VERSION ""

NS_ :

BS_:

BU_:BMS FCS VCU
BO_ 2550595737 BatP9_BMS_ChargingInfo: 8 BMS
 SG_ P9_ChrgrCplrStat : 7|1@0+ (1,0) [0|1] "" VCU
 SG_ P9_HVBattChrgSysStatus : 6|4@0+ (1,0) [0|15] "" VCU
 SG_ P9_DCChrgCrntCmd : 2|9@0+ (1,0) [0|500] "A" VCU
 SG_ P9_CC2Vlt : 9|8@0+ (0.1,0) [0|25] "V" VCU
 SG_ P9_DCRcptPosTemp : 17|9@0+ (0.5,-40) [-40|150] "C" VCU
 SG_ P9_DCRcptNegTemp : 24|9@0+ (0.5,-40) [-40|150] "C" VCU
 SG_ P9_Tm2FullChrg : 47|14@0+ (1,0) [0|65535] "min" VCU

BO_ 2550661273 BatP9_BMS_ThermalManagement: 8 BMS
 SG_ P9_Inlet1ClntTemp : 7|11@0+ (0.1,-40) [-40|150] "C" VCU
 SG_ P9_Inlet2ClntTemp : 12|11@0+ (0.1,-40) [-40|150] "C" VCU
 SG_ P9_Outlet1ClntTemp : 17|11@0+ (0.1,-40) [-40|150] "C" VCU
 SG_ P9_Outlet2ClntTemp : 38|11@0+ (0.1,-40) [-40|150] "C" VCU
 SG_ P9_TrgtClntTemp : 43|11@0+ (0.1,-40) [-40|150] "C" VCU
 SG_ P9_TrgtClntFlowRate : 48|9@0+ (0.2,0) [0|100] "C" VCU

BO_ 2550726809 BatP9_BMS_CellVoltMaxMin: 8 BMS
 SG_ P9_MaxCellVlt : 7|13@0+ (0.001,0) [0|5] "V" VCU
 SG_ P9_MaxCellVltNum : 10|9@0+ (1,0) [0|500] "" VCU
 SG_ P9_MinCellVlt : 17|13@0+ (0.001,0) [0|5] "V" VCU
 SG_ P9_MinCellVltNum : 36|9@0+ (1,0) [0|500] "" VCU
 SG_ P9_AvgCellVlt : 43|13@0+ (0.001,0) [0|5] "V" VCU

BO_ 2550792345 BatP9_BMS_CellTempMaxMin: 8 BMS
 SG_ P9_MaxCellTemp : 7|11@0+ (0.1,-40) [-40|150] "C" VCU
 SG_ P9_MaxCellTempNum : 12|9@0+ (1,0) [0|500] "" VCU
 SG_ P9_MinCellTemp : 19|11@0+ (0.1,-40) [-40|150] "C" VCU
 SG_ P9_MinCellTempNum : 24|9@0+ (1,0) [0|500] "" VCU
 SG_ P9_AvgCellTemp : 47|11@0+ (0.1,-40) [-40|150] "C" VCU

BO_ 2550857881 BatP9_BMS_PackFaultInfo1: 8 BMS
 SG_ P9_PackTotFltNum : 7|8@0+ (1,0) [0|200] "" VCU
 SG_ P9_CellOverVoltage : 15|2@0+ (1,0) [0|3] "" VCU
 SG_ P9_CellUnderVoltage : 13|2@0+ (1,0) [0|3] "" VCU
 SG_ P9_CellVoltageDiffHi : 11|1@0+ (1,0) [0|1] "" VCU
 SG_ P9_PackOverVoltage : 10|2@0+ (1,0) [0|3] "" VCU
 SG_ P9_PackUnderVoltage : 8|2@0+ (1,0) [0|3] "" VCU
 SG_ P9_CellOverTemp : 22|2@0+ (1,0) [0|3] "" VCU
 SG_ P9_CellTempLow : 20|1@0+ (1,0) [0|1] "" VCU
 SG_ P9_CellTempDiffHi : 19|1@0+ (1,0) [0|1] "" VCU
 SG_ P9_PackDschrgCrntHi : 18|2@0+ (1,0) [0|3] "" VCU
 SG_ P9_PackChrgCrntHi : 16|2@0+ (1,0) [0|3] "" VCU
 SG_ P9_PackCrnSnsr1OffsetHi : 30|1@0+ (1,0) [0|1] "" VCU
 SG_ P9_HVIsolFlt : 29|2@0+ (1,0) [0|3] "" VCU
 SG_ P9_HVILFlt : 27|1@0+ (1,0) [0|1] "" VCU
 SG_ P9_ThrmlRunaway : 26|1@0+ (1,0) [0|1] "" VCU
 SG_ P9_CellVoltInvalid : 25|1@0+ (1,0) [0|1] "" VCU
 SG_ P9_CellTempInvalid : 24|1@0+ (1,0) [0|1] "" VCU
 SG_ P9_DaisyChainComFlt : 39|1@0+ (1,0) [0|1] "" VCU
 SG_ P9_PackVoltRatFlt : 38|1@0+ (1,0) [0|1] "" VCU
 SG_ P9_CrntSnsr1Invalid : 37|1@0+ (1,0) [0|1] "" VCU
 SG_ P9_CrntSnsr1OOR : 36|1@0+ (1,0) [0|1] "" VCU
 SG_ P9_CrntSnsr2Invalid : 35|1@0+ (1,0) [0|1] "" VCU
 SG_ P9_CrntSnsr2OOR : 34|1@0+ (1,0) [0|1] "" VCU
 SG_ P9_PackCrnSnsr2OffsetHi : 33|1@0+ (1,0) [0|1] "" VCU
 SG_ P9_OutofEnergy : 32|1@0+ (1,0) [0|1] "" VCU
 SG_ P9_IsolDetCircErr : 47|1@0+ (1,0) [0|1] "" VCU
 SG_ P9_HVILCircShortToGND : 46|1@0+ (1,0) [0|1] "" VCU
 SG_ P9_HVILCircShortToPwr : 45|1@0+ (1,0) [0|1] "" VCU

BO_ 2550923417 BatP9_BMS_PackFaultInfo2: 8 BMS
 SG_ P9_MainPosCntctrStkClsd : 7|1@0+ (1,0) [0|1] "" VCU
 SG_ P9_MainPosCntctrStkOpn : 6|1@0+ (1,0) [0|1] "" VCU
 SG_ P9_MainNegCntctr1StkClsd : 5|1@0+ (1,0) [0|1] "" VCU
 SG_ P9_MainNegCntctr1StkOpn : 4|1@0+ (1,0) [0|1] "" VCU
 SG_ P9_MainNegCntctr2StkClsd : 3|1@0+ (1,0) [0|1] "" VCU
 SG_ P9_MainNegCntctr2StkOpn : 2|1@0+ (1,0) [0|1] "" VCU
 SG_ P9_PrechargTmOut : 1|1@0+ (1,0) [0|1] "" VCU
 SG_ P9_PrechrgCrntHi : 0|1@0+ (1,0) [0|1] "" VCU
 SG_ P9_ChrgCplrPosTempHi : 15|1@0+ (1,0) [0|1] "" VCU
 SG_ P9_ChrgCplrNegTempHi : 14|1@0+ (1,0) [0|1] "" VCU
 SG_ P9_BMSPwrSuplVlt1Hi : 13|1@0+ (1,0) [0|1] "" VCU
 SG_ P9_BMSPwrSuplVlt1Lo : 12|1@0+ (1,0) [0|1] "" VCU
 SG_ P9_BMSPwrSuplVlt2Hi : 11|1@0+ (1,0) [0|1] "" VCU
 SG_ P9_BMSPwrSuplVlt2Lo : 10|1@0+ (1,0) [0|1] "" VCU
 SG_ P9_CntctrCirPwrSuplVltLo : 9|1@0+ (1,0) [0|1] "" VCU
 SG_ P9_CntctrCirPwrSuplVltHi : 8|1@0+ (1,0) [0|1] "" VCU
 SG_ P9_CAN1BusOff : 23|1@0+ (1,0) [0|1] "" VCU
 SG_ P9_CAN1BusTmOut : 22|1@0+ (1,0) [0|1] "" VCU
 SG_ P9_CAN2BusOff : 21|1@0+ (1,0) [0|1] "" VCU
 SG_ P9_CAN2BusTmOut : 20|1@0+ (1,0) [0|1] "" VCU
 SG_ P9_CellBalCircTempHi : 19|1@0+ (1,0) [0|1] "" VCU
 SG_ P9_ClntInTempHi : 18|1@0+ (1,0) [0|1] "" VCU
 SG_ P9_ClntOutTempHi : 17|1@0+ (1,0) [0|1] "" VCU
 SG_ P9_CellExtrmUdrVolt : 16|1@0+ (1,0) [0|1] "" VCU
 SG_ P9_CellExtrmOvrVolt : 31|1@0+ (1,0) [0|1] "" VCU
 SG_ P9_Branch1DischrgCrntHi  : 30|1@0+ (1,0) [0|1] "" VCU
 SG_ P9_Branch2DischrgCrntHi  : 29|1@0+ (1,0) [0|1] "" VCU
 SG_ P9_Branch1ChrgCrntHi  : 28|1@0+ (1,0) [0|1] "" VCU
 SG_ P9_Branch2ChrgCrntHi  : 27|1@0+ (1,0) [0|1] "" VCU
 SG_ P9_InitFailed : 26|1@0+ (1,0) [0|1] "" VCU
 SG_ P9_PackErrCode : 25|10@0+ (1,0) [0|1023] "" VCU

BO_ 2550988953 BatP9_BMS_PackConfigInfo: 8 BMS
 SG_ P9_PackTotCellNum : 7|9@0+ (1,0) [0|500] "" VCU
 SG_ P9_PackTotCellTempSnsrNum : 14|9@0+ (1,0) [0|500] "" VCU

BO_ 2552299673 BatP9_BMS_BMSVersion: 8 BMS
 SG_ P9_BMSASWMajVerNum : 7|8@0+ (1,0) [0|9] "" VCU
 SG_ P9_BMSASWMinVerNum : 15|8@0+ (1,0) [0|99] "" VCU
 SG_ P9_BMSASWPatchVerNum : 23|8@0+ (1,0) [0|255] "" VCU
 SG_ P9_BMSBSWMajVerNum : 31|8@0+ (1,0) [0|9] "" VCU
 SG_ P9_BMSBSWMinVerNum : 39|8@0+ (1,0) [0|99] "" VCU
 SG_ P9_BMSBSWPatchVerNum : 47|8@0+ (1,0) [0|255] "" VCU

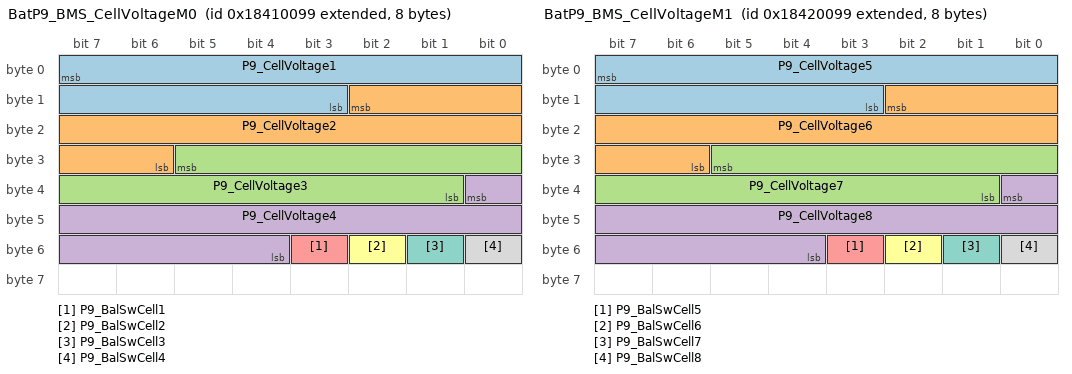
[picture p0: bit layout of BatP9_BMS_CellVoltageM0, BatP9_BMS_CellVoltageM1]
BO_ 2554396825 BatP9_BMS_CellVoltageM0: 8 BMS
 SG_ P9_CellVoltage1 : 7|13@0+ (0.001,0) [0|5] "V" VCU
 SG_ P9_CellVoltage2 : 10|13@0+ (0.001,0) [0|5] "V" VCU
 SG_ P9_CellVoltage3 : 29|13@0+ (0.001,0) [0|5] "V" VCU
 SG_ P9_CellVoltage4 : 32|13@0+ (0.001,0) [0|5] "V" VCU
 SG_ P9_BalSwCell1 : 51|1@0+ (1,0) [0|1] "" VCU
 SG_ P9_BalSwCell2 : 50|1@0+ (1,0) [0|1] "" VCU
 SG_ P9_BalSwCell3 : 49|1@0+ (1,0) [0|1] "" VCU
 SG_ P9_BalSwCell4 : 48|1@0+ (1,0) [0|1] "" VCU

BO_ 2554462361 BatP9_BMS_CellVoltageM1: 8 BMS
 SG_ P9_CellVoltage5 : 7|13@0+ (0.001,0) [0|5] "V" VCU
 SG_ P9_CellVoltage6 : 10|13@0+ (0.001,0) [0|5] "V" VCU
 SG_ P9_CellVoltage7 : 29|13@0+ (0.001,0) [0|5] "V" VCU
 SG_ P9_CellVoltage8 : 32|13@0+ (0.001,0) [0|5] "V" VCU
 SG_ P9_BalSwCell5 : 51|1@0+ (1,0) [0|1] "" VCU
 SG_ P9_BalSwCell6 : 50|1@0+ (1,0) [0|1] "" VCU
 SG_ P9_BalSwCell7 : 49|1@0+ (1,0) [0|1] "" VCU
 SG_ P9_BalSwCell8 : 48|1@0+ (1,0) [0|1] "" VCU

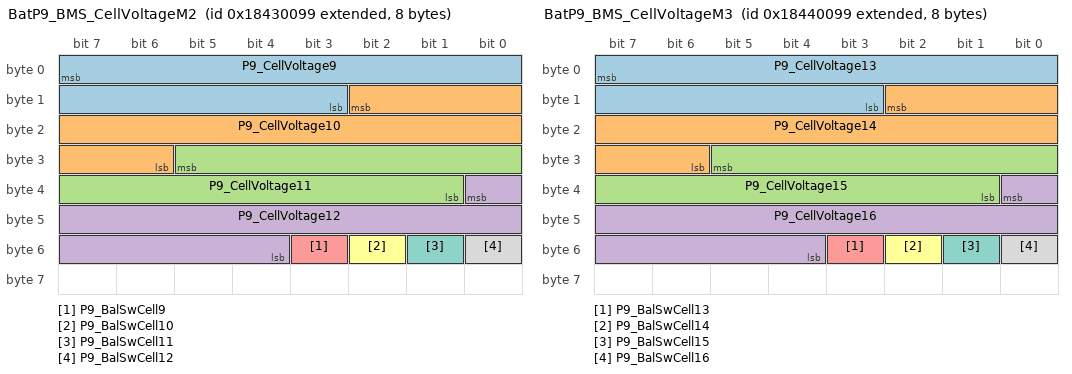
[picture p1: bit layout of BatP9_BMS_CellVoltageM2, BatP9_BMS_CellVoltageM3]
BO_ 2554527897 BatP9_BMS_CellVoltageM2: 8 BMS
 SG_ P9_CellVoltage9 : 7|13@0+ (0.001,0) [0|5] "V" VCU
 SG_ P9_CellVoltage10 : 10|13@0+ (0.001,0) [0|5] "V" VCU
 SG_ P9_CellVoltage11 : 29|13@0+ (0.001,0) [0|5] "V" VCU
 SG_ P9_CellVoltage12 : 32|13@0+ (0.001,0) [0|5] "V" VCU
 SG_ P9_BalSwCell9 : 51|1@0+ (1,0) [0|1] "" VCU
 SG_ P9_BalSwCell10 : 50|1@0+ (1,0) [0|1] "" VCU
 SG_ P9_BalSwCell11 : 49|1@0+ (1,0) [0|1] "" VCU
 SG_ P9_BalSwCell12 : 48|1@0+ (1,0) [0|1] "" VCU

BO_ 2554593433 BatP9_BMS_CellVoltageM3: 8 BMS
 SG_ P9_CellVoltage13 : 7|13@0+ (0.001,0) [0|5] "V" VCU
 SG_ P9_CellVoltage14 : 10|13@0+ (0.001,0) [0|5] "V" VCU
 SG_ P9_CellVoltage15 : 29|13@0+ (0.001,0) [0|5] "V" VCU
 SG_ P9_CellVoltage16 : 32|13@0+ (0.001,0) [0|5] "V" VCU
 SG_ P9_BalSwCell13 : 51|1@0+ (1,0) [0|1] "" VCU
 SG_ P9_BalSwCell14 : 50|1@0+ (1,0) [0|1] "" VCU
 SG_ P9_BalSwCell15 : 49|1@0+ (1,0) [0|1] "" VCU
 SG_ P9_BalSwCell16 : 48|1@0+ (1,0) [0|1] "" VCU

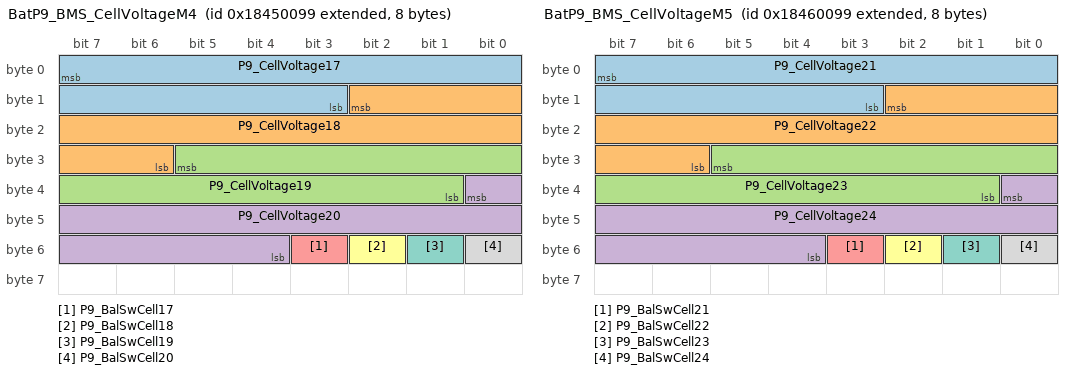
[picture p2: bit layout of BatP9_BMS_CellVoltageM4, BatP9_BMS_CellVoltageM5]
BO_ 2554658969 BatP9_BMS_CellVoltageM4: 8 BMS
 SG_ P9_CellVoltage17 : 7|13@0+ (0.001,0) [0|5] "V" VCU
 SG_ P9_CellVoltage18 : 10|13@0+ (0.001,0) [0|5] "V" VCU
 SG_ P9_CellVoltage19 : 29|13@0+ (0.001,0) [0|5] "V" VCU
 SG_ P9_CellVoltage20 : 32|13@0+ (0.001,0) [0|5] "V" VCU
 SG_ P9_BalSwCell17 : 51|1@0+ (1,0) [0|1] "" VCU
 SG_ P9_BalSwCell18 : 50|1@0+ (1,0) [0|1] "" VCU
 SG_ P9_BalSwCell19 : 49|1@0+ (1,0) [0|1] "" VCU
 SG_ P9_BalSwCell20 : 48|1@0+ (1,0) [0|1] "" VCU

BO_ 2554724505 BatP9_BMS_CellVoltageM5: 8 BMS
 SG_ P9_CellVoltage21 : 7|13@0+ (0.001,0) [0|5] "V" VCU
 SG_ P9_CellVoltage22 : 10|13@0+ (0.001,0) [0|5] "V" VCU
 SG_ P9_CellVoltage23 : 29|13@0+ (0.001,0) [0|5] "V" VCU
 SG_ P9_CellVoltage24 : 32|13@0+ (0.001,0) [0|5] "V" VCU
 SG_ P9_BalSwCell21 : 51|1@0+ (1,0) [0|1] "" VCU
 SG_ P9_BalSwCell22 : 50|1@0+ (1,0) [0|1] "" VCU
 SG_ P9_BalSwCell23 : 49|1@0+ (1,0) [0|1] "" VCU
 SG_ P9_BalSwCell24 : 48|1@0+ (1,0) [0|1] "" VCU

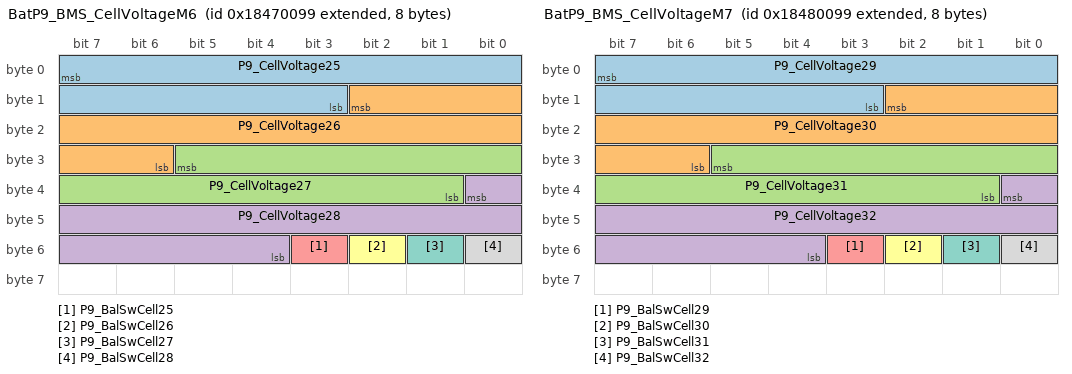
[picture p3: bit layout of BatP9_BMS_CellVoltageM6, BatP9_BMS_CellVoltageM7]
BO_ 2554790041 BatP9_BMS_CellVoltageM6: 8 BMS
 SG_ P9_CellVoltage25 : 7|13@0+ (0.001,0) [0|5] "V" VCU
 SG_ P9_CellVoltage26 : 10|13@0+ (0.001,0) [0|5] "V" VCU
 SG_ P9_CellVoltage27 : 29|13@0+ (0.001,0) [0|5] "V" VCU
 SG_ P9_CellVoltage28 : 32|13@0+ (0.001,0) [0|5] "V" VCU
 SG_ P9_BalSwCell25 : 51|1@0+ (1,0) [0|1] "" VCU
 SG_ P9_BalSwCell26 : 50|1@0+ (1,0) [0|1] "" VCU
 SG_ P9_BalSwCell27 : 49|1@0+ (1,0) [0|1] "" VCU
 SG_ P9_BalSwCell28 : 48|1@0+ (1,0) [0|1] "" VCU

BO_ 2554855577 BatP9_BMS_CellVoltageM7: 8 BMS
 SG_ P9_CellVoltage29 : 7|13@0+ (0.001,0) [0|5] "V" VCU
 SG_ P9_CellVoltage30 : 10|13@0+ (0.001,0) [0|5] "V" VCU
 SG_ P9_CellVoltage31 : 29|13@0+ (0.001,0) [0|5] "V" VCU
 SG_ P9_CellVoltage32 : 32|13@0+ (0.001,0) [0|5] "V" VCU
 SG_ P9_BalSwCell29 : 51|1@0+ (1,0) [0|1] "" VCU
 SG_ P9_BalSwCell30 : 50|1@0+ (1,0) [0|1] "" VCU
 SG_ P9_BalSwCell31 : 49|1@0+ (1,0) [0|1] "" VCU
 SG_ P9_BalSwCell32 : 48|1@0+ (1,0) [0|1] "" VCU

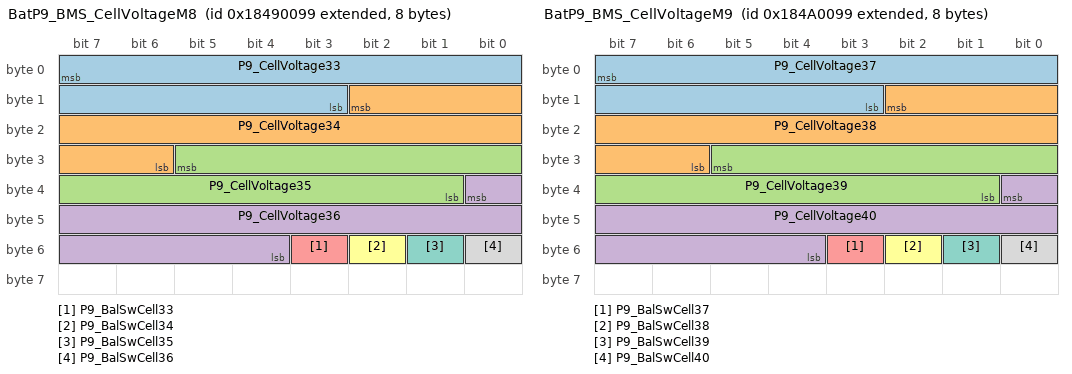
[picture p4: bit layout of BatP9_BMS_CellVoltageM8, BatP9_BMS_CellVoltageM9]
BO_ 2554921113 BatP9_BMS_CellVoltageM8: 8 BMS
 SG_ P9_CellVoltage33 : 7|13@0+ (0.001,0) [0|5] "V" VCU
 SG_ P9_CellVoltage34 : 10|13@0+ (0.001,0) [0|5] "V" VCU
 SG_ P9_CellVoltage35 : 29|13@0+ (0.001,0) [0|5] "V" VCU
 SG_ P9_CellVoltage36 : 32|13@0+ (0.001,0) [0|5] "V" VCU
 SG_ P9_BalSwCell33 : 51|1@0+ (1,0) [0|1] "" VCU
 SG_ P9_BalSwCell34 : 50|1@0+ (1,0) [0|1] "" VCU
 SG_ P9_BalSwCell35 : 49|1@0+ (1,0) [0|1] "" VCU
 SG_ P9_BalSwCell36 : 48|1@0+ (1,0) [0|1] "" VCU

BO_ 2554986649 BatP9_BMS_CellVoltageM9: 8 BMS
 SG_ P9_CellVoltage37 : 7|13@0+ (0.001,0) [0|5] "V" VCU
 SG_ P9_CellVoltage38 : 10|13@0+ (0.001,0) [0|5] "V" VCU
 SG_ P9_CellVoltage39 : 29|13@0+ (0.001,0) [0|5] "V" VCU
 SG_ P9_CellVoltage40 : 32|13@0+ (0.001,0) [0|5] "V" VCU
 SG_ P9_BalSwCell37 : 51|1@0+ (1,0) [0|1] "" VCU
 SG_ P9_BalSwCell38 : 50|1@0+ (1,0) [0|1] "" VCU
 SG_ P9_BalSwCell39 : 49|1@0+ (1,0) [0|1] "" VCU
 SG_ P9_BalSwCell40 : 48|1@0+ (1,0) [0|1] "" VCU

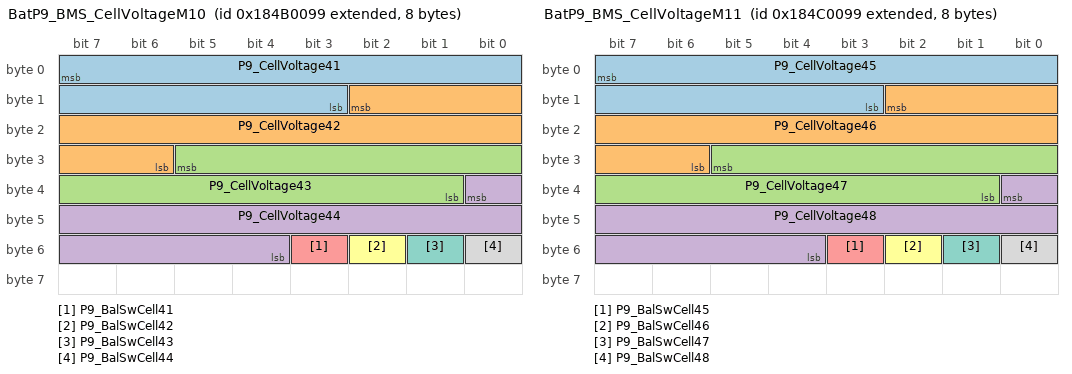
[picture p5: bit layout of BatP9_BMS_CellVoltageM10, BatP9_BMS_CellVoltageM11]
BO_ 2555052185 BatP9_BMS_CellVoltageM10: 8 BMS
 SG_ P9_CellVoltage41 : 7|13@0+ (0.001,0) [0|5] "V" VCU
 SG_ P9_CellVoltage42 : 10|13@0+ (0.001,0) [0|5] "V" VCU
 SG_ P9_CellVoltage43 : 29|13@0+ (0.001,0) [0|5] "V" VCU
 SG_ P9_CellVoltage44 : 32|13@0+ (0.001,0) [0|5] "V" VCU
 SG_ P9_BalSwCell41 : 51|1@0+ (1,0) [0|1] "" VCU
 SG_ P9_BalSwCell42 : 50|1@0+ (1,0) [0|1] "" VCU
 SG_ P9_BalSwCell43 : 49|1@0+ (1,0) [0|1] "" VCU
 SG_ P9_BalSwCell44 : 48|1@0+ (1,0) [0|1] "" VCU

BO_ 2555117721 BatP9_BMS_CellVoltageM11: 8 BMS
 SG_ P9_CellVoltage45 : 7|13@0+ (0.001,0) [0|5] "V" VCU
 SG_ P9_CellVoltage46 : 10|13@0+ (0.001,0) [0|5] "V" VCU
 SG_ P9_CellVoltage47 : 29|13@0+ (0.001,0) [0|5] "V" VCU
 SG_ P9_CellVoltage48 : 32|13@0+ (0.001,0) [0|5] "V" VCU
 SG_ P9_BalSwCell45 : 51|1@0+ (1,0) [0|1] "" VCU
 SG_ P9_BalSwCell46 : 50|1@0+ (1,0) [0|1] "" VCU
 SG_ P9_BalSwCell47 : 49|1@0+ (1,0) [0|1] "" VCU
 SG_ P9_BalSwCell48 : 48|1@0+ (1,0) [0|1] "" VCU

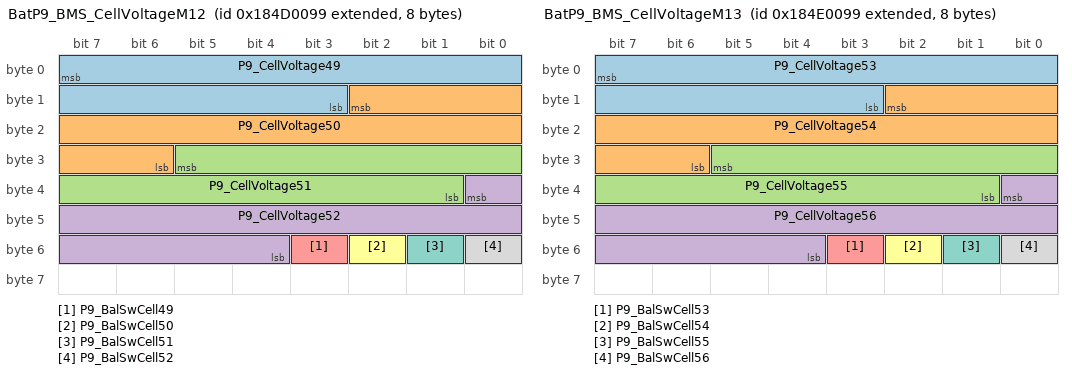
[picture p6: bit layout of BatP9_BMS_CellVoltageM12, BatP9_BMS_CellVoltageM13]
BO_ 2555183257 BatP9_BMS_CellVoltageM12: 8 BMS
 SG_ P9_CellVoltage49 : 7|13@0+ (0.001,0) [0|5] "V" VCU
 SG_ P9_CellVoltage50 : 10|13@0+ (0.001,0) [0|5] "V" VCU
 SG_ P9_CellVoltage51 : 29|13@0+ (0.001,0) [0|5] "V" VCU
 SG_ P9_CellVoltage52 : 32|13@0+ (0.001,0) [0|5] "V" VCU
 SG_ P9_BalSwCell49 : 51|1@0+ (1,0) [0|1] "" VCU
 SG_ P9_BalSwCell50 : 50|1@0+ (1,0) [0|1] "" VCU
 SG_ P9_BalSwCell51 : 49|1@0+ (1,0) [0|1] "" VCU
 SG_ P9_BalSwCell52 : 48|1@0+ (1,0) [0|1] "" VCU

BO_ 2555248793 BatP9_BMS_CellVoltageM13: 8 BMS
 SG_ P9_CellVoltage53 : 7|13@0+ (0.001,0) [0|5] "V" VCU
 SG_ P9_CellVoltage54 : 10|13@0+ (0.001,0) [0|5] "V" VCU
 SG_ P9_CellVoltage55 : 29|13@0+ (0.001,0) [0|5] "V" VCU
 SG_ P9_CellVoltage56 : 32|13@0+ (0.001,0) [0|5] "V" VCU
 SG_ P9_BalSwCell53 : 51|1@0+ (1,0) [0|1] "" VCU
 SG_ P9_BalSwCell54 : 50|1@0+ (1,0) [0|1] "" VCU
 SG_ P9_BalSwCell55 : 49|1@0+ (1,0) [0|1] "" VCU
 SG_ P9_BalSwCell56 : 48|1@0+ (1,0) [0|1] "" VCU

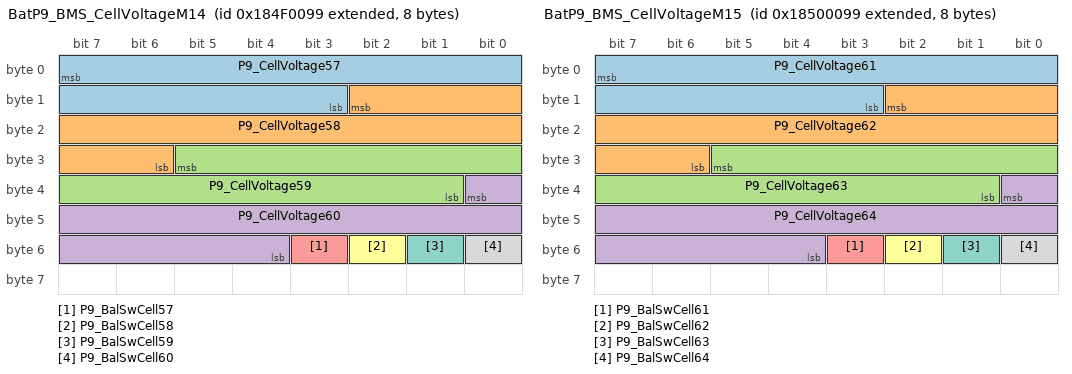
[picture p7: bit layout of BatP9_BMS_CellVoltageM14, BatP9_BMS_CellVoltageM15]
BO_ 2555314329 BatP9_BMS_CellVoltageM14: 8 BMS
 SG_ P9_CellVoltage57 : 7|13@0+ (0.001,0) [0|5] "V" VCU
 SG_ P9_CellVoltage58 : 10|13@0+ (0.001,0) [0|5] "V" VCU
 SG_ P9_CellVoltage59 : 29|13@0+ (0.001,0) [0|5] "V" VCU
 SG_ P9_CellVoltage60 : 32|13@0+ (0.001,0) [0|5] "V" VCU
 SG_ P9_BalSwCell57 : 51|1@0+ (1,0) [0|1] "" VCU
 SG_ P9_BalSwCell58 : 50|1@0+ (1,0) [0|1] "" VCU
 SG_ P9_BalSwCell59 : 49|1@0+ (1,0) [0|1] "" VCU
 SG_ P9_BalSwCell60 : 48|1@0+ (1,0) [0|1] "" VCU

BO_ 2555379865 BatP9_BMS_CellVoltageM15: 8 BMS
 SG_ P9_CellVoltage61 : 7|13@0+ (0.001,0) [0|5] "V" VCU
 SG_ P9_CellVoltage62 : 10|13@0+ (0.001,0) [0|5] "V" VCU
 SG_ P9_CellVoltage63 : 29|13@0+ (0.001,0) [0|5] "V" VCU
 SG_ P9_CellVoltage64 : 32|13@0+ (0.001,0) [0|5] "V" VCU
 SG_ P9_BalSwCell61 : 51|1@0+ (1,0) [0|1] "" VCU
 SG_ P9_BalSwCell62 : 50|1@0+ (1,0) [0|1] "" VCU
 SG_ P9_BalSwCell63 : 49|1@0+ (1,0) [0|1] "" VCU
 SG_ P9_BalSwCell64 : 48|1@0+ (1,0) [0|1] "" VCU

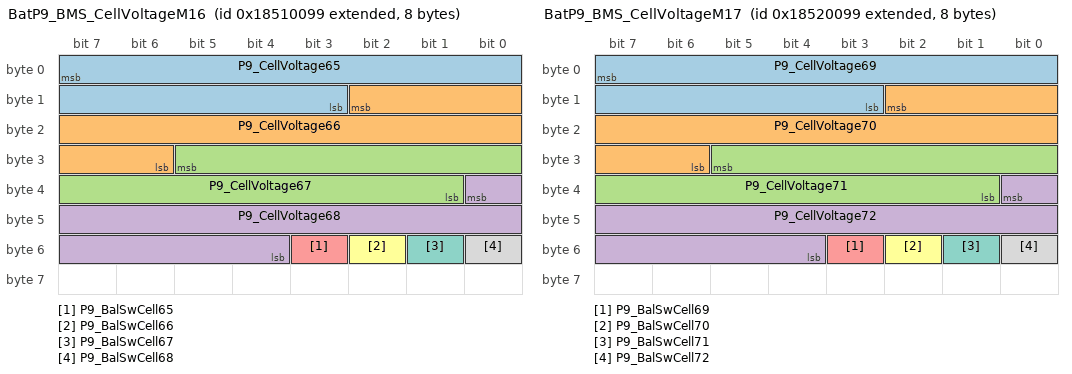
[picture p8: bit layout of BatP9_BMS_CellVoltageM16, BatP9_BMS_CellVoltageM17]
BO_ 2555445401 BatP9_BMS_CellVoltageM16: 8 BMS
 SG_ P9_CellVoltage65 : 7|13@0+ (0.001,0) [0|5] "V" VCU
 SG_ P9_CellVoltage66 : 10|13@0+ (0.001,0) [0|5] "V" VCU
 SG_ P9_CellVoltage67 : 29|13@0+ (0.001,0) [0|5] "V" VCU
 SG_ P9_CellVoltage68 : 32|13@0+ (0.001,0) [0|5] "V" VCU
 SG_ P9_BalSwCell65 : 51|1@0+ (1,0) [0|1] "" VCU
 SG_ P9_BalSwCell66 : 50|1@0+ (1,0) [0|1] "" VCU
 SG_ P9_BalSwCell67 : 49|1@0+ (1,0) [0|1] "" VCU
 SG_ P9_BalSwCell68 : 48|1@0+ (1,0) [0|1] "" VCU

BO_ 2555510937 BatP9_BMS_CellVoltageM17: 8 BMS
 SG_ P9_CellVoltage69 : 7|13@0+ (0.001,0) [0|5] "V" VCU
 SG_ P9_CellVoltage70 : 10|13@0+ (0.001,0) [0|5] "V" VCU
 SG_ P9_CellVoltage71 : 29|13@0+ (0.001,0) [0|5] "V" VCU
 SG_ P9_CellVoltage72 : 32|13@0+ (0.001,0) [0|5] "V" VCU
 SG_ P9_BalSwCell69 : 51|1@0+ (1,0) [0|1] "" VCU
 SG_ P9_BalSwCell70 : 50|1@0+ (1,0) [0|1] "" VCU
 SG_ P9_BalSwCell71 : 49|1@0+ (1,0) [0|1] "" VCU
 SG_ P9_BalSwCell72 : 48|1@0+ (1,0) [0|1] "" VCU

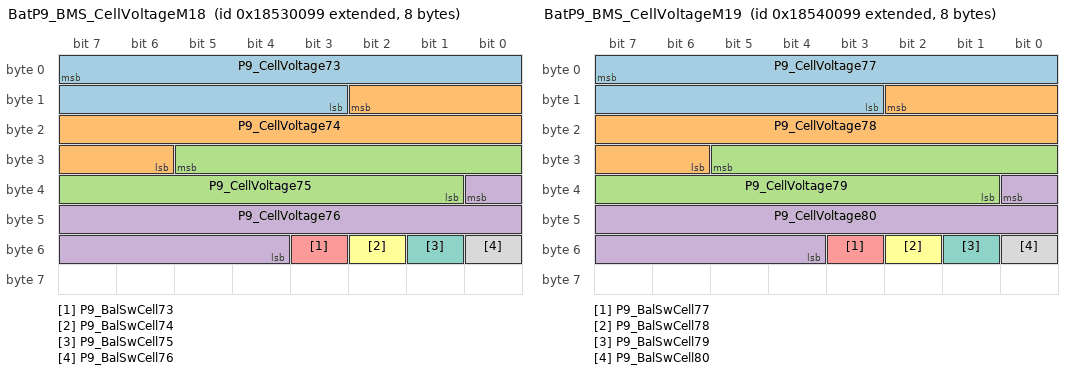
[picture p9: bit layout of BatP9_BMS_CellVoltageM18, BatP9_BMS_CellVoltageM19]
BO_ 2555576473 BatP9_BMS_CellVoltageM18: 8 BMS
 SG_ P9_CellVoltage73 : 7|13@0+ (0.001,0) [0|5] "V" VCU
 SG_ P9_CellVoltage74 : 10|13@0+ (0.001,0) [0|5] "V" VCU
 SG_ P9_CellVoltage75 : 29|13@0+ (0.001,0) [0|5] "V" VCU
 SG_ P9_CellVoltage76 : 32|13@0+ (0.001,0) [0|5] "V" VCU
 SG_ P9_BalSwCell73 : 51|1@0+ (1,0) [0|1] "" VCU
 SG_ P9_BalSwCell74 : 50|1@0+ (1,0) [0|1] "" VCU
 SG_ P9_BalSwCell75 : 49|1@0+ (1,0) [0|1] "" VCU
 SG_ P9_BalSwCell76 : 48|1@0+ (1,0) [0|1] "" VCU

BO_ 2555642009 BatP9_BMS_CellVoltageM19: 8 BMS
 SG_ P9_CellVoltage77 : 7|13@0+ (0.001,0) [0|5] "V" VCU
 SG_ P9_CellVoltage78 : 10|13@0+ (0.001,0) [0|5] "V" VCU
 SG_ P9_CellVoltage79 : 29|13@0+ (0.001,0) [0|5] "V" VCU
 SG_ P9_CellVoltage80 : 32|13@0+ (0.001,0) [0|5] "V" VCU
 SG_ P9_BalSwCell77 : 51|1@0+ (1,0) [0|1] "" VCU
 SG_ P9_BalSwCell78 : 50|1@0+ (1,0) [0|1] "" VCU
 SG_ P9_BalSwCell79 : 49|1@0+ (1,0) [0|1] "" VCU
 SG_ P9_BalSwCell80 : 48|1@0+ (1,0) [0|1] "" VCU

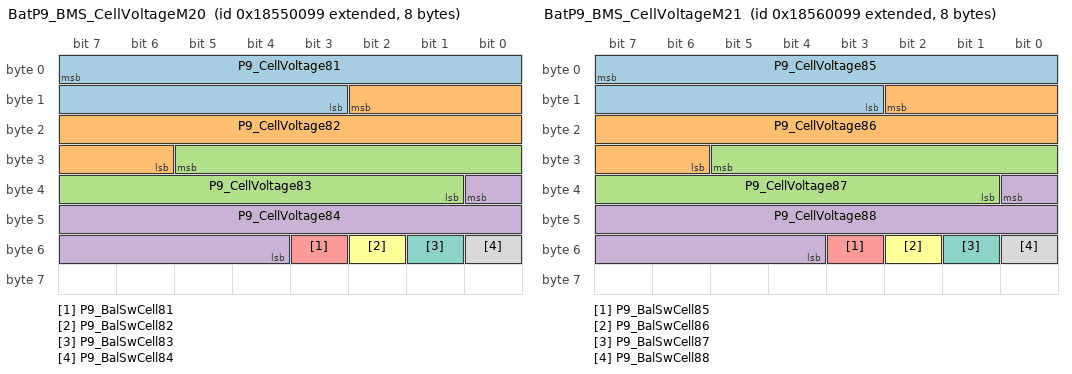
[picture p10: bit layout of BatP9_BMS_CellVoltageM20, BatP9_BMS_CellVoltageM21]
BO_ 2555707545 BatP9_BMS_CellVoltageM20: 8 BMS
 SG_ P9_CellVoltage81 : 7|13@0+ (0.001,0) [0|5] "V" VCU
 SG_ P9_CellVoltage82 : 10|13@0+ (0.001,0) [0|5] "V" VCU
 SG_ P9_CellVoltage83 : 29|13@0+ (0.001,0) [0|5] "V" VCU
 SG_ P9_CellVoltage84 : 32|13@0+ (0.001,0) [0|5] "V" VCU
 SG_ P9_BalSwCell81 : 51|1@0+ (1,0) [0|1] "" VCU
 SG_ P9_BalSwCell82 : 50|1@0+ (1,0) [0|1] "" VCU
 SG_ P9_BalSwCell83 : 49|1@0+ (1,0) [0|1] "" VCU
 SG_ P9_BalSwCell84 : 48|1@0+ (1,0) [0|1] "" VCU

BO_ 2555773081 BatP9_BMS_CellVoltageM21: 8 BMS
 SG_ P9_CellVoltage85 : 7|13@0+ (0.001,0) [0|5] "V" VCU
 SG_ P9_CellVoltage86 : 10|13@0+ (0.001,0) [0|5] "V" VCU
 SG_ P9_CellVoltage87 : 29|13@0+ (0.001,0) [0|5] "V" VCU
 SG_ P9_CellVoltage88 : 32|13@0+ (0.001,0) [0|5] "V" VCU
 SG_ P9_BalSwCell85 : 51|1@0+ (1,0) [0|1] "" VCU
 SG_ P9_BalSwCell86 : 50|1@0+ (1,0) [0|1] "" VCU
 SG_ P9_BalSwCell87 : 49|1@0+ (1,0) [0|1] "" VCU
 SG_ P9_BalSwCell88 : 48|1@0+ (1,0) [0|1] "" VCU

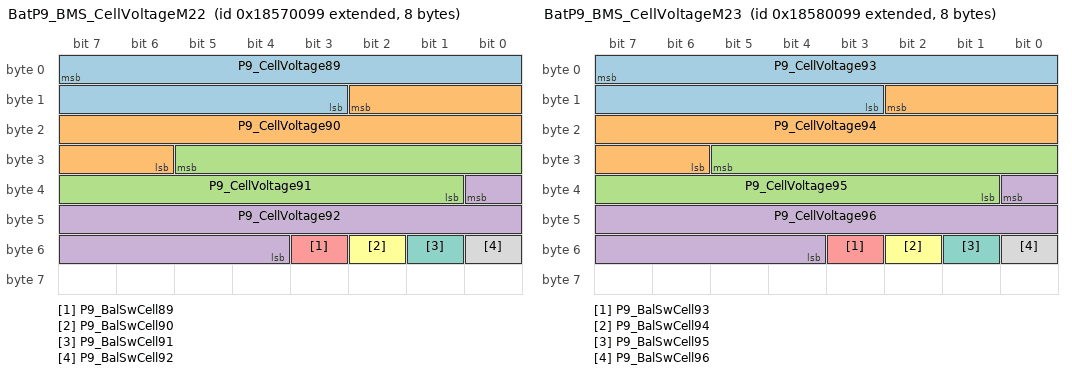
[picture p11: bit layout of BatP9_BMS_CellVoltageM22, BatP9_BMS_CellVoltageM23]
BO_ 2555838617 BatP9_BMS_CellVoltageM22: 8 BMS
 SG_ P9_CellVoltage89 : 7|13@0+ (0.001,0) [0|5] "V" VCU
 SG_ P9_CellVoltage90 : 10|13@0+ (0.001,0) [0|5] "V" VCU
 SG_ P9_CellVoltage91 : 29|13@0+ (0.001,0) [0|5] "V" VCU
 SG_ P9_CellVoltage92 : 32|13@0+ (0.001,0) [0|5] "V" VCU
 SG_ P9_BalSwCell89 : 51|1@0+ (1,0) [0|1] "" VCU
 SG_ P9_BalSwCell90 : 50|1@0+ (1,0) [0|1] "" VCU
 SG_ P9_BalSwCell91 : 49|1@0+ (1,0) [0|1] "" VCU
 SG_ P9_BalSwCell92 : 48|1@0+ (1,0) [0|1] "" VCU

BO_ 2555904153 BatP9_BMS_CellVoltageM23: 8 BMS
 SG_ P9_CellVoltage93 : 7|13@0+ (0.001,0) [0|5] "V" VCU
 SG_ P9_CellVoltage94 : 10|13@0+ (0.001,0) [0|5] "V" VCU
 SG_ P9_CellVoltage95 : 29|13@0+ (0.001,0) [0|5] "V" VCU
 SG_ P9_CellVoltage96 : 32|13@0+ (0.001,0) [0|5] "V" VCU
 SG_ P9_BalSwCell93 : 51|1@0+ (1,0) [0|1] "" VCU
 SG_ P9_BalSwCell94 : 50|1@0+ (1,0) [0|1] "" VCU
 SG_ P9_BalSwCell95 : 49|1@0+ (1,0) [0|1] "" VCU
 SG_ P9_BalSwCell96 : 48|1@0+ (1,0) [0|1] "" VCU

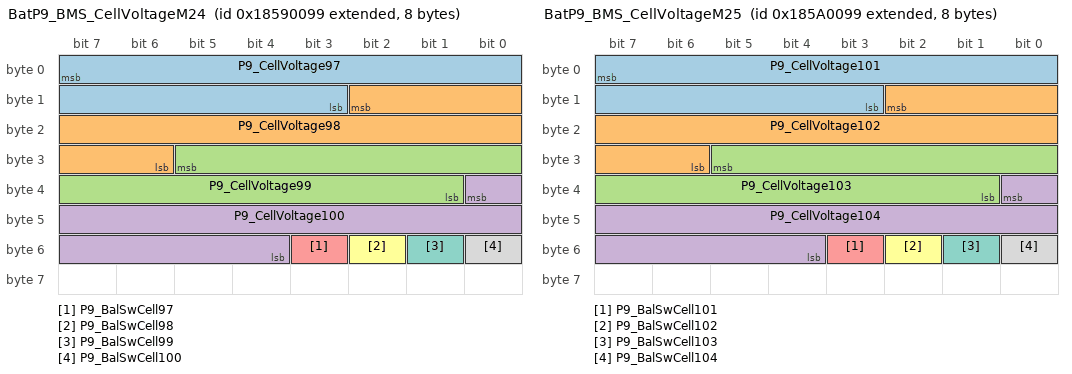
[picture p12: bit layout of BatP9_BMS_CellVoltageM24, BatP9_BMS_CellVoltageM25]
BO_ 2555969689 BatP9_BMS_CellVoltageM24: 8 BMS
 SG_ P9_CellVoltage97 : 7|13@0+ (0.001,0) [0|5] "V" VCU
 SG_ P9_CellVoltage98 : 10|13@0+ (0.001,0) [0|5] "V" VCU
 SG_ P9_CellVoltage99 : 29|13@0+ (0.001,0) [0|5] "V" VCU
 SG_ P9_CellVoltage100 : 32|13@0+ (0.001,0) [0|5] "V" VCU
 SG_ P9_BalSwCell97 : 51|1@0+ (1,0) [0|1] "" VCU
 SG_ P9_BalSwCell98 : 50|1@0+ (1,0) [0|1] "" VCU
 SG_ P9_BalSwCell99 : 49|1@0+ (1,0) [0|1] "" VCU
 SG_ P9_BalSwCell100 : 48|1@0+ (1,0) [0|1] "" VCU

BO_ 2556035225 BatP9_BMS_CellVoltageM25: 8 BMS
 SG_ P9_CellVoltage101 : 7|13@0+ (0.001,0) [0|5] "V" VCU
 SG_ P9_CellVoltage102 : 10|13@0+ (0.001,0) [0|5] "V" VCU
 SG_ P9_CellVoltage103 : 29|13@0+ (0.001,0) [0|5] "V" VCU
 SG_ P9_CellVoltage104 : 32|13@0+ (0.001,0) [0|5] "V" VCU
 SG_ P9_BalSwCell101 : 51|1@0+ (1,0) [0|1] "" VCU
 SG_ P9_BalSwCell102 : 50|1@0+ (1,0) [0|1] "" VCU
 SG_ P9_BalSwCell103 : 49|1@0+ (1,0) [0|1] "" VCU
 SG_ P9_BalSwCell104 : 48|1@0+ (1,0) [0|1] "" VCU

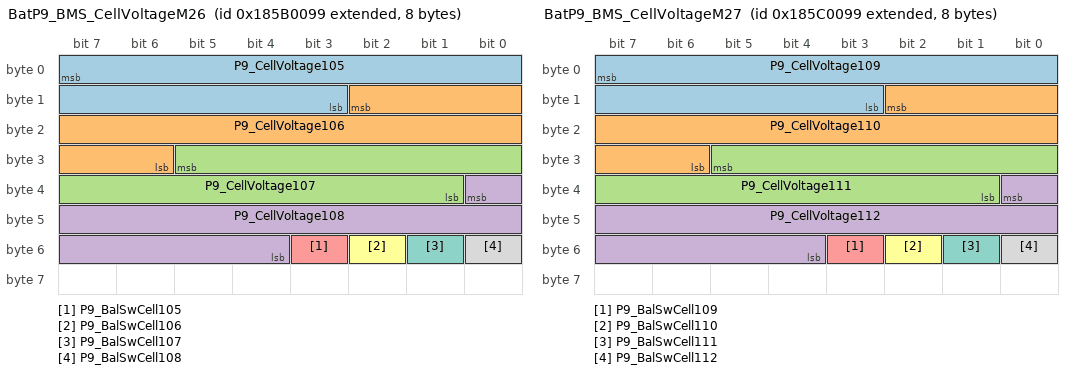
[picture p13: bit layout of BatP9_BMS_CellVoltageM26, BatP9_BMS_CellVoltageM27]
BO_ 2556100761 BatP9_BMS_CellVoltageM26: 8 BMS
 SG_ P9_CellVoltage105 : 7|13@0+ (0.001,0) [0|5] "V" VCU
 SG_ P9_CellVoltage106 : 10|13@0+ (0.001,0) [0|5] "V" VCU
 SG_ P9_CellVoltage107 : 29|13@0+ (0.001,0) [0|5] "V" VCU
 SG_ P9_CellVoltage108 : 32|13@0+ (0.001,0) [0|5] "V" VCU
 SG_ P9_BalSwCell105 : 51|1@0+ (1,0) [0|1] "" VCU
 SG_ P9_BalSwCell106 : 50|1@0+ (1,0) [0|1] "" VCU
 SG_ P9_BalSwCell107 : 49|1@0+ (1,0) [0|1] "" VCU
 SG_ P9_BalSwCell108 : 48|1@0+ (1,0) [0|1] "" VCU

BO_ 2556166297 BatP9_BMS_CellVoltageM27: 8 BMS
 SG_ P9_CellVoltage109 : 7|13@0+ (0.001,0) [0|5] "V" VCU
 SG_ P9_CellVoltage110 : 10|13@0+ (0.001,0) [0|5] "V" VCU
 SG_ P9_CellVoltage111 : 29|13@0+ (0.001,0) [0|5] "V" VCU
 SG_ P9_CellVoltage112 : 32|13@0+ (0.001,0) [0|5] "V" VCU
 SG_ P9_BalSwCell109 : 51|1@0+ (1,0) [0|1] "" VCU
 SG_ P9_BalSwCell110 : 50|1@0+ (1,0) [0|1] "" VCU
 SG_ P9_BalSwCell111 : 49|1@0+ (1,0) [0|1] "" VCU
 SG_ P9_BalSwCell112 : 48|1@0+ (1,0) [0|1] "" VCU

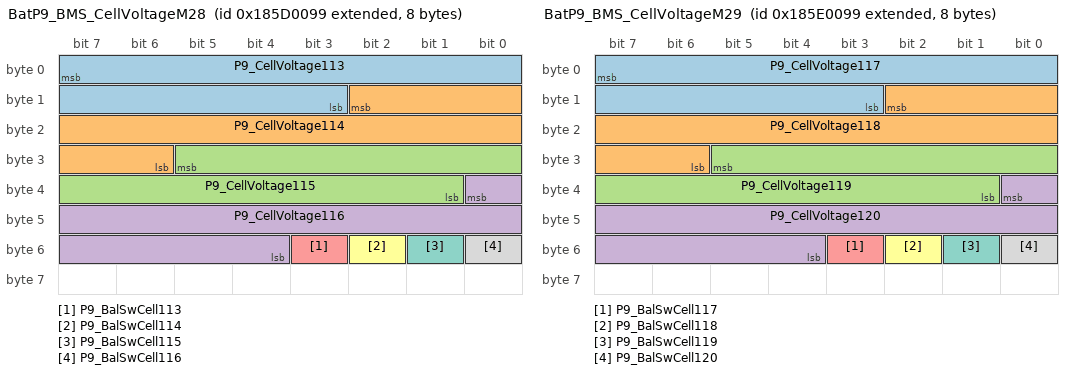
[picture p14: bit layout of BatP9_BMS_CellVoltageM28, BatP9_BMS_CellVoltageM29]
BO_ 2556231833 BatP9_BMS_CellVoltageM28: 8 BMS
 SG_ P9_CellVoltage113 : 7|13@0+ (0.001,0) [0|5] "V" VCU
 SG_ P9_CellVoltage114 : 10|13@0+ (0.001,0) [0|5] "V" VCU
 SG_ P9_CellVoltage115 : 29|13@0+ (0.001,0) [0|5] "V" VCU
 SG_ P9_CellVoltage116 : 32|13@0+ (0.001,0) [0|5] "V" VCU
 SG_ P9_BalSwCell113 : 51|1@0+ (1,0) [0|1] "" VCU
 SG_ P9_BalSwCell114 : 50|1@0+ (1,0) [0|1] "" VCU
 SG_ P9_BalSwCell115 : 49|1@0+ (1,0) [0|1] "" VCU
 SG_ P9_BalSwCell116 : 48|1@0+ (1,0) [0|1] "" VCU

BO_ 2556297369 BatP9_BMS_CellVoltageM29: 8 BMS
 SG_ P9_CellVoltage117 : 7|13@0+ (0.001,0) [0|5] "V" VCU
 SG_ P9_CellVoltage118 : 10|13@0+ (0.001,0) [0|5] "V" VCU
 SG_ P9_CellVoltage119 : 29|13@0+ (0.001,0) [0|5] "V" VCU
 SG_ P9_CellVoltage120 : 32|13@0+ (0.001,0) [0|5] "V" VCU
 SG_ P9_BalSwCell117 : 51|1@0+ (1,0) [0|1] "" VCU
 SG_ P9_BalSwCell118 : 50|1@0+ (1,0) [0|1] "" VCU
 SG_ P9_BalSwCell119 : 49|1@0+ (1,0) [0|1] "" VCU
 SG_ P9_BalSwCell120 : 48|1@0+ (1,0) [0|1] "" VCU

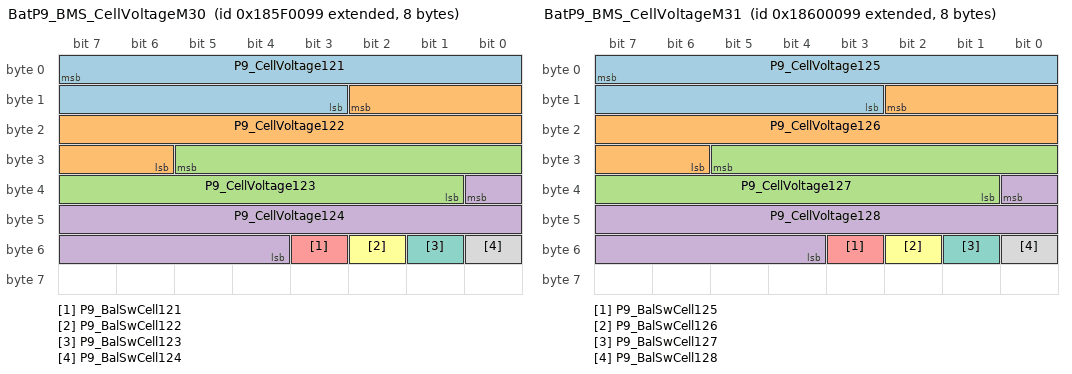
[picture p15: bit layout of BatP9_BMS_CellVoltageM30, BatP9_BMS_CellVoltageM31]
BO_ 2556362905 BatP9_BMS_CellVoltageM30: 8 BMS
 SG_ P9_CellVoltage121 : 7|13@0+ (0.001,0) [0|5] "V" VCU
 SG_ P9_CellVoltage122 : 10|13@0+ (0.001,0) [0|5] "V" VCU
 SG_ P9_CellVoltage123 : 29|13@0+ (0.001,0) [0|5] "V" VCU
 SG_ P9_CellVoltage124 : 32|13@0+ (0.001,0) [0|5] "V" VCU
 SG_ P9_BalSwCell121 : 51|1@0+ (1,0) [0|1] "" VCU
 SG_ P9_BalSwCell122 : 50|1@0+ (1,0) [0|1] "" VCU
 SG_ P9_BalSwCell123 : 49|1@0+ (1,0) [0|1] "" VCU
 SG_ P9_BalSwCell124 : 48|1@0+ (1,0) [0|1] "" VCU

BO_ 2556428441 BatP9_BMS_CellVoltageM31: 8 BMS
 SG_ P9_CellVoltage125 : 7|13@0+ (0.001,0) [0|5] "V" VCU
 SG_ P9_CellVoltage126 : 10|13@0+ (0.001,0) [0|5] "V" VCU
 SG_ P9_CellVoltage127 : 29|13@0+ (0.001,0) [0|5] "V" VCU
 SG_ P9_CellVoltage128 : 32|13@0+ (0.001,0) [0|5] "V" VCU
 SG_ P9_BalSwCell125 : 51|1@0+ (1,0) [0|1] "" VCU
 SG_ P9_BalSwCell126 : 50|1@0+ (1,0) [0|1] "" VCU
 SG_ P9_BalSwCell127 : 49|1@0+ (1,0) [0|1] "" VCU
 SG_ P9_BalSwCell128 : 48|1@0+ (1,0) [0|1] "" VCU

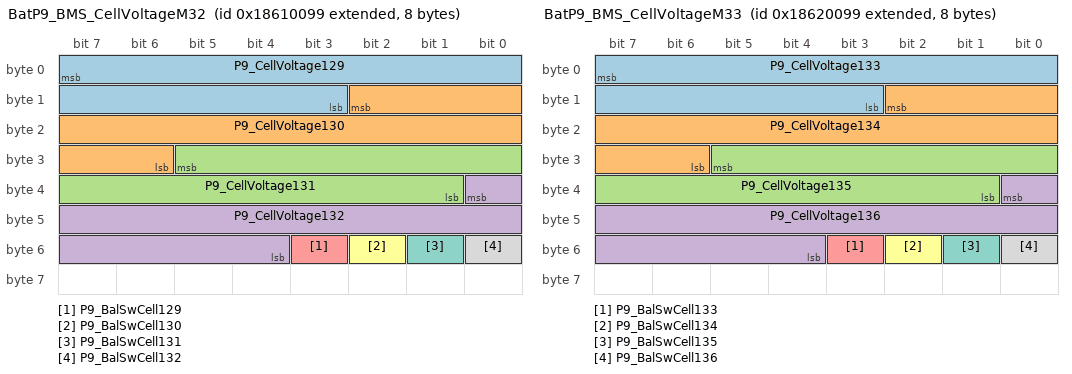
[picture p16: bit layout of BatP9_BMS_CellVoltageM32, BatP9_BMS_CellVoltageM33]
BO_ 2556493977 BatP9_BMS_CellVoltageM32: 8 BMS
 SG_ P9_CellVoltage129 : 7|13@0+ (0.001,0) [0|5] "V" VCU
 SG_ P9_CellVoltage130 : 10|13@0+ (0.001,0) [0|5] "V" VCU
 SG_ P9_CellVoltage131 : 29|13@0+ (0.001,0) [0|5] "V" VCU
 SG_ P9_CellVoltage132 : 32|13@0+ (0.001,0) [0|5] "V" VCU
 SG_ P9_BalSwCell129 : 51|1@0+ (1,0) [0|1] "" VCU
 SG_ P9_BalSwCell130 : 50|1@0+ (1,0) [0|1] "" VCU
 SG_ P9_BalSwCell131 : 49|1@0+ (1,0) [0|1] "" VCU
 SG_ P9_BalSwCell132 : 48|1@0+ (1,0) [0|1] "" VCU

BO_ 2556559513 BatP9_BMS_CellVoltageM33: 8 BMS
 SG_ P9_CellVoltage133 : 7|13@0+ (0.001,0) [0|5] "V" VCU
 SG_ P9_CellVoltage134 : 10|13@0+ (0.001,0) [0|5] "V" VCU
 SG_ P9_CellVoltage135 : 29|13@0+ (0.001,0) [0|5] "V" VCU
 SG_ P9_CellVoltage136 : 32|13@0+ (0.001,0) [0|5] "V" VCU
 SG_ P9_BalSwCell133 : 51|1@0+ (1,0) [0|1] "" VCU
 SG_ P9_BalSwCell134 : 50|1@0+ (1,0) [0|1] "" VCU
 SG_ P9_BalSwCell135 : 49|1@0+ (1,0) [0|1] "" VCU
 SG_ P9_BalSwCell136 : 48|1@0+ (1,0) [0|1] "" VCU

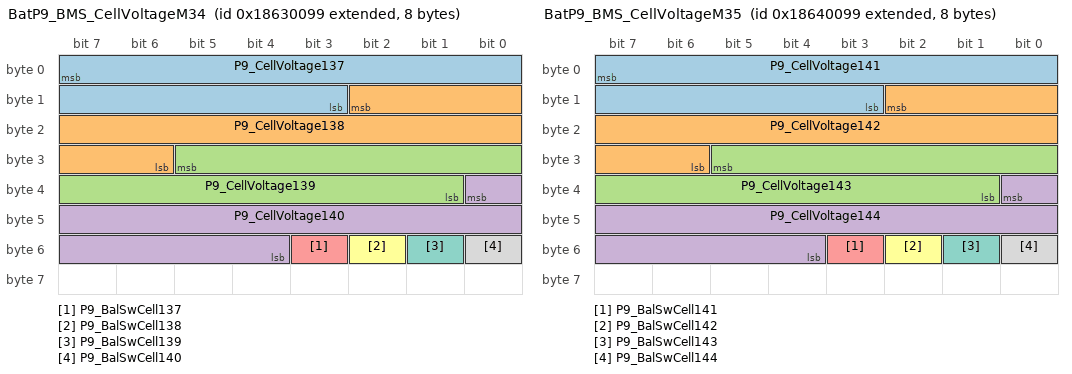
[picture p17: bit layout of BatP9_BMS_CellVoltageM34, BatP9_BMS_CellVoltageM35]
BO_ 2556625049 BatP9_BMS_CellVoltageM34: 8 BMS
 SG_ P9_CellVoltage137 : 7|13@0+ (0.001,0) [0|5] "V" VCU
 SG_ P9_CellVoltage138 : 10|13@0+ (0.001,0) [0|5] "V" VCU
 SG_ P9_CellVoltage139 : 29|13@0+ (0.001,0) [0|5] "V" VCU
 SG_ P9_CellVoltage140 : 32|13@0+ (0.001,0) [0|5] "V" VCU
 SG_ P9_BalSwCell137 : 51|1@0+ (1,0) [0|1] "" VCU
 SG_ P9_BalSwCell138 : 50|1@0+ (1,0) [0|1] "" VCU
 SG_ P9_BalSwCell139 : 49|1@0+ (1,0) [0|1] "" VCU
 SG_ P9_BalSwCell140 : 48|1@0+ (1,0) [0|1] "" VCU

BO_ 2556690585 BatP9_BMS_CellVoltageM35: 8 BMS
 SG_ P9_CellVoltage141 : 7|13@0+ (0.001,0) [0|5] "V" VCU
 SG_ P9_CellVoltage142 : 10|13@0+ (0.001,0) [0|5] "V" VCU
 SG_ P9_CellVoltage143 : 29|13@0+ (0.001,0) [0|5] "V" VCU
 SG_ P9_CellVoltage144 : 32|13@0+ (0.001,0) [0|5] "V" VCU
 SG_ P9_BalSwCell141 : 51|1@0+ (1,0) [0|1] "" VCU
 SG_ P9_BalSwCell142 : 50|1@0+ (1,0) [0|1] "" VCU
 SG_ P9_BalSwCell143 : 49|1@0+ (1,0) [0|1] "" VCU
 SG_ P9_BalSwCell144 : 48|1@0+ (1,0) [0|1] "" VCU

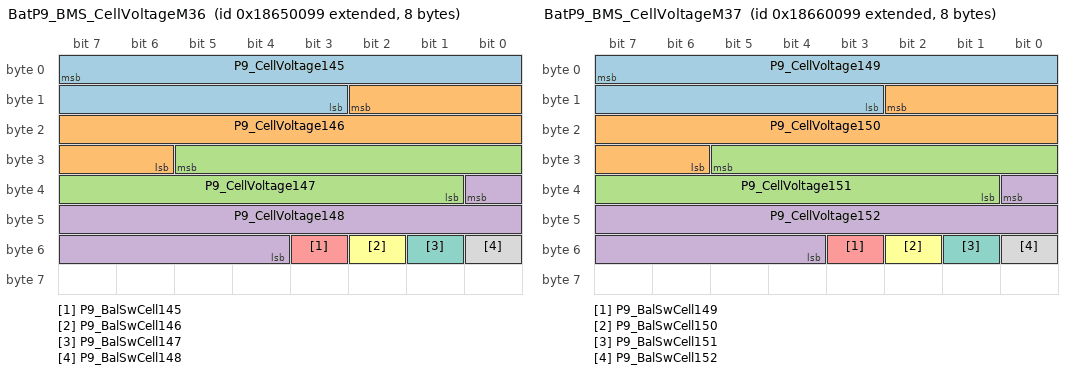
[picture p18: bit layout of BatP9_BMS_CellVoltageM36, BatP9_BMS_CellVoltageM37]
BO_ 2556756121 BatP9_BMS_CellVoltageM36: 8 BMS
 SG_ P9_CellVoltage145 : 7|13@0+ (0.001,0) [0|5] "V" VCU
 SG_ P9_CellVoltage146 : 10|13@0+ (0.001,0) [0|5] "V" VCU
 SG_ P9_CellVoltage147 : 29|13@0+ (0.001,0) [0|5] "V" VCU
 SG_ P9_CellVoltage148 : 32|13@0+ (0.001,0) [0|5] "V" VCU
 SG_ P9_BalSwCell145 : 51|1@0+ (1,0) [0|1] "" VCU
 SG_ P9_BalSwCell146 : 50|1@0+ (1,0) [0|1] "" VCU
 SG_ P9_BalSwCell147 : 49|1@0+ (1,0) [0|1] "" VCU
 SG_ P9_BalSwCell148 : 48|1@0+ (1,0) [0|1] "" VCU

BO_ 2556821657 BatP9_BMS_CellVoltageM37: 8 BMS
 SG_ P9_CellVoltage149 : 7|13@0+ (0.001,0) [0|5] "V" VCU
 SG_ P9_CellVoltage150 : 10|13@0+ (0.001,0) [0|5] "V" VCU
 SG_ P9_CellVoltage151 : 29|13@0+ (0.001,0) [0|5] "V" VCU
 SG_ P9_CellVoltage152 : 32|13@0+ (0.001,0) [0|5] "V" VCU
 SG_ P9_BalSwCell149 : 51|1@0+ (1,0) [0|1] "" VCU
 SG_ P9_BalSwCell150 : 50|1@0+ (1,0) [0|1] "" VCU
 SG_ P9_BalSwCell151 : 49|1@0+ (1,0) [0|1] "" VCU
 SG_ P9_BalSwCell152 : 48|1@0+ (1,0) [0|1] "" VCU

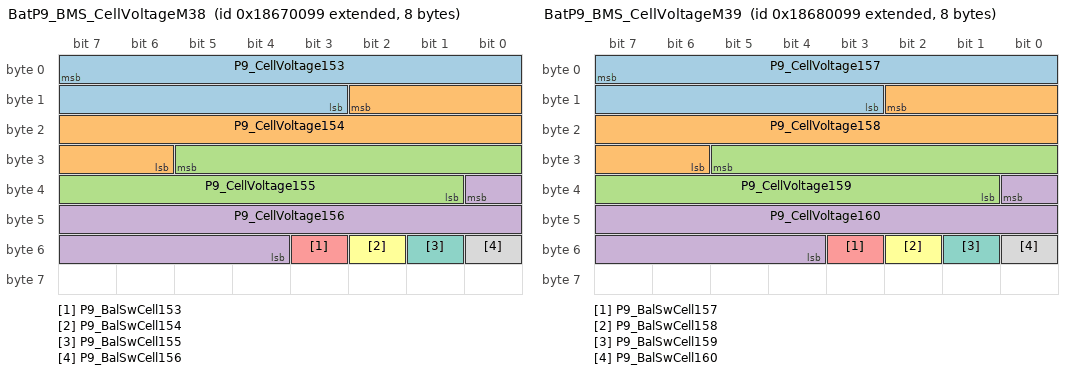
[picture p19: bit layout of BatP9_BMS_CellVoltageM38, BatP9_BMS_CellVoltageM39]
BO_ 2556887193 BatP9_BMS_CellVoltageM38: 8 BMS
 SG_ P9_CellVoltage153 : 7|13@0+ (0.001,0) [0|5] "V" VCU
 SG_ P9_CellVoltage154 : 10|13@0+ (0.001,0) [0|5] "V" VCU
 SG_ P9_CellVoltage155 : 29|13@0+ (0.001,0) [0|5] "V" VCU
 SG_ P9_CellVoltage156 : 32|13@0+ (0.001,0) [0|5] "V" VCU
 SG_ P9_BalSwCell153 : 51|1@0+ (1,0) [0|1] "" VCU
 SG_ P9_BalSwCell154 : 50|1@0+ (1,0) [0|1] "" VCU
 SG_ P9_BalSwCell155 : 49|1@0+ (1,0) [0|1] "" VCU
 SG_ P9_BalSwCell156 : 48|1@0+ (1,0) [0|1] "" VCU

BO_ 2556952729 BatP9_BMS_CellVoltageM39: 8 BMS
 SG_ P9_CellVoltage157 : 7|13@0+ (0.001,0) [0|5] "V" VCU
 SG_ P9_CellVoltage158 : 10|13@0+ (0.001,0) [0|5] "V" VCU
 SG_ P9_CellVoltage159 : 29|13@0+ (0.001,0) [0|5] "V" VCU
 SG_ P9_CellVoltage160 : 32|13@0+ (0.001,0) [0|5] "V" VCU
 SG_ P9_BalSwCell157 : 51|1@0+ (1,0) [0|1] "" VCU
 SG_ P9_BalSwCell158 : 50|1@0+ (1,0) [0|1] "" VCU
 SG_ P9_BalSwCell159 : 49|1@0+ (1,0) [0|1] "" VCU
 SG_ P9_BalSwCell160 : 48|1@0+ (1,0) [0|1] "" VCU

BO_ 2557018265 BatP9_BMS_CellVoltageM40: 8 BMS
 SG_ P9_CellVoltage161 : 7|13@0+ (0.001,0) [0|5] "V" VCU
 SG_ P9_CellVoltage162 : 10|13@0+ (0.001,0) [0|5] "V" VCU
 SG_ P9_CellVoltage163 : 29|13@0+ (0.001,0) [0|5] "V" VCU
 SG_ P9_CellVoltage164 : 32|13@0+ (0.001,0) [0|5] "V" VCU
 SG_ P9_BalSwCell161 : 51|1@0+ (1,0) [0|1] "" VCU
 SG_ P9_BalSwCell162 : 50|1@0+ (1,0) [0|1] "" VCU
 SG_ P9_BalSwCell163 : 49|1@0+ (1,0) [0|1] "" VCU
 SG_ P9_BalSwCell164 : 48|1@0+ (1,0) [0|1] "" VCU

BO_ 2557083801 BatP9_BMS_CellVoltageM41: 8 BMS
 SG_ P9_CellVoltage165 : 7|13@0+ (0.001,0) [0|5] "V" VCU
 SG_ P9_CellVoltage166 : 10|13@0+ (0.001,0) [0|5] "V" VCU
 SG_ P9_CellVoltage167 : 29|13@0+ (0.001,0) [0|5] "V" VCU
 SG_ P9_CellVoltage168 : 32|13@0+ (0.001,0) [0|5] "V" VCU
 SG_ P9_BalSwCell165 : 51|1@0+ (1,0) [0|1] "" VCU
 SG_ P9_BalSwCell166 : 50|1@0+ (1,0) [0|1] "" VCU
 SG_ P9_BalSwCell167 : 49|1@0+ (1,0) [0|1] "" VCU
 SG_ P9_BalSwCell168 : 48|1@0+ (1,0) [0|1] "" VCU

BO_ 2557149337 BatP9_BMS_CellVoltageM42: 8 BMS
 SG_ P9_CellVoltage169 : 7|13@0+ (0.001,0) [0|5] "V" VCU
 SG_ P9_CellVoltage170 : 10|13@0+ (0.001,0) [0|5] "V" VCU
 SG_ P9_CellVoltage171 : 29|13@0+ (0.001,0) [0|5] "V" VCU
 SG_ P9_CellVoltage172 : 32|13@0+ (0.001,0) [0|5] "V" VCU
 SG_ P9_BalSwCell169 : 51|1@0+ (1,0) [0|1] "" VCU
 SG_ P9_BalSwCell170 : 50|1@0+ (1,0) [0|1] "" VCU
 SG_ P9_BalSwCell171 : 49|1@0+ (1,0) [0|1] "" VCU
 SG_ P9_BalSwCell172 : 48|1@0+ (1,0) [0|1] "" VCU

BO_ 2557214873 BatP9_BMS_CellVoltageM43: 8 BMS
 SG_ P9_CellVoltage173 : 7|13@0+ (0.001,0) [0|5] "V" VCU
 SG_ P9_CellVoltage174 : 10|13@0+ (0.001,0) [0|5] "V" VCU
 SG_ P9_CellVoltage175 : 29|13@0+ (0.001,0) [0|5] "V" VCU
 SG_ P9_CellVoltage176 : 32|13@0+ (0.001,0) [0|5] "V" VCU
 SG_ P9_BalSwCell173 : 51|1@0+ (1,0) [0|1] "" VCU
 SG_ P9_BalSwCell174 : 50|1@0+ (1,0) [0|1] "" VCU
 SG_ P9_BalSwCell175 : 49|1@0+ (1,0) [0|1] "" VCU
 SG_ P9_BalSwCell176 : 48|1@0+ (1,0) [0|1] "" VCU

BO_ 2557280409 BatP9_BMS_CellVoltageM44: 8 BMS
 SG_ P9_CellVoltage177 : 7|13@0+ (0.001,0) [0|5] "V" VCU
 SG_ P9_CellVoltage178 : 10|13@0+ (0.001,0) [0|5] "V" VCU
 SG_ P9_CellVoltage179 : 29|13@0+ (0.001,0) [0|5] "V" VCU
 SG_ P9_CellVoltage180 : 32|13@0+ (0.001,0) [0|5] "V" VCU
 SG_ P9_BalSwCell177 : 51|1@0+ (1,0) [0|1] "" VCU
 SG_ P9_BalSwCell178 : 50|1@0+ (1,0) [0|1] "" VCU
 SG_ P9_BalSwCell179 : 49|1@0+ (1,0) [0|1] "" VCU
 SG_ P9_BalSwCell180 : 48|1@0+ (1,0) [0|1] "" VCU

BO_ 2557345945 BatP9_BMS_CellVoltageM45: 8 BMS
 SG_ P9_CellVoltage181 : 7|13@0+ (0.001,0) [0|5] "V" VCU
 SG_ P9_CellVoltage182 : 10|13@0+ (0.001,0) [0|5] "V" VCU
 SG_ P9_CellVoltage183 : 29|13@0+ (0.001,0) [0|5] "V" VCU
 SG_ P9_CellVoltage184 : 32|13@0+ (0.001,0) [0|5] "V" VCU
 SG_ P9_BalSwCell181 : 51|1@0+ (1,0) [0|1] "" VCU
 SG_ P9_BalSwCell182 : 50|1@0+ (1,0) [0|1] "" VCU
 SG_ P9_BalSwCell183 : 49|1@0+ (1,0) [0|1] "" VCU
 SG_ P9_BalSwCell184 : 48|1@0+ (1,0) [0|1] "" VCU

BO_ 2557411481 BatP9_BMS_CellVoltageM46: 8 BMS
 SG_ P9_CellVoltage185 : 7|13@0+ (0.001,0) [0|5] "V" VCU
 SG_ P9_CellVoltage186 : 10|13@0+ (0.001,0) [0|5] "V" VCU
 SG_ P9_CellVoltage187 : 29|13@0+ (0.001,0) [0|5] "V" VCU
 SG_ P9_CellVoltage188 : 32|13@0+ (0.001,0) [0|5] "V" VCU
 SG_ P9_BalSwCell185 : 51|1@0+ (1,0) [0|1] "" VCU
 SG_ P9_BalSwCell186 : 50|1@0+ (1,0) [0|1] "" VCU
 SG_ P9_BalSwCell187 : 49|1@0+ (1,0) [0|1] "" VCU
 SG_ P9_BalSwCell188 : 48|1@0+ (1,0) [0|1] "" VCU

BO_ 2557477017 BatP9_BMS_CellVoltageM47: 8 BMS
 SG_ P9_CellVoltage189 : 7|13@0+ (0.001,0) [0|5] "V" VCU
 SG_ P9_CellVoltage190 : 10|13@0+ (0.001,0) [0|5] "V" VCU
 SG_ P9_CellVoltage191 : 29|13@0+ (0.001,0) [0|5] "V" VCU
 SG_ P9_CellVoltage192 : 32|13@0+ (0.001,0) [0|5] "V" VCU
 SG_ P9_BalSwCell189 : 51|1@0+ (1,0) [0|1] "" VCU
 SG_ P9_BalSwCell190 : 50|1@0+ (1,0) [0|1] "" VCU
 SG_ P9_BalSwCell191 : 49|1@0+ (1,0) [0|1] "" VCU
 SG_ P9_BalSwCell192 : 48|1@0+ (1,0) [0|1] "" VCU

BO_ 2558525593 BatP9_BMS_CellTempM0: 8 BMS
 SG_ P9_CellTemp1 : 7|11@0+ (0.1,-40) [-40|150] "C" VCU
 SG_ P9_CellTemp2 : 12|11@0+ (0.1,-40) [-40|150] "C" VCU
 SG_ P9_CellTemp3 : 17|11@0+ (0.1,-40) [-40|150] "C" VCU
 SG_ P9_CellTemp4 : 38|11@0+ (0.1,-40) [-40|150] "C" VCU
 SG_ P9_CellTemp5 : 43|11@0+ (0.1,-40) [-40|150] "C" VCU

BO_ 2558591129 BatP9_BMS_CellTempM1: 8 BMS
 SG_ P9_CellTemp6 : 7|11@0+ (0.1,-40) [-40|150] "C" VCU
 SG_ P9_CellTemp7 : 12|11@0+ (0.1,-40) [-40|150] "C" VCU
 SG_ P9_CellTemp8 : 17|11@0+ (0.1,-40) [-40|150] "C" VCU
 SG_ P9_CellTemp9 : 38|11@0+ (0.1,-40) [-40|150] "C" VCU
 SG_ P9_CellTemp10 : 43|11@0+ (0.1,-40) [-40|150] "C" VCU

BO_ 2558656665 BatP9_BMS_CellTempM2: 8 BMS
 SG_ P9_CellTemp11 : 7|11@0+ (0.1,-40) [-40|150] "C" VCU
 SG_ P9_CellTemp12 : 12|11@0+ (0.1,-40) [-40|150] "C" VCU
 SG_ P9_CellTemp13 : 17|11@0+ (0.1,-40) [-40|150] "C" VCU
 SG_ P9_CellTemp14 : 38|11@0+ (0.1,-40) [-40|150] "C" VCU
 SG_ P9_CellTemp15 : 43|11@0+ (0.1,-40) [-40|150] "C" VCU

BO_ 2558722201 BatP9_BMS_CellTempM3: 8 BMS
 SG_ P9_CellTemp16 : 7|11@0+ (0.1,-40) [-40|150] "C" VCU
 SG_ P9_CellTemp17 : 12|11@0+ (0.1,-40) [-40|150] "C" VCU
 SG_ P9_CellTemp18 : 17|11@0+ (0.1,-40) [-40|150] "C" VCU
 SG_ P9_CellTemp19 : 38|11@0+ (0.1,-40) [-40|150] "C" VCU
 SG_ P9_CellTemp20 : 43|11@0+ (0.1,-40) [-40|150] "C" VCU

BO_ 2558787737 BatP9_BMS_CellTempM4: 8 BMS
 SG_ P9_CellTemp21 : 7|11@0+ (0.1,-40) [-40|150] "C" VCU
 SG_ P9_CellTemp22 : 12|11@0+ (0.1,-40) [-40|150] "C" VCU
 SG_ P9_CellTemp23 : 17|11@0+ (0.1,-40) [-40|150] "C" VCU
 SG_ P9_CellTemp24 : 38|11@0+ (0.1,-40) [-40|150] "C" VCU
 SG_ P9_CellTemp25 : 43|11@0+ (0.1,-40) [-40|150] "C" VCU

BO_ 2558853273 BatP9_BMS_CellTempM5: 8 BMS
 SG_ P9_CellTemp26 : 7|11@0+ (0.1,-40) [-40|150] "C" VCU
 SG_ P9_CellTemp27 : 12|11@0+ (0.1,-40) [-40|150] "C" VCU
 SG_ P9_CellTemp28 : 17|11@0+ (0.1,-40) [-40|150] "C" VCU
 SG_ P9_CellTemp29 : 38|11@0+ (0.1,-40) [-40|150] "C" VCU
 SG_ P9_CellTemp30 : 43|11@0+ (0.1,-40) [-40|150] "C" VCU

BO_ 2558918809 BatP9_BMS_CellTempM6: 8 BMS
 SG_ P9_CellTemp31 : 7|11@0+ (0.1,-40) [-40|150] "C" VCU
 SG_ P9_CellTemp32 : 12|11@0+ (0.1,-40) [-40|150] "C" VCU
 SG_ P9_CellTemp33 : 17|11@0+ (0.1,-40) [-40|150] "C" VCU
 SG_ P9_CellTemp34 : 38|11@0+ (0.1,-40) [-40|150] "C" VCU
 SG_ P9_CellTemp35 : 43|11@0+ (0.1,-40) [-40|150] "C" VCU

BO_ 2558984345 BatP9_BMS_CellTempM7: 8 BMS
 SG_ P9_CellTemp36 : 7|11@0+ (0.1,-40) [-40|150] "C" VCU
 SG_ P9_CellTemp37 : 12|11@0+ (0.1,-40) [-40|150] "C" VCU
 SG_ P9_CellTemp38 : 17|11@0+ (0.1,-40) [-40|150] "C" VCU
 SG_ P9_CellTemp39 : 38|11@0+ (0.1,-40) [-40|150] "C" VCU
 SG_ P9_CellTemp40 : 43|11@0+ (0.1,-40) [-40|150] "C" VCU

BO_ 2559049881 BatP9_BMS_CellTempM8: 8 BMS
 SG_ P9_CellTemp41 : 7|11@0+ (0.1,-40) [-40|150] "C" VCU
 SG_ P9_CellTemp42 : 12|11@0+ (0.1,-40) [-40|150] "C" VCU
 SG_ P9_CellTemp43 : 17|11@0+ (0.1,-40) [-40|150] "C" VCU
 SG_ P9_CellTemp44 : 38|11@0+ (0.1,-40) [-40|150] "C" VCU
 SG_ P9_CellTemp45 : 43|11@0+ (0.1,-40) [-40|150] "C" VCU

BO_ 2559115417 BatP9_BMS_CellTempM9: 8 BMS
 SG_ P9_CellTemp46 : 7|11@0+ (0.1,-40) [-40|150] "C" VCU
 SG_ P9_CellTemp47 : 12|11@0+ (0.1,-40) [-40|150] "C" VCU
 SG_ P9_CellTemp48 : 17|11@0+ (0.1,-40) [-40|150] "C" VCU
 SG_ P9_CellTemp49 : 38|11@0+ (0.1,-40) [-40|150] "C" VCU
 SG_ P9_CellTemp50 : 43|11@0+ (0.1,-40) [-40|150] "C" VCU

BO_ 2559180953 BatP9_BMS_CellTempM10: 8 BMS
 SG_ P9_CellTemp51 : 7|11@0+ (0.1,-40) [-40|150] "C" VCU
 SG_ P9_CellTemp52 : 12|11@0+ (0.1,-40) [-40|150] "C" VCU
 SG_ P9_CellTemp53 : 17|11@0+ (0.1,-40) [-40|150] "C" VCU
 SG_ P9_CellTemp54 : 38|11@0+ (0.1,-40) [-40|150] "C" VCU
 SG_ P9_CellTemp55 : 43|11@0+ (0.1,-40) [-40|150] "C" VCU

BO_ 2559246489 BatP9_BMS_CellTempM11: 8 BMS
 SG_ P9_CellTemp56 : 7|11@0+ (0.1,-40) [-40|150] "C" VCU
 SG_ P9_CellTemp57 : 12|11@0+ (0.1,-40) [-40|150] "C" VCU
 SG_ P9_CellTemp58 : 17|11@0+ (0.1,-40) [-40|150] "C" VCU
 SG_ P9_CellTemp59 : 38|11@0+ (0.1,-40) [-40|150] "C" VCU
 SG_ P9_CellTemp60 : 43|11@0+ (0.1,-40) [-40|150] "C" VCU

BO_ 2559312025 BatP9_BMS_CellTempM12: 8 BMS
 SG_ P9_CellTemp61 : 7|11@0+ (0.1,-40) [-40|150] "C" VCU
 SG_ P9_CellTemp62 : 12|11@0+ (0.1,-40) [-40|150] "C" VCU
 SG_ P9_CellTemp63 : 17|11@0+ (0.1,-40) [-40|150] "C" VCU
 SG_ P9_CellTemp64 : 38|11@0+ (0.1,-40) [-40|150] "C" VCU
 SG_ P9_CellTemp65 : 43|11@0+ (0.1,-40) [-40|150] "C" VCU

BO_ 2559377561 BatP9_BMS_CellTempM13: 8 BMS
 SG_ P9_CellTemp66 : 7|11@0+ (0.1,-40) [-40|150] "C" VCU
 SG_ P9_CellTemp67 : 12|11@0+ (0.1,-40) [-40|150] "C" VCU
 SG_ P9_CellTemp68 : 17|11@0+ (0.1,-40) [-40|150] "C" VCU
 SG_ P9_CellTemp69 : 38|11@0+ (0.1,-40) [-40|150] "C" VCU
 SG_ P9_CellTemp70 : 43|11@0+ (0.1,-40) [-40|150] "C" VCU

BO_ 2559443097 BatP9_BMS_CellTempM14: 8 BMS
 SG_ P9_CellTemp71 : 7|11@0+ (0.1,-40) [-40|150] "C" VCU
 SG_ P9_CellTemp72 : 12|11@0+ (0.1,-40) [-40|150] "C" VCU
 SG_ P9_CellTemp73 : 17|11@0+ (0.1,-40) [-40|150] "C" VCU
 SG_ P9_CellTemp74 : 38|11@0+ (0.1,-40) [-40|150] "C" VCU
 SG_ P9_CellTemp75 : 43|11@0+ (0.1,-40) [-40|150] "C" VCU

BO_ 2559508633 BatP9_BMS_CellTempM15: 8 BMS
 SG_ P9_CellTemp76 : 7|11@0+ (0.1,-40) [-40|150] "C" VCU
 SG_ P9_CellTemp77 : 12|11@0+ (0.1,-40) [-40|150] "C" VCU
 SG_ P9_CellTemp78 : 17|11@0+ (0.1,-40) [-40|150] "C" VCU
 SG_ P9_CellTemp79 : 38|11@0+ (0.1,-40) [-40|150] "C" VCU
 SG_ P9_CellTemp80 : 43|11@0+ (0.1,-40) [-40|150] "C" VCU

BO_ 2559574169 BatP9_BMS_CellTempM16: 8 BMS
 SG_ P9_CellTemp81 : 7|11@0+ (0.1,-40) [-40|150] "C" VCU
 SG_ P9_CellTemp82 : 12|11@0+ (0.1,-40) [-40|150] "C" VCU
 SG_ P9_CellTemp83 : 17|11@0+ (0.1,-40) [-40|150] "C" VCU
 SG_ P9_CellTemp84 : 38|11@0+ (0.1,-40) [-40|150] "C" VCU
 SG_ P9_CellTemp85 : 43|11@0+ (0.1,-40) [-40|150] "C" VCU

BO_ 2559639705 BatP9_BMS_CellTempM17: 8 BMS
 SG_ P9_CellTemp86 : 7|11@0+ (0.1,-40) [-40|150] "C" VCU
 SG_ P9_CellTemp87 : 12|11@0+ (0.1,-40) [-40|150] "C" VCU
 SG_ P9_CellTemp88 : 17|11@0+ (0.1,-40) [-40|150] "C" VCU
 SG_ P9_CellTemp89 : 38|11@0+ (0.1,-40) [-40|150] "C" VCU
 SG_ P9_CellTemp90 : 43|11@0+ (0.1,-40) [-40|150] "C" VCU

BO_ 2559705241 BatP9_BMS_CellTempM18: 8 BMS
 SG_ P9_CellTemp91 : 7|11@0+ (0.1,-40) [-40|150] "C" VCU
 SG_ P9_CellTemp92 : 12|11@0+ (0.1,-40) [-40|150] "C" VCU
 SG_ P9_CellTemp93 : 17|11@0+ (0.1,-40) [-40|150] "C" VCU
 SG_ P9_CellTemp94 : 38|11@0+ (0.1,-40) [-40|150] "C" VCU
 SG_ P9_CellTemp95 : 43|11@0+ (0.1,-40) [-40|150] "C" VCU

BO_ 2559770777 BatP9_BMS_CellTempM19: 8 BMS
 SG_ P9_CellTemp96 : 7|11@0+ (0.1,-40) [-40|150] "C" VCU
 SG_ P9_CellTemp97 : 12|11@0+ (0.1,-40) [-40|150] "C" VCU
 SG_ P9_CellTemp98 : 17|11@0+ (0.1,-40) [-40|150] "C" VCU
 SG_ P9_CellTemp99 : 38|11@0+ (0.1,-40) [-40|150] "C" VCU
 SG_ P9_CellTemp100 : 43|11@0+ (0.1,-40) [-40|150] "C" VCU

BO_ 2559836313 BatP9_BMS_CellTempM20: 8 BMS
 SG_ P9_CellTemp101 : 7|11@0+ (0.1,-40) [-40|150] "C" VCU
 SG_ P9_CellTemp102 : 12|11@0+ (0.1,-40) [-40|150] "C" VCU
 SG_ P9_CellTemp103 : 17|11@0+ (0.1,-40) [-40|150] "C" VCU
 SG_ P9_CellTemp104 : 38|11@0+ (0.1,-40) [-40|150] "C" VCU
 SG_ P9_CellTemp105 : 43|11@0+ (0.1,-40) [-40|150] "C" VCU

BO_ 2559901849 BatP9_BMS_CellTempM21: 8 BMS
 SG_ P9_CellTemp106 : 7|11@0+ (0.1,-40) [-40|150] "C" VCU
 SG_ P9_CellTemp107 : 12|11@0+ (0.1,-40) [-40|150] "C" VCU
 SG_ P9_CellTemp108 : 17|11@0+ (0.1,-40) [-40|150] "C" VCU
 SG_ P9_CellTemp109 : 38|11@0+ (0.1,-40) [-40|150] "C" VCU
 SG_ P9_CellTemp110 : 43|11@0+ (0.1,-40) [-40|150] "C" VCU

BO_ 2559967385 BatP9_BMS_CellTempM22: 8 BMS
 SG_ P9_CellTemp111 : 7|11@0+ (0.1,-40) [-40|150] "C" VCU
 SG_ P9_CellTemp112 : 12|11@0+ (0.1,-40) [-40|150] "C" VCU
 SG_ P9_CellTemp113 : 17|11@0+ (0.1,-40) [-40|150] "C" VCU
 SG_ P9_CellTemp114 : 38|11@0+ (0.1,-40) [-40|150] "C" VCU
 SG_ P9_CellTemp115 : 43|11@0+ (0.1,-40) [-40|150] "C" VCU

BO_ 2560032921 BatP9_BMS_CellTempM23: 8 BMS
 SG_ P9_CellTemp116 : 7|11@0+ (0.1,-40) [-40|150] "C" VCU
 SG_ P9_CellTemp117 : 12|11@0+ (0.1,-40) [-40|150] "C" VCU
 SG_ P9_CellTemp118 : 17|11@0+ (0.1,-40) [-40|150] "C" VCU
 SG_ P9_CellTemp119 : 38|11@0+ (0.1,-40) [-40|150] "C" VCU
 SG_ P9_CellTemp120 : 43|11@0+ (0.1,-40) [-40|150] "C" VCU

BO_ 2560098457 BatP9_BMS_CellTempM24: 8 BMS
 SG_ P9_CellTemp121 : 7|11@0+ (0.1,-40) [-40|150] "C" VCU
 SG_ P9_CellTemp122 : 12|11@0+ (0.1,-40) [-40|150] "C" VCU
 SG_ P9_CellTemp123 : 17|11@0+ (0.1,-40) [-40|150] "C" VCU
 SG_ P9_CellTemp124 : 38|11@0+ (0.1,-40) [-40|150] "C" VCU
 SG_ P9_CellTemp125 : 43|11@0+ (0.1,-40) [-40|150] "C" VCU

BO_ 2560163993 BatP9_BMS_CellTempM25: 8 BMS
 SG_ P9_CellTemp126 : 7|11@0+ (0.1,-40) [-40|150] "C" VCU
 SG_ P9_CellTemp127 : 12|11@0+ (0.1,-40) [-40|150] "C" VCU
 SG_ P9_CellTemp128 : 17|11@0+ (0.1,-40) [-40|150] "C" VCU
 SG_ P9_CellTemp129 : 38|11@0+ (0.1,-40) [-40|150] "C" VCU
 SG_ P9_CellTemp130 : 43|11@0+ (0.1,-40) [-40|150] "C" VCU

BO_ 2560229529 BatP9_BMS_CellTempM26: 8 BMS
 SG_ P9_CellTemp131 : 7|11@0+ (0.1,-40) [-40|150] "C" VCU
 SG_ P9_CellTemp132 : 12|11@0+ (0.1,-40) [-40|150] "C" VCU
 SG_ P9_CellTemp133 : 17|11@0+ (0.1,-40) [-40|150] "C" VCU
 SG_ P9_CellTemp134 : 38|11@0+ (0.1,-40) [-40|150] "C" VCU
 SG_ P9_CellTemp135 : 43|11@0+ (0.1,-40) [-40|150] "C" VCU

BO_ 2560295065 BatP9_BMS_CellTempM27: 8 BMS
 SG_ P9_CellTemp136 : 7|11@0+ (0.1,-40) [-40|150] "C" VCU
 SG_ P9_CellTemp137 : 12|11@0+ (0.1,-40) [-40|150] "C" VCU
 SG_ P9_CellTemp138 : 17|11@0+ (0.1,-40) [-40|150] "C" VCU
 SG_ P9_CellTemp139 : 38|11@0+ (0.1,-40) [-40|150] "C" VCU
 SG_ P9_CellTemp140 : 43|11@0+ (0.1,-40) [-40|150] "C" VCU

BO_ 2560360601 BatP9_BMS_CellTempM28: 8 BMS
 SG_ P9_CellTemp141 : 7|11@0+ (0.1,-40) [-40|150] "C" VCU
 SG_ P9_CellTemp142 : 12|11@0+ (0.1,-40) [-40|150] "C" VCU
 SG_ P9_CellTemp143 : 17|11@0+ (0.1,-40) [-40|150] "C" VCU
 SG_ P9_CellTemp144 : 38|11@0+ (0.1,-40) [-40|150] "C" VCU
 SG_ P9_CellTemp145 : 43|11@0+ (0.1,-40) [-40|150] "C" VCU

BO_ 2560426137 BatP9_BMS_CellTempM29: 8 BMS
 SG_ P9_CellTemp146 : 7|11@0+ (0.1,-40) [-40|150] "C" VCU
 SG_ P9_CellTemp147 : 12|11@0+ (0.1,-40) [-40|150] "C" VCU
 SG_ P9_CellTemp148 : 17|11@0+ (0.1,-40) [-40|150] "C" VCU
 SG_ P9_CellTemp149 : 38|11@0+ (0.1,-40) [-40|150] "C" VCU
 SG_ P9_CellTemp150 : 43|11@0+ (0.1,-40) [-40|150] "C" VCU

BO_ 2560491673 BatP9_BMS_CellTempM30: 8 BMS
 SG_ P9_CellTemp151 : 7|11@0+ (0.1,-40) [-40|150] "C" VCU
 SG_ P9_CellTemp152 : 12|11@0+ (0.1,-40) [-40|150] "C" VCU
 SG_ P9_CellTemp153 : 17|11@0+ (0.1,-40) [-40|150] "C" VCU
 SG_ P9_CellTemp154 : 38|11@0+ (0.1,-40) [-40|150] "C" VCU
 SG_ P9_CellTemp155 : 43|11@0+ (0.1,-40) [-40|150] "C" VCU

BO_ 2560557209 BatP9_BMS_CellTempM31: 8 BMS
 SG_ P9_CellTemp156 : 7|11@0+ (0.1,-40) [-40|150] "C" VCU
 SG_ P9_CellTemp157 : 12|11@0+ (0.1,-40) [-40|150] "C" VCU
 SG_ P9_CellTemp158 : 17|11@0+ (0.1,-40) [-40|150] "C" VCU
 SG_ P9_CellTemp159 : 38|11@0+ (0.1,-40) [-40|150] "C" VCU
 SG_ P9_CellTemp160 : 43|11@0+ (0.1,-40) [-40|150] "C" VCU

BO_ 2560622745 BatP9_BMS_CellTempM32: 8 BMS
 SG_ P9_CellTemp161 : 7|11@0+ (0.1,-40) [-40|150] "C" VCU
 SG_ P9_CellTemp162 : 12|11@0+ (0.1,-40) [-40|150] "C" VCU
 SG_ P9_CellTemp163 : 17|11@0+ (0.1,-40) [-40|150] "C" VCU
 SG_ P9_CellTemp164 : 38|11@0+ (0.1,-40) [-40|150] "C" VCU
 SG_ P9_CellTemp165 : 43|11@0+ (0.1,-40) [-40|150] "C" VCU

BO_ 2560688281 BatP9_BMS_CellTempM33: 8 BMS
 SG_ P9_CellTemp166 : 7|11@0+ (0.1,-40) [-40|150] "C" VCU
 SG_ P9_CellTemp167 : 12|11@0+ (0.1,-40) [-40|150] "C" VCU
 SG_ P9_CellTemp168 : 17|11@0+ (0.1,-40) [-40|150] "C" VCU
 SG_ P9_CellTemp169 : 38|11@0+ (0.1,-40) [-40|150] "C" VCU
 SG_ P9_CellTemp170 : 43|11@0+ (0.1,-40) [-40|150] "C" VCU

BO_ 2560753817 BatP9_BMS_CellTempM34: 8 BMS
 SG_ P9_CellTemp171 : 7|11@0+ (0.1,-40) [-40|150] "C" VCU
 SG_ P9_CellTemp172 : 12|11@0+ (0.1,-40) [-40|150] "C" VCU
 SG_ P9_CellTemp173 : 17|11@0+ (0.1,-40) [-40|150] "C" VCU
 SG_ P9_CellTemp174 : 38|11@0+ (0.1,-40) [-40|150] "C" VCU
 SG_ P9_CellTemp175 : 43|11@0+ (0.1,-40) [-40|150] "C" VCU

BO_ 2560819353 BatP9_BMS_CellTempM35: 8 BMS
 SG_ P9_CellTemp176 : 7|11@0+ (0.1,-40) [-40|150] "C" VCU
 SG_ P9_CellTemp177 : 12|11@0+ (0.1,-40) [-40|150] "C" VCU
 SG_ P9_CellTemp178 : 17|11@0+ (0.1,-40) [-40|150] "C" VCU
 SG_ P9_CellTemp179 : 38|11@0+ (0.1,-40) [-40|150] "C" VCU
 SG_ P9_CellTemp180 : 43|11@0+ (0.1,-40) [-40|150] "C" VCU

BO_ 2560884889 BatP9_BMS_CellTempM36: 8 BMS
 SG_ P9_CellTemp181 : 7|11@0+ (0.1,-40) [-40|150] "C" VCU
 SG_ P9_CellTemp182 : 12|11@0+ (0.1,-40) [-40|150] "C" VCU
 SG_ P9_CellTemp183 : 17|11@0+ (0.1,-40) [-40|150] "C" VCU
 SG_ P9_CellTemp184 : 38|11@0+ (0.1,-40) [-40|150] "C" VCU
 SG_ P9_CellTemp185 : 43|11@0+ (0.1,-40) [-40|150] "C" VCU

BO_ 2560950425 BatP9_BMS_CellTempM37: 8 BMS
 SG_ P9_CellTemp186 : 7|11@0+ (0.1,-40) [-40|150] "C" VCU
 SG_ P9_CellTemp187 : 12|11@0+ (0.1,-40) [-40|150] "C" VCU
 SG_ P9_CellTemp188 : 17|11@0+ (0.1,-40) [-40|150] "C" VCU
 SG_ P9_CellTemp189 : 38|11@0+ (0.1,-40) [-40|150] "C" VCU
 SG_ P9_CellTemp190 : 43|11@0+ (0.1,-40) [-40|150] "C" VCU

BO_ 2561015961 BatP9_BMS_CellTempM38: 8 BMS
 SG_ P9_CellTemp191 : 7|11@0+ (0.1,-40) [-40|150] "C" VCU
 SG_ P9_CellTemp192 : 12|11@0+ (0.1,-40) [-40|150] "C" VCU
 SG_ P9_DatLen16DbgInfo1 : 7|16@0+ (1,0) [0|65535] "" VCU
 SG_ P9_DatLen16DbgInfo2 : 23|16@0+ (1,0) [0|65535] "" VCU
 SG_ P9_DatLen16DbgInfo3 : 39|16@0+ (1,0) [0|65535] "" VCU
 SG_ P9_DatLen16DbgInfo4 : 55|16@0+ (1,0) [0|65535] "" VCU

BO_ 2550399146 BatP10_BMS_PowerSupplyInfo: 8 BMS
 SG_ P10_BMSPwrSuplVlt1 : 7|9@0+ (0.1,0) [0|50] "V" VCU
 SG_ P10_BMSPwrSuplVlt2 : 14|9@0+ (0.1,0) [0|50] "V" VCU
 SG_ P10_ChrgStationAuxPwrSuplVlt : 21|9@0+ (0.1,0) [0|50] "V" VCU
 SG_ P10_BMSKL15ON : 28|1@0+ (1,0) [0|1] "" VCU
 SG_ P10_DCStepState : 27|8@0+ (1,0) [0|255] "" VCU
 SG_ P10_ExtLvWakeup_28VOnly : 35|9@0+ (0.1,0) [0|50] "V" VCU

BO_ 2550464682 BatP10_BMS_PackUsageLimit: 8 BMS
 SG_ P10_PackVltUprLmt : 7|14@0+ (0.1,0) [0|1200] "V" VCU
 SG_ P10_PackVltLoLmt : 9|14@0+ (0.1,0) [0|1200] "V" VCU
 SG_ P10_PackMaxDschrgCrnt : 27|14@0+ (0.1,0) [0|1600] "A" VCU
 SG_ P10_PackMaxChrgCrnt : 45|14@0+ (0.1,0) [0|1600] "A" VCU

BO_ 2550530218 BatP10_BMS_PackPowerCapability: 8 BMS
 SG_ P10_PackDschrgPwrLmt : 7|10@0+ (1,0) [0|1000] "kW" VCU
 SG_ P10_PackDschrgPwrStat : 13|2@0+ (1,0) [0|3] "" VCU
 SG_ P10_PackChrgPwrLmt : 11|10@0+ (1,0) [0|1000] "kW" VCU
 SG_ P10_PackChrgPwrStat : 17|2@0+ (1,0) [0|3] "" VCU

BO_ 2550595754 BatP10_BMS_ChargingInfo: 8 BMS
 SG_ P10_ChrgrCplrStat : 7|1@0+ (1,0) [0|1] "" VCU
 SG_ P10_HVBattChrgSysStatus : 6|4@0+ (1,0) [0|15] "" VCU
 SG_ P10_DCChrgCrntCmd : 2|9@0+ (1,0) [0|500] "A" VCU
 SG_ P10_CC2Vlt : 9|8@0+ (0.1,0) [0|25] "V" VCU
 SG_ P10_DCRcptPosTemp : 17|9@0+ (0.5,-40) [-40|150] "C" VCU
 SG_ P10_DCRcptNegTemp : 24|9@0+ (0.5,-40) [-40|150] "C" VCU
 SG_ P10_Tm2FullChrg : 47|14@0+ (1,0) [0|65535] "min" VCU

BO_ 2550661290 BatP10_BMS_ThermalManagement: 8 BMS
 SG_ P10_Inlet1ClntTemp : 7|11@0+ (0.1,-40) [-40|150] "C" VCU
 SG_ P10_Inlet2ClntTemp : 12|11@0+ (0.1,-40) [-40|150] "C" VCU
 SG_ P10_Outlet1ClntTemp : 17|11@0+ (0.1,-40) [-40|150] "C" VCU
 SG_ P10_Outlet2ClntTemp : 38|11@0+ (0.1,-40) [-40|150] "C" VCU
 SG_ P10_TrgtClntTemp : 43|11@0+ (0.1,-40) [-40|150] "C" VCU
 SG_ P10_TrgtClntFlowRate : 48|9@0+ (0.2,0) [0|100] "C" VCU

BO_ 2550726826 BatP10_BMS_CellVoltMaxMin: 8 BMS
 SG_ P10_MaxCellVlt : 7|13@0+ (0.001,0) [0|5] "V" VCU
 SG_ P10_MaxCellVltNum : 10|9@0+ (1,0) [0|500] "" VCU
 SG_ P10_MinCellVlt : 17|13@0+ (0.001,0) [0|5] "V" VCU
 SG_ P10_MinCellVltNum : 36|9@0+ (1,0) [0|500] "" VCU
 SG_ P10_AvgCellVlt : 43|13@0+ (0.001,0) [0|5] "V" VCU

BO_ 2550792362 BatP10_BMS_CellTempMaxMin: 8 BMS
 SG_ P10_MaxCellTemp : 7|11@0+ (0.1,-40) [-40|150] "C" VCU
 SG_ P10_MaxCellTempNum : 12|9@0+ (1,0) [0|500] "" VCU
 SG_ P10_MinCellTemp : 19|11@0+ (0.1,-40) [-40|150] "C" VCU
 SG_ P10_MinCellTempNum : 24|9@0+ (1,0) [0|500] "" VCU
 SG_ P10_AvgCellTemp : 47|11@0+ (0.1,-40) [-40|150] "C" VCU

BO_ 2550857898 BatP10_BMS_PackFaultInfo1: 8 BMS
 SG_ P10_PackTotFltNum : 7|8@0+ (1,0) [0|200] "" VCU
 SG_ P10_CellOverVoltage : 15|2@0+ (1,0) [0|3] "" VCU
 SG_ P10_CellUnderVoltage : 13|2@0+ (1,0) [0|3] "" VCU
 SG_ P10_CellVoltageDiffHi : 11|1@0+ (1,0) [0|1] "" VCU
 SG_ P10_PackOverVoltage : 10|2@0+ (1,0) [0|3] "" VCU
 SG_ P10_PackUnderVoltage : 8|2@0+ (1,0) [0|3] "" VCU
 SG_ P10_CellOverTemp : 22|2@0+ (1,0) [0|3] "" VCU
 SG_ P10_CellTempLow : 20|1@0+ (1,0) [0|1] "" VCU
 SG_ P10_CellTempDiffHi : 19|1@0+ (1,0) [0|1] "" VCU
 SG_ P10_PackDschrgCrntHi : 18|2@0+ (1,0) [0|3] "" VCU
 SG_ P10_PackChrgCrntHi : 16|2@0+ (1,0) [0|3] "" VCU
 SG_ P10_PackCrnSnsr1OffsetHi : 30|1@0+ (1,0) [0|1] "" VCU
 SG_ P10_HVIsolFlt : 29|2@0+ (1,0) [0|3] "" VCU
 SG_ P10_HVILFlt : 27|1@0+ (1,0) [0|1] "" VCU
 SG_ P10_ThrmlRunaway : 26|1@0+ (1,0) [0|1] "" VCU
 SG_ P10_CellVoltInvalid : 25|1@0+ (1,0) [0|1] "" VCU
 SG_ P10_CellTempInvalid : 24|1@0+ (1,0) [0|1] "" VCU
 SG_ P10_DaisyChainComFlt : 39|1@0+ (1,0) [0|1] "" VCU
 SG_ P10_PackVoltRatFlt : 38|1@0+ (1,0) [0|1] "" VCU
 SG_ P10_CrntSnsr1Invalid : 37|1@0+ (1,0) [0|1] "" VCU
 SG_ P10_CrntSnsr1OOR : 36|1@0+ (1,0) [0|1] "" VCU
 SG_ P10_CrntSnsr2Invalid : 35|1@0+ (1,0) [0|1] "" VCU
 SG_ P10_CrntSnsr2OOR : 34|1@0+ (1,0) [0|1] "" VCU
 SG_ P10_PackCrnSnsr2OffsetHi : 33|1@0+ (1,0) [0|1] "" VCU
 SG_ P10_OutofEnergy : 32|1@0+ (1,0) [0|1] "" VCU
 SG_ P10_IsolDetCircErr : 47|1@0+ (1,0) [0|1] "" VCU
 SG_ P10_HVILCircShortToGND : 46|1@0+ (1,0) [0|1] "" VCU
 SG_ P10_HVILCircShortToPwr : 45|1@0+ (1,0) [0|1] "" VCU

BO_ 2550923434 BatP10_BMS_PackFaultInfo2: 8 BMS
 SG_ P10_MainPosCntctrStkClsd : 7|1@0+ (1,0) [0|1] "" VCU
 SG_ P10_MainPosCntctrStkOpn : 6|1@0+ (1,0) [0|1] "" VCU
 SG_ P10_MainNegCntctr1StkClsd : 5|1@0+ (1,0) [0|1] "" VCU
 SG_ P10_MainNegCntctr1StkOpn : 4|1@0+ (1,0) [0|1] "" VCU
 SG_ P10_MainNegCntctr2StkClsd : 3|1@0+ (1,0) [0|1] "" VCU
 SG_ P10_MainNegCntctr2StkOpn : 2|1@0+ (1,0) [0|1] "" VCU
 SG_ P10_PrechargTmOut : 1|1@0+ (1,0) [0|1] "" VCU
 SG_ P10_PrechrgCrntHi : 0|1@0+ (1,0) [0|1] "" VCU
 SG_ P10_ChrgCplrPosTempHi : 15|1@0+ (1,0) [0|1] "" VCU
 SG_ P10_ChrgCplrNegTempHi : 14|1@0+ (1,0) [0|1] "" VCU
 SG_ P10_BMSPwrSuplVlt1Hi : 13|1@0+ (1,0) [0|1] "" VCU
 SG_ P10_BMSPwrSuplVlt1Lo : 12|1@0+ (1,0) [0|1] "" VCU
 SG_ P10_BMSPwrSuplVlt2Hi : 11|1@0+ (1,0) [0|1] "" VCU
 SG_ P10_BMSPwrSuplVlt2Lo : 10|1@0+ (1,0) [0|1] "" VCU
 SG_ P10_CntctrCirPwrSuplVltLo : 9|1@0+ (1,0) [0|1] "" VCU
 SG_ P10_CntctrCirPwrSuplVltHi : 8|1@0+ (1,0) [0|1] "" VCU
 SG_ P10_CAN1BusOff : 23|1@0+ (1,0) [0|1] "" VCU
 SG_ P10_CAN1BusTmOut : 22|1@0+ (1,0) [0|1] "" VCU
 SG_ P10_CAN2BusOff : 21|1@0+ (1,0) [0|1] "" VCU
 SG_ P10_CAN2BusTmOut : 20|1@0+ (1,0) [0|1] "" VCU
 SG_ P10_CellBalCircTempHi : 19|1@0+ (1,0) [0|1] "" VCU
 SG_ P10_ClntInTempHi : 18|1@0+ (1,0) [0|1] "" VCU
 SG_ P10_ClntOutTempHi : 17|1@0+ (1,0) [0|1] "" VCU
 SG_ P10_CellExtrmUdrVolt : 16|1@0+ (1,0) [0|1] "" VCU
 SG_ P10_CellExtrmOvrVolt : 31|1@0+ (1,0) [0|1] "" VCU
 SG_ P10_Branch1DischrgCrntHi  : 30|1@0+ (1,0) [0|1] "" VCU
 SG_ P10_Branch2DischrgCrntHi  : 29|1@0+ (1,0) [0|1] "" VCU
 SG_ P10_Branch1ChrgCrntHi  : 28|1@0+ (1,0) [0|1] "" VCU
 SG_ P10_Branch2ChrgCrntHi  : 27|1@0+ (1,0) [0|1] "" VCU
 SG_ P10_InitFailed : 26|1@0+ (1,0) [0|1] "" VCU
 SG_ P10_PackErrCode : 25|10@0+ (1,0) [0|1023] "" VCU

BO_ 2550988970 BatP10_BMS_PackConfigInfo: 8 BMS
 SG_ P10_PackTotCellNum : 7|9@0+ (1,0) [0|500] "" VCU
 SG_ P10_PackTotCellTempSnsrNum : 14|9@0+ (1,0) [0|500] "" VCU

BO_ 2552299690 BatP10_BMS_BMSVersion: 8 BMS
 SG_ P10_BMSASWMajVerNum : 7|8@0+ (1,0) [0|9] "" VCU
 SG_ P10_BMSASWMinVerNum : 15|8@0+ (1,0) [0|99] "" VCU
 SG_ P10_BMSASWPatchVerNum : 23|8@0+ (1,0) [0|255] "" VCU
 SG_ P10_BMSBSWMajVerNum : 31|8@0+ (1,0) [0|9] "" VCU
 SG_ P10_BMSBSWMinVerNum : 39|8@0+ (1,0) [0|99] "" VCU
 SG_ P10_BMSBSWPatchVerNum : 47|8@0+ (1,0) [0|255] "" VCU

BO_ 2554396842 BatP10_BMS_CellVoltageM0: 8 BMS
 SG_ P10_CellVoltage1 : 7|13@0+ (0.001,0) [0|5] "V" VCU
 SG_ P10_CellVoltage2 : 10|13@0+ (0.001,0) [0|5] "V" VCU
 SG_ P10_CellVoltage3 : 29|13@0+ (0.001,0) [0|5] "V" VCU
 SG_ P10_CellVoltage4 : 32|13@0+ (0.001,0) [0|5] "V" VCU
 SG_ P10_BalSwCell1 : 51|1@0+ (1,0) [0|1] "" VCU
 SG_ P10_BalSwCell2 : 50|1@0+ (1,0) [0|1] "" VCU
 SG_ P10_BalSwCell3 : 49|1@0+ (1,0) [0|1] "" VCU
 SG_ P10_BalSwCell4 : 48|1@0+ (1,0) [0|1] "" VCU

BO_ 2554462378 BatP10_BMS_CellVoltageM1: 8 BMS
 SG_ P10_CellVoltage5 : 7|13@0+ (0.001,0) [0|5] "V" VCU
 SG_ P10_CellVoltage6 : 10|13@0+ (0.001,0) [0|5] "V" VCU
 SG_ P10_CellVoltage7 : 29|13@0+ (0.001,0) [0|5] "V" VCU
 SG_ P10_CellVoltage8 : 32|13@0+ (0.001,0) [0|5] "V" VCU
 SG_ P10_BalSwCell5 : 51|1@0+ (1,0) [0|1] "" VCU
 SG_ P10_BalSwCell6 : 50|1@0+ (1,0) [0|1] "" VCU
 SG_ P10_BalSwCell7 : 49|1@0+ (1,0) [0|1] "" VCU
 SG_ P10_BalSwCell8 : 48|1@0+ (1,0) [0|1] "" VCU

BO_ 2554527914 BatP10_BMS_CellVoltageM2: 8 BMS
 SG_ P10_CellVoltage9 : 7|13@0+ (0.001,0) [0|5] "V" VCU
 SG_ P10_CellVoltage10 : 10|13@0+ (0.001,0) [0|5] "V" VCU
 SG_ P10_CellVoltage11 : 29|13@0+ (0.001,0) [0|5] "V" VCU
 SG_ P10_CellVoltage12 : 32|13@0+ (0.001,0) [0|5] "V" VCU
 SG_ P10_BalSwCell9 : 51|1@0+ (1,0) [0|1] "" VCU
 SG_ P10_BalSwCell10 : 50|1@0+ (1,0) [0|1] "" VCU
 SG_ P10_BalSwCell11 : 49|1@0+ (1,0) [0|1] "" VCU
 SG_ P10_BalSwCell12 : 48|1@0+ (1,0) [0|1] "" VCU

BO_ 2554593450 BatP10_BMS_CellVoltageM3: 8 BMS
 SG_ P10_CellVoltage13 : 7|13@0+ (0.001,0) [0|5] "V" VCU
 SG_ P10_CellVoltage14 : 10|13@0+ (0.001,0) [0|5] "V" VCU
 SG_ P10_CellVoltage15 : 29|13@0+ (0.001,0) [0|5] "V" VCU
 SG_ P10_CellVoltage16 : 32|13@0+ (0.001,0) [0|5] "V" VCU
 SG_ P10_BalSwCell13 : 51|1@0+ (1,0) [0|1] "" VCU
 SG_ P10_BalSwCell14 : 50|1@0+ (1,0) [0|1] "" VCU
 SG_ P10_BalSwCell15 : 49|1@0+ (1,0) [0|1] "" VCU
 SG_ P10_BalSwCell16 : 48|1@0+ (1,0) [0|1] "" VCU

BO_ 2554658986 BatP10_BMS_CellVoltageM4: 8 BMS
 SG_ P10_CellVoltage17 : 7|13@0+ (0.001,0) [0|5] "V" VCU
 SG_ P10_CellVoltage18 : 10|13@0+ (0.001,0) [0|5] "V" VCU
 SG_ P10_CellVoltage19 : 29|13@0+ (0.001,0) [0|5] "V" VCU
 SG_ P10_CellVoltage20 : 32|13@0+ (0.001,0) [0|5] "V" VCU
 SG_ P10_BalSwCell17 : 51|1@0+ (1,0) [0|1] "" VCU
 SG_ P10_BalSwCell18 : 50|1@0+ (1,0) [0|1] "" VCU
 SG_ P10_BalSwCell19 : 49|1@0+ (1,0) [0|1] "" VCU
 SG_ P10_BalSwCell20 : 48|1@0+ (1,0) [0|1] "" VCU

BO_ 2554724522 BatP10_BMS_CellVoltageM5: 8 BMS
 SG_ P10_CellVoltage21 : 7|13@0+ (0.001,0) [0|5] "V" VCU
 SG_ P10_CellVoltage22 : 10|13@0+ (0.001,0) [0|5] "V" VCU
 SG_ P10_CellVoltage23 : 29|13@0+ (0.001,0) [0|5] "V" VCU
 SG_ P10_CellVoltage24 : 32|13@0+ (0.001,0) [0|5] "V" VCU
 SG_ P10_BalSwCell21 : 51|1@0+ (1,0) [0|1] "" VCU
 SG_ P10_BalSwCell22 : 50|1@0+ (1,0) [0|1] "" VCU
 SG_ P10_BalSwCell23 : 49|1@0+ (1,0) [0|1] "" VCU
 SG_ P10_BalSwCell24 : 48|1@0+ (1,0) [0|1] "" VCU

BO_ 2554790058 BatP10_BMS_CellVoltageM6: 8 BMS
 SG_ P10_CellVoltage25 : 7|13@0+ (0.001,0) [0|5] "V" VCU
 SG_ P10_CellVoltage26 : 10|13@0+ (0.001,0) [0|5] "V" VCU
 SG_ P10_CellVoltage27 : 29|13@0+ (0.001,0) [0|5] "V" VCU
 SG_ P10_CellVoltage28 : 32|13@0+ (0.001,0) [0|5] "V" VCU
 SG_ P10_BalSwCell25 : 51|1@0+ (1,0) [0|1] "" VCU
 SG_ P10_BalSwCell26 : 50|1@0+ (1,0) [0|1] "" VCU
 SG_ P10_BalSwCell27 : 49|1@0+ (1,0) [0|1] "" VCU
 SG_ P10_BalSwCell28 : 48|1@0+ (1,0) [0|1] "" VCU

BO_ 2554855594 BatP10_BMS_CellVoltageM7: 8 BMS
 SG_ P10_CellVoltage29 : 7|13@0+ (0.001,0) [0|5] "V" VCU
 SG_ P10_CellVoltage30 : 10|13@0+ (0.001,0) [0|5] "V" VCU
 SG_ P10_CellVoltage31 : 29|13@0+ (0.001,0) [0|5] "V" VCU
 SG_ P10_CellVoltage32 : 32|13@0+ (0.001,0) [0|5] "V" VCU
 SG_ P10_BalSwCell29 : 51|1@0+ (1,0) [0|1] "" VCU
 SG_ P10_BalSwCell30 : 50|1@0+ (1,0) [0|1] "" VCU
 SG_ P10_BalSwCell31 : 49|1@0+ (1,0) [0|1] "" VCU
 SG_ P10_BalSwCell32 : 48|1@0+ (1,0) [0|1] "" VCU

BO_ 2554921130 BatP10_BMS_CellVoltageM8: 8 BMS
 SG_ P10_CellVoltage33 : 7|13@0+ (0.001,0) [0|5] "V" VCU
 SG_ P10_CellVoltage34 : 10|13@0+ (0.001,0) [0|5] "V" VCU
 SG_ P10_CellVoltage35 : 29|13@0+ (0.001,0) [0|5] "V" VCU
 SG_ P10_CellVoltage36 : 32|13@0+ (0.001,0) [0|5] "V" VCU
 SG_ P10_BalSwCell33 : 51|1@0+ (1,0) [0|1] "" VCU
 SG_ P10_BalSwCell34 : 50|1@0+ (1,0) [0|1] "" VCU
 SG_ P10_BalSwCell35 : 49|1@0+ (1,0) [0|1] "" VCU
 SG_ P10_BalSwCell36 : 48|1@0+ (1,0) [0|1] "" VCU

BO_ 2554986666 BatP10_BMS_CellVoltageM9: 8 BMS
 SG_ P10_CellVoltage37 : 7|13@0+ (0.001,0) [0|5] "V" VCU
 SG_ P10_CellVoltage38 : 10|13@0+ (0.001,0) [0|5] "V" VCU
 SG_ P10_CellVoltage39 : 29|13@0+ (0.001,0) [0|5] "V" VCU
 SG_ P10_CellVoltage40 : 32|13@0+ (0.001,0) [0|5] "V" VCU
 SG_ P10_BalSwCell37 : 51|1@0+ (1,0) [0|1] "" VCU
 SG_ P10_BalSwCell38 : 50|1@0+ (1,0) [0|1] "" VCU
 SG_ P10_BalSwCell39 : 49|1@0+ (1,0) [0|1] "" VCU
 SG_ P10_BalSwCell40 : 48|1@0+ (1,0) [0|1] "" VCU

BO_ 2555052202 BatP10_BMS_CellVoltageM10: 8 BMS
 SG_ P10_CellVoltage41 : 7|13@0+ (0.001,0) [0|5] "V" VCU
 SG_ P10_CellVoltage42 : 10|13@0+ (0.001,0) [0|5] "V" VCU
 SG_ P10_CellVoltage43 : 29|13@0+ (0.001,0) [0|5] "V" VCU
 SG_ P10_CellVoltage44 : 32|13@0+ (0.001,0) [0|5] "V" VCU
 SG_ P10_BalSwCell41 : 51|1@0+ (1,0) [0|1] "" VCU
 SG_ P10_BalSwCell42 : 50|1@0+ (1,0) [0|1] "" VCU
 SG_ P10_BalSwCell43 : 49|1@0+ (1,0) [0|1] "" VCU
 SG_ P10_BalSwCell44 : 48|1@0+ (1,0) [0|1] "" VCU

BO_ 2555117738 BatP10_BMS_CellVoltageM11: 8 BMS
 SG_ P10_CellVoltage45 : 7|13@0+ (0.001,0) [0|5] "V" VCU
 SG_ P10_CellVoltage46 : 10|13@0+ (0.001,0) [0|5] "V" VCU
 SG_ P10_CellVoltage47 : 29|13@0+ (0.001,0) [0|5] "V" VCU
 SG_ P10_CellVoltage48 : 32|13@0+ (0.001,0) [0|5] "V" VCU
 SG_ P10_BalSwCell45 : 51|1@0+ (1,0) [0|1] "" VCU
 SG_ P10_BalSwCell46 : 50|1@0+ (1,0) [0|1] "" VCU
 SG_ P10_BalSwCell47 : 49|1@0+ (1,0) [0|1] "" VCU
 SG_ P10_BalSwCell48 : 48|1@0+ (1,0) [0|1] "" VCU

BO_ 2555183274 BatP10_BMS_CellVoltageM12: 8 BMS
 SG_ P10_CellVoltage49 : 7|13@0+ (0.001,0) [0|5] "V" VCU
 SG_ P10_CellVoltage50 : 10|13@0+ (0.001,0) [0|5] "V" VCU
 SG_ P10_CellVoltage51 : 29|13@0+ (0.001,0) [0|5] "V" VCU
 SG_ P10_CellVoltage52 : 32|13@0+ (0.001,0) [0|5] "V" VCU
 SG_ P10_BalSwCell49 : 51|1@0+ (1,0) [0|1] "" VCU
 SG_ P10_BalSwCell50 : 50|1@0+ (1,0) [0|1] "" VCU
 SG_ P10_BalSwCell51 : 49|1@0+ (1,0) [0|1] "" VCU
 SG_ P10_BalSwCell52 : 48|1@0+ (1,0) [0|1] "" VCU

BO_ 2555248810 BatP10_BMS_CellVoltageM13: 8 BMS
 SG_ P10_CellVoltage53 : 7|13@0+ (0.001,0) [0|5] "V" VCU
 SG_ P10_CellVoltage54 : 10|13@0+ (0.001,0) [0|5] "V" VCU
 SG_ P10_CellVoltage55 : 29|13@0+ (0.001,0) [0|5] "V" VCU
 SG_ P10_CellVoltage56 : 32|13@0+ (0.001,0) [0|5] "V" VCU
 SG_ P10_BalSwCell53 : 51|1@0+ (1,0) [0|1] "" VCU
 SG_ P10_BalSwCell54 : 50|1@0+ (1,0) [0|1] "" VCU
 SG_ P10_BalSwCell55 : 49|1@0+ (1,0) [0|1] "" VCU
 SG_ P10_BalSwCell56 : 48|1@0+ (1,0) [0|1] "" VCU

BO_ 2555314346 BatP10_BMS_CellVoltageM14: 8 BMS
 SG_ P10_CellVoltage57 : 7|13@0+ (0.001,0) [0|5] "V" VCU
 SG_ P10_CellVoltage58 : 10|13@0+ (0.001,0) [0|5] "V" VCU
 SG_ P10_CellVoltage59 : 29|13@0+ (0.001,0) [0|5] "V" VCU
 SG_ P10_CellVoltage60 : 32|13@0+ (0.001,0) [0|5] "V" VCU
 SG_ P10_BalSwCell57 : 51|1@0+ (1,0) [0|1] "" VCU
 SG_ P10_BalSwCell58 : 50|1@0+ (1,0) [0|1] "" VCU
 SG_ P10_BalSwCell59 : 49|1@0+ (1,0) [0|1] "" VCU
 SG_ P10_BalSwCell60 : 48|1@0+ (1,0) [0|1] "" VCU

BO_ 2555379882 BatP10_BMS_CellVoltageM15: 8 BMS
 SG_ P10_CellVoltage61 : 7|13@0+ (0.001,0) [0|5] "V" VCU
 SG_ P10_CellVoltage62 : 10|13@0+ (0.001,0) [0|5] "V" VCU
 SG_ P10_CellVoltage63 : 29|13@0+ (0.001,0) [0|5] "V" VCU
 SG_ P10_CellVoltage64 : 32|13@0+ (0.001,0) [0|5] "V" VCU
 SG_ P10_BalSwCell61 : 51|1@0+ (1,0) [0|1] "" VCU
 SG_ P10_BalSwCell62 : 50|1@0+ (1,0) [0|1] "" VCU
 SG_ P10_BalSwCell63 : 49|1@0+ (1,0) [0|1] "" VCU
 SG_ P10_BalSwCell64 : 48|1@0+ (1,0) [0|1] "" VCU

BO_ 2555445418 BatP10_BMS_CellVoltageM16: 8 BMS
 SG_ P10_CellVoltage65 : 7|13@0+ (0.001,0) [0|5] "V" VCU
 SG_ P10_CellVoltage66 : 10|13@0+ (0.001,0) [0|5] "V" VCU
 SG_ P10_CellVoltage67 : 29|13@0+ (0.001,0) [0|5] "V" VCU
 SG_ P10_CellVoltage68 : 32|13@0+ (0.001,0) [0|5] "V" VCU
 SG_ P10_BalSwCell65 : 51|1@0+ (1,0) [0|1] "" VCU
 SG_ P10_BalSwCell66 : 50|1@0+ (1,0) [0|1] "" VCU
 SG_ P10_BalSwCell67 : 49|1@0+ (1,0) [0|1] "" VCU
 SG_ P10_BalSwCell68 : 48|1@0+ (1,0) [0|1] "" VCU

BO_ 2555510954 BatP10_BMS_CellVoltageM17: 8 BMS
 SG_ P10_CellVoltage69 : 7|13@0+ (0.001,0) [0|5] "V" VCU
 SG_ P10_CellVoltage70 : 10|13@0+ (0.001,0) [0|5] "V" VCU
 SG_ P10_CellVoltage71 : 29|13@0+ (0.001,0) [0|5] "V" VCU
 SG_ P10_CellVoltage72 : 32|13@0+ (0.001,0) [0|5] "V" VCU
 SG_ P10_BalSwCell69 : 51|1@0+ (1,0) [0|1] "" VCU
 SG_ P10_BalSwCell70 : 50|1@0+ (1,0) [0|1] "" VCU
 SG_ P10_BalSwCell71 : 49|1@0+ (1,0) [0|1] "" VCU
 SG_ P10_BalSwCell72 : 48|1@0+ (1,0) [0|1] "" VCU

BO_ 2555576490 BatP10_BMS_CellVoltageM18: 8 BMS
 SG_ P10_CellVoltage73 : 7|13@0+ (0.001,0) [0|5] "V" VCU
 SG_ P10_CellVoltage74 : 10|13@0+ (0.001,0) [0|5] "V" VCU
 SG_ P10_CellVoltage75 : 29|13@0+ (0.001,0) [0|5] "V" VCU
 SG_ P10_CellVoltage76 : 32|13@0+ (0.001,0) [0|5] "V" VCU
 SG_ P10_BalSwCell73 : 51|1@0+ (1,0) [0|1] "" VCU
 SG_ P10_BalSwCell74 : 50|1@0+ (1,0) [0|1] "" VCU
 SG_ P10_BalSwCell75 : 49|1@0+ (1,0) [0|1] "" VCU
 SG_ P10_BalSwCell76 : 48|1@0+ (1,0) [0|1] "" VCU

BO_ 2555642026 BatP10_BMS_CellVoltageM19: 8 BMS
 SG_ P10_CellVoltage77 : 7|13@0+ (0.001,0) [0|5] "V" VCU
 SG_ P10_CellVoltage78 : 10|13@0+ (0.001,0) [0|5] "V" VCU
 SG_ P10_CellVoltage79 : 29|13@0+ (0.001,0) [0|5] "V" VCU
 SG_ P10_CellVoltage80 : 32|13@0+ (0.001,0) [0|5] "V" VCU
 SG_ P10_BalSwCell77 : 51|1@0+ (1,0) [0|1] "" VCU
 SG_ P10_BalSwCell78 : 50|1@0+ (1,0) [0|1] "" VCU
 SG_ P10_BalSwCell79 : 49|1@0+ (1,0) [0|1] "" VCU
 SG_ P10_BalSwCell80 : 48|1@0+ (1,0) [0|1] "" VCU

BO_ 2555707562 BatP10_BMS_CellVoltageM20: 8 BMS
 SG_ P10_CellVoltage81 : 7|13@0+ (0.001,0) [0|5] "V" VCU
 SG_ P10_CellVoltage82 : 10|13@0+ (0.001,0) [0|5] "V" VCU
 SG_ P10_CellVoltage83 : 29|13@0+ (0.001,0) [0|5] "V" VCU
 SG_ P10_CellVoltage84 : 32|13@0+ (0.001,0) [0|5] "V" VCU
 SG_ P10_BalSwCell81 : 51|1@0+ (1,0) [0|1] "" VCU
 SG_ P10_BalSwCell82 : 50|1@0+ (1,0) [0|1] "" VCU
 SG_ P10_BalSwCell83 : 49|1@0+ (1,0) [0|1] "" VCU
 SG_ P10_BalSwCell84 : 48|1@0+ (1,0) [0|1] "" VCU

BO_ 2555773098 BatP10_BMS_CellVoltageM21: 8 BMS
 SG_ P10_CellVoltage85 : 7|13@0+ (0.001,0) [0|5] "V" VCU
 SG_ P10_CellVoltage86 : 10|13@0+ (0.001,0) [0|5] "V" VCU
 SG_ P10_CellVoltage87 : 29|13@0+ (0.001,0) [0|5] "V" VCU
 SG_ P10_CellVoltage88 : 32|13@0+ (0.001,0) [0|5] "V" VCU
 SG_ P10_BalSwCell85 : 51|1@0+ (1,0) [0|1] "" VCU
 SG_ P10_BalSwCell86 : 50|1@0+ (1,0) [0|1] "" VCU
 SG_ P10_BalSwCell87 : 49|1@0+ (1,0) [0|1] "" VCU
 SG_ P10_BalSwCell88 : 48|1@0+ (1,0) [0|1] "" VCU

BO_ 2555838634 BatP10_BMS_CellVoltageM22: 8 BMS
 SG_ P10_CellVoltage89 : 7|13@0+ (0.001,0) [0|5] "V" VCU
 SG_ P10_CellVoltage90 : 10|13@0+ (0.001,0) [0|5] "V" VCU
 SG_ P10_CellVoltage91 : 29|13@0+ (0.001,0) [0|5] "V" VCU
 SG_ P10_CellVoltage92 : 32|13@0+ (0.001,0) [0|5] "V" VCU
 SG_ P10_BalSwCell89 : 51|1@0+ (1,0) [0|1] "" VCU
 SG_ P10_BalSwCell90 : 50|1@0+ (1,0) [0|1] "" VCU
 SG_ P10_BalSwCell91 : 49|1@0+ (1,0) [0|1] "" VCU
 SG_ P10_BalSwCell92 : 48|1@0+ (1,0) [0|1] "" VCU

BO_ 2555904170 BatP10_BMS_CellVoltageM23: 8 BMS
 SG_ P10_CellVoltage93 : 7|13@0+ (0.001,0) [0|5] "V" VCU
 SG_ P10_CellVoltage94 : 10|13@0+ (0.001,0) [0|5] "V" VCU
 SG_ P10_CellVoltage95 : 29|13@0+ (0.001,0) [0|5] "V" VCU
 SG_ P10_CellVoltage96 : 32|13@0+ (0.001,0) [0|5] "V" VCU
 SG_ P10_BalSwCell93 : 51|1@0+ (1,0) [0|1] "" VCU
 SG_ P10_BalSwCell94 : 50|1@0+ (1,0) [0|1] "" VCU
 SG_ P10_BalSwCell95 : 49|1@0+ (1,0) [0|1] "" VCU
 SG_ P10_BalSwCell96 : 48|1@0+ (1,0) [0|1] "" VCU

BO_ 2555969706 BatP10_BMS_CellVoltageM24: 8 BMS
 SG_ P10_CellVoltage97 : 7|13@0+ (0.001,0) [0|5] "V" VCU
 SG_ P10_CellVoltage98 : 10|13@0+ (0.001,0) [0|5] "V" VCU
 SG_ P10_CellVoltage99 : 29|13@0+ (0.001,0) [0|5] "V" VCU
 SG_ P10_CellVoltage100 : 32|13@0+ (0.001,0) [0|5] "V" VCU
 SG_ P10_BalSwCell97 : 51|1@0+ (1,0) [0|1] "" VCU
 SG_ P10_BalSwCell98 : 50|1@0+ (1,0) [0|1] "" VCU
 SG_ P10_BalSwCell99 : 49|1@0+ (1,0) [0|1] "" VCU
 SG_ P10_BalSwCell100 : 48|1@0+ (1,0) [0|1] "" VCU

BO_ 2556035242 BatP10_BMS_CellVoltageM25: 8 BMS
 SG_ P10_CellVoltage101 : 7|13@0+ (0.001,0) [0|5] "V" VCU
 SG_ P10_CellVoltage102 : 10|13@0+ (0.001,0) [0|5] "V" VCU
 SG_ P10_CellVoltage103 : 29|13@0+ (0.001,0) [0|5] "V" VCU
 SG_ P10_CellVoltage104 : 32|13@0+ (0.001,0) [0|5] "V" VCU
 SG_ P10_BalSwCell101 : 51|1@0+ (1,0) [0|1] "" VCU
 SG_ P10_BalSwCell102 : 50|1@0+ (1,0) [0|1] "" VCU
 SG_ P10_BalSwCell103 : 49|1@0+ (1,0) [0|1] "" VCU
 SG_ P10_BalSwCell104 : 48|1@0+ (1,0) [0|1] "" VCU

BO_ 2556100778 BatP10_BMS_CellVoltageM26: 8 BMS
 SG_ P10_CellVoltage105 : 7|13@0+ (0.001,0) [0|5] "V" VCU
 SG_ P10_CellVoltage106 : 10|13@0+ (0.001,0) [0|5] "V" VCU
 SG_ P10_CellVoltage107 : 29|13@0+ (0.001,0) [0|5] "V" VCU
 SG_ P10_CellVoltage108 : 32|13@0+ (0.001,0) [0|5] "V" VCU
 SG_ P10_BalSwCell105 : 51|1@0+ (1,0) [0|1] "" VCU
 SG_ P10_BalSwCell106 : 50|1@0+ (1,0) [0|1] "" VCU
 SG_ P10_BalSwCell107 : 49|1@0+ (1,0) [0|1] "" VCU
 SG_ P10_BalSwCell108 : 48|1@0+ (1,0) [0|1] "" VCU

BO_ 2556166314 BatP10_BMS_CellVoltageM27: 8 BMS
 SG_ P10_CellVoltage109 : 7|13@0+ (0.001,0) [0|5] "V" VCU
 SG_ P10_CellVoltage110 : 10|13@0+ (0.001,0) [0|5] "V" VCU
 SG_ P10_CellVoltage111 : 29|13@0+ (0.001,0) [0|5] "V" VCU
 SG_ P10_CellVoltage112 : 32|13@0+ (0.001,0) [0|5] "V" VCU
 SG_ P10_BalSwCell109 : 51|1@0+ (1,0) [0|1] "" VCU
 SG_ P10_BalSwCell110 : 50|1@0+ (1,0) [0|1] "" VCU
 SG_ P10_BalSwCell111 : 49|1@0+ (1,0) [0|1] "" VCU
 SG_ P10_BalSwCell112 : 48|1@0+ (1,0) [0|1] "" VCU

BO_ 2556231850 BatP10_BMS_CellVoltageM28: 8 BMS
 SG_ P10_CellVoltage113 : 7|13@0+ (0.001,0) [0|5] "V" VCU
 SG_ P10_CellVoltage114 : 10|13@0+ (0.001,0) [0|5] "V" VCU
 SG_ P10_CellVoltage115 : 29|13@0+ (0.001,0) [0|5] "V" VCU
 SG_ P10_CellVoltage116 : 32|13@0+ (0.001,0) [0|5] "V" VCU
 SG_ P10_BalSwCell113 : 51|1@0+ (1,0) [0|1] "" VCU
 SG_ P10_BalSwCell114 : 50|1@0+ (1,0) [0|1] "" VCU
 SG_ P10_BalSwCell115 : 49|1@0+ (1,0) [0|1] "" VCU
 SG_ P10_BalSwCell116 : 48|1@0+ (1,0) [0|1] "" VCU

BO_ 2556297386 BatP10_BMS_CellVoltageM29: 8 BMS
 SG_ P10_CellVoltage117 : 7|13@0+ (0.001,0) [0|5] "V" VCU
 SG_ P10_CellVoltage118 : 10|13@0+ (0.001,0) [0|5] "V" VCU
 SG_ P10_CellVoltage119 : 29|13@0+ (0.001,0) [0|5] "V" VCU
 SG_ P10_CellVoltage120 : 32|13@0+ (0.001,0) [0|5] "V" VCU
 SG_ P10_BalSwCell117 : 51|1@0+ (1,0) [0|1] "" VCU
 SG_ P10_BalSwCell118 : 50|1@0+ (1,0) [0|1] "" VCU
 SG_ P10_BalSwCell119 : 49|1@0+ (1,0) [0|1] "" VCU
 SG_ P10_BalSwCell120 : 48|1@0+ (1,0) [0|1] "" VCU

BO_ 2556362922 BatP10_BMS_CellVoltageM30: 8 BMS
 SG_ P10_CellVoltage121 : 7|13@0+ (0.001,0) [0|5] "V" VCU
 SG_ P10_CellVoltage122 : 10|13@0+ (0.001,0) [0|5] "V" VCU
 SG_ P10_CellVoltage123 : 29|13@0+ (0.001,0) [0|5] "V" VCU
 SG_ P10_CellVoltage124 : 32|13@0+ (0.001,0) [0|5] "V" VCU
 SG_ P10_BalSwCell121 : 51|1@0+ (1,0) [0|1] "" VCU
 SG_ P10_BalSwCell122 : 50|1@0+ (1,0) [0|1] "" VCU
 SG_ P10_BalSwCell123 : 49|1@0+ (1,0) [0|1] "" VCU
 SG_ P10_BalSwCell124 : 48|1@0+ (1,0) [0|1] "" VCU

BO_ 2556428458 BatP10_BMS_CellVoltageM31: 8 BMS
 SG_ P10_CellVoltage125 : 7|13@0+ (0.001,0) [0|5] "V" VCU
 SG_ P10_CellVoltage126 : 10|13@0+ (0.001,0) [0|5] "V" VCU
 SG_ P10_CellVoltage127 : 29|13@0+ (0.001,0) [0|5] "V" VCU
 SG_ P10_CellVoltage128 : 32|13@0+ (0.001,0) [0|5] "V" VCU
 SG_ P10_BalSwCell125 : 51|1@0+ (1,0) [0|1] "" VCU
 SG_ P10_BalSwCell126 : 50|1@0+ (1,0) [0|1] "" VCU
 SG_ P10_BalSwCell127 : 49|1@0+ (1,0) [0|1] "" VCU
 SG_ P10_BalSwCell128 : 48|1@0+ (1,0) [0|1] "" VCU

BO_ 2556493994 BatP10_BMS_CellVoltageM32: 8 BMS
 SG_ P10_CellVoltage129 : 7|13@0+ (0.001,0) [0|5] "V" VCU
 SG_ P10_CellVoltage130 : 10|13@0+ (0.001,0) [0|5] "V" VCU
 SG_ P10_CellVoltage131 : 29|13@0+ (0.001,0) [0|5] "V" VCU
 SG_ P10_CellVoltage132 : 32|13@0+ (0.001,0) [0|5] "V" VCU
 SG_ P10_BalSwCell129 : 51|1@0+ (1,0) [0|1] "" VCU
 SG_ P10_BalSwCell130 : 50|1@0+ (1,0) [0|1] "" VCU
 SG_ P10_BalSwCell131 : 49|1@0+ (1,0) [0|1] "" VCU
 SG_ P10_BalSwCell132 : 48|1@0+ (1,0) [0|1] "" VCU

BO_ 2556559530 BatP10_BMS_CellVoltageM33: 8 BMS
 SG_ P10_CellVoltage133 : 7|13@0+ (0.001,0) [0|5] "V" VCU
 SG_ P10_CellVoltage134 : 10|13@0+ (0.001,0) [0|5] "V" VCU
 SG_ P10_CellVoltage135 : 29|13@0+ (0.001,0) [0|5] "V" VCU
 SG_ P10_CellVoltage136 : 32|13@0+ (0.001,0) [0|5] "V" VCU
 SG_ P10_BalSwCell133 : 51|1@0+ (1,0) [0|1] "" VCU
 SG_ P10_BalSwCell134 : 50|1@0+ (1,0) [0|1] "" VCU
 SG_ P10_BalSwCell135 : 49|1@0+ (1,0) [0|1] "" VCU
 SG_ P10_BalSwCell136 : 48|1@0+ (1,0) [0|1] "" VCU

BO_ 2556625066 BatP10_BMS_CellVoltageM34: 8 BMS
 SG_ P10_CellVoltage137 : 7|13@0+ (0.001,0) [0|5] "V" VCU
 SG_ P10_CellVoltage138 : 10|13@0+ (0.001,0) [0|5] "V" VCU
 SG_ P10_CellVoltage139 : 29|13@0+ (0.001,0) [0|5] "V" VCU
 SG_ P10_CellVoltage140 : 32|13@0+ (0.001,0) [0|5] "V" VCU
 SG_ P10_BalSwCell137 : 51|1@0+ (1,0) [0|1] "" VCU
 SG_ P10_BalSwCell138 : 50|1@0+ (1,0) [0|1] "" VCU
 SG_ P10_BalSwCell139 : 49|1@0+ (1,0) [0|1] "" VCU
 SG_ P10_BalSwCell140 : 48|1@0+ (1,0) [0|1] "" VCU

BO_ 2556690602 BatP10_BMS_CellVoltageM35: 8 BMS
 SG_ P10_CellVoltage141 : 7|13@0+ (0.001,0) [0|5] "V" VCU
 SG_ P10_CellVoltage142 : 10|13@0+ (0.001,0) [0|5] "V" VCU
 SG_ P10_CellVoltage143 : 29|13@0+ (0.001,0) [0|5] "V" VCU
 SG_ P10_CellVoltage144 : 32|13@0+ (0.001,0) [0|5] "V" VCU
 SG_ P10_BalSwCell141 : 51|1@0+ (1,0) [0|1] "" VCU
 SG_ P10_BalSwCell142 : 50|1@0+ (1,0) [0|1] "" VCU
 SG_ P10_BalSwCell143 : 49|1@0+ (1,0) [0|1] "" VCU
 SG_ P10_BalSwCell144 : 48|1@0+ (1,0) [0|1] "" VCU

BO_ 2556756138 BatP10_BMS_CellVoltageM36: 8 BMS
 SG_ P10_CellVoltage145 : 7|13@0+ (0.001,0) [0|5] "V" VCU
 SG_ P10_CellVoltage146 : 10|13@0+ (0.001,0) [0|5] "V" VCU
 SG_ P10_CellVoltage147 : 29|13@0+ (0.001,0) [0|5] "V" VCU
 SG_ P10_CellVoltage148 : 32|13@0+ (0.001,0) [0|5] "V" VCU
 SG_ P10_BalSwCell145 : 51|1@0+ (1,0) [0|1] "" VCU
 SG_ P10_BalSwCell146 : 50|1@0+ (1,0) [0|1] "" VCU
 SG_ P10_BalSwCell147 : 49|1@0+ (1,0) [0|1] "" VCU
 SG_ P10_BalSwCell148 : 48|1@0+ (1,0) [0|1] "" VCU

BO_ 2556821674 BatP10_BMS_CellVoltageM37: 8 BMS
 SG_ P10_CellVoltage149 : 7|13@0+ (0.001,0) [0|5] "V" VCU
 SG_ P10_CellVoltage150 : 10|13@0+ (0.001,0) [0|5] "V" VCU
 SG_ P10_CellVoltage151 : 29|13@0+ (0.001,0) [0|5] "V" VCU
 SG_ P10_CellVoltage152 : 32|13@0+ (0.001,0) [0|5] "V" VCU
 SG_ P10_BalSwCell149 : 51|1@0+ (1,0) [0|1] "" VCU
 SG_ P10_BalSwCell150 : 50|1@0+ (1,0) [0|1] "" VCU
 SG_ P10_BalSwCell151 : 49|1@0+ (1,0) [0|1] "" VCU
 SG_ P10_BalSwCell152 : 48|1@0+ (1,0) [0|1] "" VCU

BO_ 2556887210 BatP10_BMS_CellVoltageM38: 8 BMS
 SG_ P10_CellVoltage153 : 7|13@0+ (0.001,0) [0|5] "V" VCU
 SG_ P10_CellVoltage154 : 10|13@0+ (0.001,0) [0|5] "V" VCU
 SG_ P10_CellVoltage155 : 29|13@0+ (0.001,0) [0|5] "V" VCU
 SG_ P10_CellVoltage156 : 32|13@0+ (0.001,0) [0|5] "V" VCU
 SG_ P10_BalSwCell153 : 51|1@0+ (1,0) [0|1] "" VCU
 SG_ P10_BalSwCell154 : 50|1@0+ (1,0) [0|1] "" VCU
 SG_ P10_BalSwCell155 : 49|1@0+ (1,0) [0|1] "" VCU
 SG_ P10_BalSwCell156 : 48|1@0+ (1,0) [0|1] "" VCU

BO_ 2556952746 BatP10_BMS_CellVoltageM39: 8 BMS
 SG_ P10_CellVoltage157 : 7|13@0+ (0.001,0) [0|5] "V" VCU
 SG_ P10_CellVoltage158 : 10|13@0+ (0.001,0) [0|5] "V" VCU
 SG_ P10_CellVoltage159 : 29|13@0+ (0.001,0) [0|5] "V" VCU
 SG_ P10_CellVoltage160 : 32|13@0+ (0.001,0) [0|5] "V" VCU
 SG_ P10_BalSwCell157 : 51|1@0+ (1,0) [0|1] "" VCU
 SG_ P10_BalSwCell158 : 50|1@0+ (1,0) [0|1] "" VCU
 SG_ P10_BalSwCell159 : 49|1@0+ (1,0) [0|1] "" VCU
 SG_ P10_BalSwCell160 : 48|1@0+ (1,0) [0|1] "" VCU

BO_ 2557018282 BatP10_BMS_CellVoltageM40: 8 BMS
 SG_ P10_CellVoltage161 : 7|13@0+ (0.001,0) [0|5] "V" VCU
 SG_ P10_CellVoltage162 : 10|13@0+ (0.001,0) [0|5] "V" VCU
 SG_ P10_CellVoltage163 : 29|13@0+ (0.001,0) [0|5] "V" VCU
 SG_ P10_CellVoltage164 : 32|13@0+ (0.001,0) [0|5] "V" VCU
 SG_ P10_BalSwCell161 : 51|1@0+ (1,0) [0|1] "" VCU
 SG_ P10_BalSwCell162 : 50|1@0+ (1,0) [0|1] "" VCU
 SG_ P10_BalSwCell163 : 49|1@0+ (1,0) [0|1] "" VCU
 SG_ P10_BalSwCell164 : 48|1@0+ (1,0) [0|1] "" VCU

BO_ 2557083818 BatP10_BMS_CellVoltageM41: 8 BMS
 SG_ P10_CellVoltage165 : 7|13@0+ (0.001,0) [0|5] "V" VCU
 SG_ P10_CellVoltage166 : 10|13@0+ (0.001,0) [0|5] "V" VCU
 SG_ P10_CellVoltage167 : 29|13@0+ (0.001,0) [0|5] "V" VCU
 SG_ P10_CellVoltage168 : 32|13@0+ (0.001,0) [0|5] "V" VCU
 SG_ P10_BalSwCell165 : 51|1@0+ (1,0) [0|1] "" VCU
 SG_ P10_BalSwCell166 : 50|1@0+ (1,0) [0|1] "" VCU
 SG_ P10_BalSwCell167 : 49|1@0+ (1,0) [0|1] "" VCU
 SG_ P10_BalSwCell168 : 48|1@0+ (1,0) [0|1] "" VCU

BO_ 2557149354 BatP10_BMS_CellVoltageM42: 8 BMS
 SG_ P10_CellVoltage169 : 7|13@0+ (0.001,0) [0|5] "V" VCU
 SG_ P10_CellVoltage170 : 10|13@0+ (0.001,0) [0|5] "V" VCU
 SG_ P10_CellVoltage171 : 29|13@0+ (0.001,0) [0|5] "V" VCU
 SG_ P10_CellVoltage172 : 32|13@0+ (0.001,0) [0|5] "V" VCU
 SG_ P10_BalSwCell169 : 51|1@0+ (1,0) [0|1] "" VCU
 SG_ P10_BalSwCell170 : 50|1@0+ (1,0) [0|1] "" VCU
 SG_ P10_BalSwCell171 : 49|1@0+ (1,0) [0|1] "" VCU
 SG_ P10_BalSwCell172 : 48|1@0+ (1,0) [0|1] "" VCU

BO_ 2557214890 BatP10_BMS_CellVoltageM43: 8 BMS
 SG_ P10_CellVoltage173 : 7|13@0+ (0.001,0) [0|5] "V" VCU
 SG_ P10_CellVoltage174 : 10|13@0+ (0.001,0) [0|5] "V" VCU
 SG_ P10_CellVoltage175 : 29|13@0+ (0.001,0) [0|5] "V" VCU
 SG_ P10_CellVoltage176 : 32|13@0+ (0.001,0) [0|5] "V" VCU
 SG_ P10_BalSwCell173 : 51|1@0+ (1,0) [0|1] "" VCU
 SG_ P10_BalSwCell174 : 50|1@0+ (1,0) [0|1] "" VCU
 SG_ P10_BalSwCell175 : 49|1@0+ (1,0) [0|1] "" VCU
 SG_ P10_BalSwCell176 : 48|1@0+ (1,0) [0|1] "" VCU

BO_ 2557280426 BatP10_BMS_CellVoltageM44: 8 BMS
 SG_ P10_CellVoltage177 : 7|13@0+ (0.001,0) [0|5] "V" VCU
 SG_ P10_CellVoltage178 : 10|13@0+ (0.001,0) [0|5] "V" VCU
 SG_ P10_CellVoltage179 : 29|13@0+ (0.001,0) [0|5] "V" VCU
 SG_ P10_CellVoltage180 : 32|13@0+ (0.001,0) [0|5] "V" VCU
 SG_ P10_BalSwCell177 : 51|1@0+ (1,0) [0|1] "" VCU
 SG_ P10_BalSwCell178 : 50|1@0+ (1,0) [0|1] "" VCU
 SG_ P10_BalSwCell179 : 49|1@0+ (1,0) [0|1] "" VCU
 SG_ P10_BalSwCell180 : 48|1@0+ (1,0) [0|1] "" VCU

BO_ 2557345962 BatP10_BMS_CellVoltageM45: 8 BMS
 SG_ P10_CellVoltage181 : 7|13@0+ (0.001,0) [0|5] "V" VCU
 SG_ P10_CellVoltage182 : 10|13@0+ (0.001,0) [0|5] "V" VCU
 SG_ P10_CellVoltage183 : 29|13@0+ (0.001,0) [0|5] "V" VCU
 SG_ P10_CellVoltage184 : 32|13@0+ (0.001,0) [0|5] "V" VCU
 SG_ P10_BalSwCell181 : 51|1@0+ (1,0) [0|1] "" VCU
 SG_ P10_BalSwCell182 : 50|1@0+ (1,0) [0|1] "" VCU
 SG_ P10_BalSwCell183 : 49|1@0+ (1,0) [0|1] "" VCU
 SG_ P10_BalSwCell184 : 48|1@0+ (1,0) [0|1] "" VCU

BO_ 2557411498 BatP10_BMS_CellVoltageM46: 8 BMS
 SG_ P10_CellVoltage185 : 7|13@0+ (0.001,0) [0|5] "V" VCU
 SG_ P10_CellVoltage186 : 10|13@0+ (0.001,0) [0|5] "V" VCU
 SG_ P10_CellVoltage187 : 29|13@0+ (0.001,0) [0|5] "V" VCU
 SG_ P10_CellVoltage188 : 32|13@0+ (0.001,0) [0|5] "V" VCU
 SG_ P10_BalSwCell185 : 51|1@0+ (1,0) [0|1] "" VCU
 SG_ P10_BalSwCell186 : 50|1@0+ (1,0) [0|1] "" VCU
 SG_ P10_BalSwCell187 : 49|1@0+ (1,0) [0|1] "" VCU
 SG_ P10_BalSwCell188 : 48|1@0+ (1,0) [0|1] "" VCU

BO_ 2557477034 BatP10_BMS_CellVoltageM47: 8 BMS
 SG_ P10_CellVoltage189 : 7|13@0+ (0.001,0) [0|5] "V" VCU
 SG_ P10_CellVoltage190 : 10|13@0+ (0.001,0) [0|5] "V" VCU
 SG_ P10_CellVoltage191 : 29|13@0+ (0.001,0) [0|5] "V" VCU
 SG_ P10_CellVoltage192 : 32|13@0+ (0.001,0) [0|5] "V" VCU
 SG_ P10_BalSwCell189 : 51|1@0+ (1,0) [0|1] "" VCU
 SG_ P10_BalSwCell190 : 50|1@0+ (1,0) [0|1] "" VCU
 SG_ P10_BalSwCell191 : 49|1@0+ (1,0) [0|1] "" VCU
 SG_ P10_BalSwCell192 : 48|1@0+ (1,0) [0|1] "" VCU

BO_ 2558525610 BatP10_BMS_CellTempM0: 8 BMS
 SG_ P10_CellTemp1 : 7|11@0+ (0.1,-40) [-40|150] "C" VCU
 SG_ P10_CellTemp2 : 12|11@0+ (0.1,-40) [-40|150] "C" VCU
 SG_ P10_CellTemp3 : 17|11@0+ (0.1,-40) [-40|150] "C" VCU
 SG_ P10_CellTemp4 : 38|11@0+ (0.1,-40) [-40|150] "C" VCU
 SG_ P10_CellTemp5 : 43|11@0+ (0.1,-40) [-40|150] "C" VCU

BO_ 2558591146 BatP10_BMS_CellTempM1: 8 BMS
 SG_ P10_CellTemp6 : 7|11@0+ (0.1,-40) [-40|150] "C" VCU
 SG_ P10_CellTemp7 : 12|11@0+ (0.1,-40) [-40|150] "C" VCU
 SG_ P10_CellTemp8 : 17|11@0+ (0.1,-40) [-40|150] "C" VCU
 SG_ P10_CellTemp9 : 38|11@0+ (0.1,-40) [-40|150] "C" VCU
 SG_ P10_CellTemp10 : 43|11@0+ (0.1,-40) [-40|150] "C" VCU

BO_ 2558656682 BatP10_BMS_CellTempM2: 8 BMS
 SG_ P10_CellTemp11 : 7|11@0+ (0.1,-40) [-40|150] "C" VCU
 SG_ P10_CellTemp12 : 12|11@0+ (0.1,-40) [-40|150] "C" VCU
 SG_ P10_CellTemp13 : 17|11@0+ (0.1,-40) [-40|150] "C" VCU
 SG_ P10_CellTemp14 : 38|11@0+ (0.1,-40) [-40|150] "C" VCU
 SG_ P10_CellTemp15 : 43|11@0+ (0.1,-40) [-40|150] "C" VCU

BO_ 2558722218 BatP10_BMS_CellTempM3: 8 BMS
 SG_ P10_CellTemp16 : 7|11@0+ (0.1,-40) [-40|150] "C" VCU
 SG_ P10_CellTemp17 : 12|11@0+ (0.1,-40) [-40|150] "C" VCU
 SG_ P10_CellTemp18 : 17|11@0+ (0.1,-40) [-40|150] "C" VCU
 SG_ P10_CellTemp19 : 38|11@0+ (0.1,-40) [-40|150] "C" VCU
 SG_ P10_CellTemp20 : 43|11@0+ (0.1,-40) [-40|150] "C" VCU

BO_ 2558787754 BatP10_BMS_CellTempM4: 8 BMS
 SG_ P10_CellTemp21 : 7|11@0+ (0.1,-40) [-40|150] "C" VCU
 SG_ P10_CellTemp22 : 12|11@0+ (0.1,-40) [-40|150] "C" VCU
 SG_ P10_CellTemp23 : 17|11@0+ (0.1,-40) [-40|150] "C" VCU
 SG_ P10_CellTemp24 : 38|11@0+ (0.1,-40) [-40|150] "C" VCU
 SG_ P10_CellTemp25 : 43|11@0+ (0.1,-40) [-40|150] "C" VCU

BO_ 2558853290 BatP10_BMS_CellTempM5: 8 BMS
 SG_ P10_CellTemp26 : 7|11@0+ (0.1,-40) [-40|150] "C" VCU
 SG_ P10_CellTemp27 : 12|11@0+ (0.1,-40) [-40|150] "C" VCU
 SG_ P10_CellTemp28 : 17|11@0+ (0.1,-40) [-40|150] "C" VCU
 SG_ P10_CellTemp29 : 38|11@0+ (0.1,-40) [-40|150] "C" VCU
 SG_ P10_CellTemp30 : 43|11@0+ (0.1,-40) [-40|150] "C" VCU

BO_ 2558918826 BatP10_BMS_CellTempM6: 8 BMS
 SG_ P10_CellTemp31 : 7|11@0+ (0.1,-40) [-40|150] "C" VCU
 SG_ P10_CellTemp32 : 12|11@0+ (0.1,-40) [-40|150] "C" VCU
 SG_ P10_CellTemp33 : 17|11@0+ (0.1,-40) [-40|150] "C" VCU
 SG_ P10_CellTemp34 : 38|11@0+ (0.1,-40) [-40|150] "C" VCU
 SG_ P10_CellTemp35 : 43|11@0+ (0.1,-40) [-40|150] "C" VCU

BO_ 2558984362 BatP10_BMS_CellTempM7: 8 BMS
 SG_ P10_CellTemp36 : 7|11@0+ (0.1,-40) [-40|150] "C" VCU
 SG_ P10_CellTemp37 : 12|11@0+ (0.1,-40) [-40|150] "C" VCU
 SG_ P10_CellTemp38 : 17|11@0+ (0.1,-40) [-40|150] "C" VCU
 SG_ P10_CellTemp39 : 38|11@0+ (0.1,-40) [-40|150] "C" VCU
 SG_ P10_CellTemp40 : 43|11@0+ (0.1,-40) [-40|150] "C" VCU

BO_ 2559049898 BatP10_BMS_CellTempM8: 8 BMS
 SG_ P10_CellTemp41 : 7|11@0+ (0.1,-40) [-40|150] "C" VCU
 SG_ P10_CellTemp42 : 12|11@0+ (0.1,-40) [-40|150] "C" VCU
 SG_ P10_CellTemp43 : 17|11@0+ (0.1,-40) [-40|150] "C" VCU
 SG_ P10_CellTemp44 : 38|11@0+ (0.1,-40) [-40|150] "C" VCU
 SG_ P10_CellTemp45 : 43|11@0+ (0.1,-40) [-40|150] "C" VCU

BO_ 2559115434 BatP10_BMS_CellTempM9: 8 BMS
 SG_ P10_CellTemp46 : 7|11@0+ (0.1,-40) [-40|150] "C" VCU
 SG_ P10_CellTemp47 : 12|11@0+ (0.1,-40) [-40|150] "C" VCU
 SG_ P10_CellTemp48 : 17|11@0+ (0.1,-40) [-40|150] "C" VCU
 SG_ P10_CellTemp49 : 38|11@0+ (0.1,-40) [-40|150] "C" VCU
 SG_ P10_CellTemp50 : 43|11@0+ (0.1,-40) [-40|150] "C" VCU

BO_ 2559180970 BatP10_BMS_CellTempM10: 8 BMS
 SG_ P10_CellTemp51 : 7|11@0+ (0.1,-40) [-40|150] "C" VCU
 SG_ P10_CellTemp52 : 12|11@0+ (0.1,-40) [-40|150] "C" VCU
 SG_ P10_CellTemp53 : 17|11@0+ (0.1,-40) [-40|150] "C" VCU
 SG_ P10_CellTemp54 : 38|11@0+ (0.1,-40) [-40|150] "C" VCU
 SG_ P10_CellTemp55 : 43|11@0+ (0.1,-40) [-40|150] "C" VCU

BO_ 2559246506 BatP10_BMS_CellTempM11: 8 BMS
 SG_ P10_CellTemp56 : 7|11@0+ (0.1,-40) [-40|150] "C" VCU
 SG_ P10_CellTemp57 : 12|11@0+ (0.1,-40) [-40|150] "C" VCU
 SG_ P10_CellTemp58 : 17|11@0+ (0.1,-40) [-40|150] "C" VCU
 SG_ P10_CellTemp59 : 38|11@0+ (0.1,-40) [-40|150] "C" VCU
 SG_ P10_CellTemp60 : 43|11@0+ (0.1,-40) [-40|150] "C" VCU

BO_ 2559312042 BatP10_BMS_CellTempM12: 8 BMS
 SG_ P10_CellTemp61 : 7|11@0+ (0.1,-40) [-40|150] "C" VCU
 SG_ P10_CellTemp62 : 12|11@0+ (0.1,-40) [-40|150] "C" VCU
 SG_ P10_CellTemp63 : 17|11@0+ (0.1,-40) [-40|150] "C" VCU
 SG_ P10_CellTemp64 : 38|11@0+ (0.1,-40) [-40|150] "C" VCU
 SG_ P10_CellTemp65 : 43|11@0+ (0.1,-40) [-40|150] "C" VCU

BO_ 2559377578 BatP10_BMS_CellTempM13: 8 BMS
 SG_ P10_CellTemp66 : 7|11@0+ (0.1,-40) [-40|150] "C" VCU
 SG_ P10_CellTemp67 : 12|11@0+ (0.1,-40) [-40|150] "C" VCU
 SG_ P10_CellTemp68 : 17|11@0+ (0.1,-40) [-40|150] "C" VCU
 SG_ P10_CellTemp69 : 38|11@0+ (0.1,-40) [-40|150] "C" VCU
 SG_ P10_CellTemp70 : 43|11@0+ (0.1,-40) [-40|150] "C" VCU

BO_ 2559443114 BatP10_BMS_CellTempM14: 8 BMS
 SG_ P10_CellTemp71 : 7|11@0+ (0.1,-40) [-40|150] "C" VCU
 SG_ P10_CellTemp72 : 12|11@0+ (0.1,-40) [-40|150] "C" VCU
 SG_ P10_CellTemp73 : 17|11@0+ (0.1,-40) [-40|150] "C" VCU
 SG_ P10_CellTemp74 : 38|11@0+ (0.1,-40) [-40|150] "C" VCU
 SG_ P10_CellTemp75 : 43|11@0+ (0.1,-40) [-40|150] "C" VCU

BO_ 2559508650 BatP10_BMS_CellTempM15: 8 BMS
 SG_ P10_CellTemp76 : 7|11@0+ (0.1,-40) [-40|150] "C" VCU
 SG_ P10_CellTemp77 : 12|11@0+ (0.1,-40) [-40|150] "C" VCU
 SG_ P10_CellTemp78 : 17|11@0+ (0.1,-40) [-40|150] "C" VCU
 SG_ P10_CellTemp79 : 38|11@0+ (0.1,-40) [-40|150] "C" VCU
 SG_ P10_CellTemp80 : 43|11@0+ (0.1,-40) [-40|150] "C" VCU

BO_ 2559574186 BatP10_BMS_CellTempM16: 8 BMS
 SG_ P10_CellTemp81 : 7|11@0+ (0.1,-40) [-40|150] "C" VCU
 SG_ P10_CellTemp82 : 12|11@0+ (0.1,-40) [-40|150] "C" VCU
 SG_ P10_CellTemp83 : 17|11@0+ (0.1,-40) [-40|150] "C" VCU
 SG_ P10_CellTemp84 : 38|11@0+ (0.1,-40) [-40|150] "C" VCU
 SG_ P10_CellTemp85 : 43|11@0+ (0.1,-40) [-40|150] "C" VCU

BO_ 2559639722 BatP10_BMS_CellTempM17: 8 BMS
 SG_ P10_CellTemp86 : 7|11@0+ (0.1,-40) [-40|150] "C" VCU
 SG_ P10_CellTemp87 : 12|11@0+ (0.1,-40) [-40|150] "C" VCU
 SG_ P10_CellTemp88 : 17|11@0+ (0.1,-40) [-40|150] "C" VCU
 SG_ P10_CellTemp89 : 38|11@0+ (0.1,-40) [-40|150] "C" VCU
 SG_ P10_CellTemp90 : 43|11@0+ (0.1,-40) [-40|150] "C" VCU

BO_ 2559705258 BatP10_BMS_CellTempM18: 8 BMS
 SG_ P10_CellTemp91 : 7|11@0+ (0.1,-40) [-40|150] "C" VCU
 SG_ P10_CellTemp92 : 12|11@0+ (0.1,-40) [-40|150] "C" VCU
 SG_ P10_CellTemp93 : 17|11@0+ (0.1,-40) [-40|150] "C" VCU
 SG_ P10_CellTemp94 : 38|11@0+ (0.1,-40) [-40|150] "C" VCU
 SG_ P10_CellTemp95 : 43|11@0+ (0.1,-40) [-40|150] "C" VCU

BO_ 2559770794 BatP10_BMS_CellTempM19: 8 BMS
 SG_ P10_CellTemp96 : 7|11@0+ (0.1,-40) [-40|150] "C" VCU
 SG_ P10_CellTemp97 : 12|11@0+ (0.1,-40) [-40|150] "C" VCU
 SG_ P10_CellTemp98 : 17|11@0+ (0.1,-40) [-40|150] "C" VCU
 SG_ P10_CellTemp99 : 38|11@0+ (0.1,-40) [-40|150] "C" VCU
 SG_ P10_CellTemp100 : 43|11@0+ (0.1,-40) [-40|150] "C" VCU

BO_ 2559836330 BatP10_BMS_CellTempM20: 8 BMS
 SG_ P10_CellTemp101 : 7|11@0+ (0.1,-40) [-40|150] "C" VCU
 SG_ P10_CellTemp102 : 12|11@0+ (0.1,-40) [-40|150] "C" VCU
 SG_ P10_CellTemp103 : 17|11@0+ (0.1,-40) [-40|150] "C" VCU
 SG_ P10_CellTemp104 : 38|11@0+ (0.1,-40) [-40|150] "C" VCU
 SG_ P10_CellTemp105 : 43|11@0+ (0.1,-40) [-40|150] "C" VCU

BO_ 2559901866 BatP10_BMS_CellTempM21: 8 BMS
 SG_ P10_CellTemp106 : 7|11@0+ (0.1,-40) [-40|150] "C" VCU
 SG_ P10_CellTemp107 : 12|11@0+ (0.1,-40) [-40|150] "C" VCU
 SG_ P10_CellTemp108 : 17|11@0+ (0.1,-40) [-40|150] "C" VCU
 SG_ P10_CellTemp109 : 38|11@0+ (0.1,-40) [-40|150] "C" VCU
 SG_ P10_CellTemp110 : 43|11@0+ (0.1,-40) [-40|150] "C" VCU

BO_ 2559967402 BatP10_BMS_CellTempM22: 8 BMS
 SG_ P10_CellTemp111 : 7|11@0+ (0.1,-40) [-40|150] "C" VCU
 SG_ P10_CellTemp112 : 12|11@0+ (0.1,-40) [-40|150] "C" VCU
 SG_ P10_CellTemp113 : 17|11@0+ (0.1,-40) [-40|150] "C" VCU
 SG_ P10_CellTemp114 : 38|11@0+ (0.1,-40) [-40|150] "C" VCU
 SG_ P10_CellTemp115 : 43|11@0+ (0.1,-40) [-40|150] "C" VCU

BO_ 2560032938 BatP10_BMS_CellTempM23: 8 BMS
 SG_ P10_CellTemp116 : 7|11@0+ (0.1,-40) [-40|150] "C" VCU
 SG_ P10_CellTemp117 : 12|11@0+ (0.1,-40) [-40|150] "C" VCU
 SG_ P10_CellTemp118 : 17|11@0+ (0.1,-40) [-40|150] "C" VCU
 SG_ P10_CellTemp119 : 38|11@0+ (0.1,-40) [-40|150] "C" VCU
 SG_ P10_CellTemp120 : 43|11@0+ (0.1,-40) [-40|150] "C" VCU

BO_ 2560098474 BatP10_BMS_CellTempM24: 8 BMS
 SG_ P10_CellTemp121 : 7|11@0+ (0.1,-40) [-40|150] "C" VCU
 SG_ P10_CellTemp122 : 12|11@0+ (0.1,-40) [-40|150] "C" VCU
 SG_ P10_CellTemp123 : 17|11@0+ (0.1,-40) [-40|150] "C" VCU
 SG_ P10_CellTemp124 : 38|11@0+ (0.1,-40) [-40|150] "C" VCU
 SG_ P10_CellTemp125 : 43|11@0+ (0.1,-40) [-40|150] "C" VCU

BO_ 2560164010 BatP10_BMS_CellTempM25: 8 BMS
 SG_ P10_CellTemp126 : 7|11@0+ (0.1,-40) [-40|150] "C" VCU
 SG_ P10_CellTemp127 : 12|11@0+ (0.1,-40) [-40|150] "C" VCU
 SG_ P10_CellTemp128 : 17|11@0+ (0.1,-40) [-40|150] "C" VCU
 SG_ P10_CellTemp129 : 38|11@0+ (0.1,-40) [-40|150] "C" VCU
 SG_ P10_CellTemp130 : 43|11@0+ (0.1,-40) [-40|150] "C" VCU

BO_ 2560229546 BatP10_BMS_CellTempM26: 8 BMS
 SG_ P10_CellTemp131 : 7|11@0+ (0.1,-40) [-40|150] "C" VCU
 SG_ P10_CellTemp132 : 12|11@0+ (0.1,-40) [-40|150] "C" VCU
 SG_ P10_CellTemp133 : 17|11@0+ (0.1,-40) [-40|150] "C" VCU
 SG_ P10_CellTemp134 : 38|11@0+ (0.1,-40) [-40|150] "C" VCU
 SG_ P10_CellTemp135 : 43|11@0+ (0.1,-40) [-40|150] "C" VCU

BO_ 2560295082 BatP10_BMS_CellTempM27: 8 BMS
 SG_ P10_CellTemp136 : 7|11@0+ (0.1,-40) [-40|150] "C" VCU
 SG_ P10_CellTemp137 : 12|11@0+ (0.1,-40) [-40|150] "C" VCU
 SG_ P10_CellTemp138 : 17|11@0+ (0.1,-40) [-40|150] "C" VCU
 SG_ P10_CellTemp139 : 38|11@0+ (0.1,-40) [-40|150] "C" VCU
 SG_ P10_CellTemp140 : 43|11@0+ (0.1,-40) [-40|150] "C" VCU

BO_ 2560360618 BatP10_BMS_CellTempM28: 8 BMS
 SG_ P10_CellTemp141 : 7|11@0+ (0.1,-40) [-40|150] "C" VCU
 SG_ P10_CellTemp142 : 12|11@0+ (0.1,-40) [-40|150] "C" VCU
 SG_ P10_CellTemp143 : 17|11@0+ (0.1,-40) [-40|150] "C" VCU
 SG_ P10_CellTemp144 : 38|11@0+ (0.1,-40) [-40|150] "C" VCU
 SG_ P10_CellTemp145 : 43|11@0+ (0.1,-40) [-40|150] "C" VCU

BO_ 2560426154 BatP10_BMS_CellTempM29: 8 BMS
 SG_ P10_CellTemp146 : 7|11@0+ (0.1,-40) [-40|150] "C" VCU
 SG_ P10_CellTemp147 : 12|11@0+ (0.1,-40) [-40|150] "C" VCU
 SG_ P10_CellTemp148 : 17|11@0+ (0.1,-40) [-40|150] "C" VCU
 SG_ P10_CellTemp149 : 38|11@0+ (0.1,-40) [-40|150] "C" VCU
 SG_ P10_CellTemp150 : 43|11@0+ (0.1,-40) [-40|150] "C" VCU

BO_ 2560491690 BatP10_BMS_CellTempM30: 8 BMS
 SG_ P10_CellTemp151 : 7|11@0+ (0.1,-40) [-40|150] "C" VCU
 SG_ P10_CellTemp152 : 12|11@0+ (0.1,-40) [-40|150] "C" VCU
 SG_ P10_CellTemp153 : 17|11@0+ (0.1,-40) [-40|150] "C" VCU
 SG_ P10_CellTemp154 : 38|11@0+ (0.1,-40) [-40|150] "C" VCU
 SG_ P10_CellTemp155 : 43|11@0+ (0.1,-40) [-40|150] "C" VCU

BO_ 2560557226 BatP10_BMS_CellTempM31: 8 BMS
 SG_ P10_CellTemp156 : 7|11@0+ (0.1,-40) [-40|150] "C" VCU
 SG_ P10_CellTemp157 : 12|11@0+ (0.1,-40) [-40|150] "C" VCU
 SG_ P10_CellTemp158 : 17|11@0+ (0.1,-40) [-40|150] "C" VCU
 SG_ P10_CellTemp159 : 38|11@0+ (0.1,-40) [-40|150] "C" VCU
 SG_ P10_CellTemp160 : 43|11@0+ (0.1,-40) [-40|150] "C" VCU

BO_ 2560622762 BatP10_BMS_CellTempM32: 8 BMS
 SG_ P10_CellTemp161 : 7|11@0+ (0.1,-40) [-40|150] "C" VCU
 SG_ P10_CellTemp162 : 12|11@0+ (0.1,-40) [-40|150] "C" VCU
 SG_ P10_CellTemp163 : 17|11@0+ (0.1,-40) [-40|150] "C" VCU
 SG_ P10_CellTemp164 : 38|11@0+ (0.1,-40) [-40|150] "C" VCU
 SG_ P10_CellTemp165 : 43|11@0+ (0.1,-40) [-40|150] "C" VCU

BO_ 2560688298 BatP10_BMS_CellTempM33: 8 BMS
 SG_ P10_CellTemp166 : 7|11@0+ (0.1,-40) [-40|150] "C" VCU
 SG_ P10_CellTemp167 : 12|11@0+ (0.1,-40) [-40|150] "C" VCU
 SG_ P10_CellTemp168 : 17|11@0+ (0.1,-40) [-40|150] "C" VCU
 SG_ P10_CellTemp169 : 38|11@0+ (0.1,-40) [-40|150] "C" VCU
 SG_ P10_CellTemp170 : 43|11@0+ (0.1,-40) [-40|150] "C" VCU

BO_ 2560753834 BatP10_BMS_CellTempM34: 8 BMS
 SG_ P10_CellTemp171 : 7|11@0+ (0.1,-40) [-40|150] "C" VCU
 SG_ P10_CellTemp172 : 12|11@0+ (0.1,-40) [-40|150] "C" VCU
 SG_ P10_CellTemp173 : 17|11@0+ (0.1,-40) [-40|150] "C" VCU
 SG_ P10_CellTemp174 : 38|11@0+ (0.1,-40) [-40|150] "C" VCU
 SG_ P10_CellTemp175 : 43|11@0+ (0.1,-40) [-40|150] "C" VCU

BO_ 2560819370 BatP10_BMS_CellTempM35: 8 BMS
 SG_ P10_CellTemp176 : 7|11@0+ (0.1,-40) [-40|150] "C" VCU
 SG_ P10_CellTemp177 : 12|11@0+ (0.1,-40) [-40|150] "C" VCU
 SG_ P10_CellTemp178 : 17|11@0+ (0.1,-40) [-40|150] "C" VCU
 SG_ P10_CellTemp179 : 38|11@0+ (0.1,-40) [-40|150] "C" VCU
 SG_ P10_CellTemp180 : 43|11@0+ (0.1,-40) [-40|150] "C" VCU

BO_ 2560884906 BatP10_BMS_CellTempM36: 8 BMS
 SG_ P10_CellTemp181 : 7|11@0+ (0.1,-40) [-40|150] "C" VCU
 SG_ P10_CellTemp182 : 12|11@0+ (0.1,-40) [-40|150] "C" VCU
 SG_ P10_CellTemp183 : 17|11@0+ (0.1,-40) [-40|150] "C" VCU
 SG_ P10_CellTemp184 : 38|11@0+ (0.1,-40) [-40|150] "C" VCU
 SG_ P10_CellTemp185 : 43|11@0+ (0.1,-40) [-40|150] "C" VCU

BO_ 2560950442 BatP10_BMS_CellTempM37: 8 BMS
 SG_ P10_CellTemp186 : 7|11@0+ (0.1,-40) [-40|150] "C" VCU
 SG_ P10_CellTemp187 : 12|11@0+ (0.1,-40) [-40|150] "C" VCU
 SG_ P10_CellTemp188 : 17|11@0+ (0.1,-40) [-40|150] "C" VCU
 SG_ P10_CellTemp189 : 38|11@0+ (0.1,-40) [-40|150] "C" VCU
 SG_ P10_CellTemp190 : 43|11@0+ (0.1,-40) [-40|150] "C" VCU

BO_ 2561015978 BatP10_BMS_CellTempM38: 8 BMS
 SG_ P10_CellTemp191 : 7|11@0+ (0.1,-40) [-40|150] "C" VCU
 SG_ P10_CellTemp192 : 12|11@0+ (0.1,-40) [-40|150] "C" VCU
 SG_ P10_DatLen16DbgInfo1 : 7|16@0+ (1,0) [0|65535] "" VCU
 SG_ P10_DatLen16DbgInfo2 : 23|16@0+ (1,0) [0|65535] "" VCU
 SG_ P10_DatLen16DbgInfo3 : 39|16@0+ (1,0) [0|65535] "" VCU
 SG_ P10_DatLen16DbgInfo4 : 55|16@0+ (1,0) [0|65535] "" VCU

CM_ SG_ 2550595737 P9_ChrgrCplrStat "电池包9的充电枪连接状态";
CM_ SG_ 2550595737 P9_HVBattChrgSysStatus "电池包9的充电系统状态";
CM_ SG_ 2550595737 P9_DCChrgCrntCmd "电池包9的直流充电请求电流";
CM_ SG_ 2550595737 P9_CC2Vlt "电池包9的CC2电压值";
CM_ SG_ 2550595737 P9_DCRcptPosTemp "电池包9的快充充电插座正极温度";
CM_ SG_ 2550595737 P9_DCRcptNegTemp "电池包9的快充充电插座负极温度";
CM_ SG_ 2550595737 P9_Tm2FullChrg "电池包9满充剩余时间";
CM_ SG_ 2550661273 P9_Inlet1ClntTemp "进水口1冷却液温度";
CM_ SG_ 2550661273 P9_Inlet2ClntTemp "进水口2冷却液温度";
CM_ SG_ 2550661273 P9_Outlet1ClntTemp "出水口1冷却液温度";
CM_ SG_ 2550661273 P9_Outlet2ClntTemp "出水口2冷却液温度";
CM_ SG_ 2550661273 P9_TrgtClntTemp "冷却水目标温度";
CM_ SG_ 2550661273 P9_TrgtClntFlowRate "冷却水目标流量";
CM_ SG_ 2550726809 P9_MaxCellVlt "电池包9的最大单体电压";
CM_ SG_ 2550726809 P9_MaxCellVltNum "电池包9的最大单体电压编号";
CM_ SG_ 2550726809 P9_MinCellVlt "电池包9的最小单体电压";
CM_ SG_ 2550726809 P9_MinCellVltNum "电池包9的最小单体电压编号";
CM_ SG_ 2550726809 P9_AvgCellVlt "电池包9的平均单体电压";
CM_ SG_ 2550792345 P9_MaxCellTemp "电池包9的最高单体温度";
CM_ SG_ 2550792345 P9_MaxCellTempNum "电池包9的最高单体温度编号";
CM_ SG_ 2550792345 P9_MinCellTemp "电池包9的最低单体温度";
CM_ SG_ 2550792345 P9_MinCellTempNum "电池包9的最低单体温度编号";
CM_ SG_ 2550792345 P9_AvgCellTemp "电池包9的单体平均温度";
CM_ SG_ 2550857881 P9_PackTotFltNum "电池包9的电池故障总数";
CM_ SG_ 2550857881 P9_CellOverVoltage "电池包9的单体过压";
CM_ SG_ 2550857881 P9_CellUnderVoltage "电池包9的单体欠压";
CM_ SG_ 2550857881 P9_CellVoltageDiffHi "电池包9的单体压差过大";
CM_ SG_ 2550857881 P9_PackOverVoltage "电池包9的电压过高";
CM_ SG_ 2550857881 P9_PackUnderVoltage "电池包9的电压过低";
CM_ SG_ 2550857881 P9_CellOverTemp "电池包9的单体过温";
CM_ SG_ 2550857881 P9_CellTempLow "电池包9的单体温度过低";
CM_ SG_ 2550857881 P9_CellTempDiffHi "电池包9的单体温度差异过大";
CM_ SG_ 2550857881 P9_PackDschrgCrntHi "电池包9的放电电流过流";
CM_ SG_ 2550857881 P9_PackChrgCrntHi "电池包9的充电电流过流";
CM_ SG_ 2550857881 P9_PackCrnSnsr1OffsetHi "电池包9的电流传感器1零漂过大";
CM_ SG_ 2550857881 P9_HVIsolFlt "电池包9的高压绝缘故障";
CM_ SG_ 2550857881 P9_HVILFlt "电池包9的高压互锁故障";
CM_ SG_ 2550857881 P9_ThrmlRunaway "电池包9的热失控故障";
CM_ SG_ 2550857881 P9_CellVoltInvalid "电池包9的单体电压采样失效";
CM_ SG_ 2550857881 P9_CellTempInvalid "电池包9的电芯温度采样失效";
CM_ SG_ 2550857881 P9_DaisyChainComFlt "电池包9的菊花链通信故障";
CM_ SG_ 2550857881 P9_PackVoltRatFlt "电池包9的总电压与单体电压总和偏差过大";
CM_ SG_ 2550857881 P9_CrntSnsr1Invalid "电池包9的电流传感器1电流采样失效";
CM_ SG_ 2550857881 P9_CrntSnsr1OOR "电池包9的电流传感器1电流超出采样范围";
CM_ SG_ 2550857881 P9_CrntSnsr2Invalid "电池包9的电流传感器2电流采样失效";
CM_ SG_ 2550857881 P9_CrntSnsr2OOR "电池包9的电流传感器2电流超出采样范围";
CM_ SG_ 2550857881 P9_PackCrnSnsr2OffsetHi "电池包9的电流传感器2零漂过大";
CM_ SG_ 2550857881 P9_OutofEnergy "电池包9的电池剩余电量低";
CM_ SG_ 2550857881 P9_IsolDetCircErr "电池包9的绝缘检测电路失效";
CM_ SG_ 2550857881 P9_HVILCircShortToGND "电池包9的高压互锁对地短路";
CM_ SG_ 2550857881 P9_HVILCircShortToPwr "电池包9的高压互锁对电源短路";
CM_ SG_ 2550923417 P9_MainPosCntctrStkClsd "电池包9的主正继电器粘连故障";
CM_ SG_ 2550923417 P9_MainPosCntctrStkOpn "电池包9的主正继电器常开故障";
CM_ SG_ 2550923417 P9_MainNegCntctr1StkClsd "电池包9的主负继电器1粘连故障";
CM_ SG_ 2550923417 P9_MainNegCntctr1StkOpn "电池包9的主负继电器1常开故障";
CM_ SG_ 2550923417 P9_MainNegCntctr2StkClsd "电池包9的主负继电器2粘连故障";
CM_ SG_ 2550923417 P9_MainNegCntctr2StkOpn "电池包9的主负继电器2常开故障";
CM_ SG_ 2550923417 P9_PrechargTmOut "电池包9的预充超时故障";
CM_ SG_ 2550923417 P9_PrechrgCrntHi "电池包9的预充过流故障";
CM_ SG_ 2550923417 P9_ChrgCplrPosTempHi "电池包9的充电正极接口温度过高故障";
CM_ SG_ 2550923417 P9_ChrgCplrNegTempHi "电池包9的充电负极接口温度过高故障";
CM_ SG_ 2550923417 P9_BMSPwrSuplVlt1Hi "电池包9的BMS供电电压1过高";
CM_ SG_ 2550923417 P9_BMSPwrSuplVlt1Lo "电池包9的BMS供电电压1过低";
CM_ SG_ 2550923417 P9_BMSPwrSuplVlt2Hi "电池包9的BMS供电电压2过高";
CM_ SG_ 2550923417 P9_BMSPwrSuplVlt2Lo "电池包9的BMS供电电压2过低";
CM_ SG_ 2550923417 P9_CntctrCirPwrSuplVltLo "电池包9的继电器驱动供电电压过低";
CM_ SG_ 2550923417 P9_CntctrCirPwrSuplVltHi "电池包9的继电器驱动供电电压过高";
CM_ SG_ 2550923417 P9_CAN1BusOff "电池包9的CAN1通信Bus off";
CM_ SG_ 2550923417 P9_CAN1BusTmOut "电池包9的CAN1报文超时（Timeout）";
CM_ SG_ 2550923417 P9_CAN2BusOff "电池包9的CAN2通信Bus off";
CM_ SG_ 2550923417 P9_CAN2BusTmOut "电池包9的CAN2报文超时（Timeout）";
CM_ SG_ 2550923417 P9_CellBalCircTempHi "电池包9的均衡电路过温";
CM_ SG_ 2550923417 P9_ClntInTempHi "电池包9的入水口温度过高";
CM_ SG_ 2550923417 P9_ClntOutTempHi "电池包9的出水口温度过高";
CM_ SG_ 2550923417 P9_CellExtrmUdrVolt "电池包9的单体极限欠压";
CM_ SG_ 2550923417 P9_CellExtrmOvrVolt "电池包9的单体极限过压";
CM_ SG_ 2550923417 P9_Branch1DischrgCrntHi  "电池包9的支路1放电过流";
CM_ SG_ 2550923417 P9_Branch2DischrgCrntHi  "电池包9的支路2放电过流";
CM_ SG_ 2550923417 P9_Branch1ChrgCrntHi  "电池包9的支路1充电过流";
CM_ SG_ 2550923417 P9_Branch2ChrgCrntHi  "电池包9的支路2充电过流";
CM_ SG_ 2550923417 P9_InitFailed "电池包9的BMS初始化失败";
CM_ SG_ 2550923417 P9_PackErrCode "电池包9的故障代码";
CM_ SG_ 2550988953 P9_PackTotCellNum "电池包9的单体电池总数";
CM_ SG_ 2550988953 P9_PackTotCellTempSnsrNum "电池包9的单体温度传感器总数";
CM_ SG_ 2552299673 P9_BMSASWMajVerNum "电池包9的BMS应用层软件主版本号";
CM_ SG_ 2552299673 P9_BMSASWMinVerNum "电池包9的BMS应用层软件子版本号";
CM_ SG_ 2552299673 P9_BMSASWPatchVerNum "电池包9的BMS应用层软件修订版本号";
CM_ SG_ 2552299673 P9_BMSBSWMajVerNum "电池包9的BMS底层软件主版本号";
CM_ SG_ 2552299673 P9_BMSBSWMinVerNum "电池包9的BMS底层软件子版本号";
CM_ SG_ 2552299673 P9_BMSBSWPatchVerNum "电池包9的BMS底层软件修订版本号";
CM_ SG_ 2554396825 P9_CellVoltage1 "电池包9的单体电压1";
CM_ SG_ 2554396825 P9_CellVoltage2 "电池包9的单体电压2";
CM_ SG_ 2554396825 P9_CellVoltage3 "电池包9的单体电压3";
CM_ SG_ 2554396825 P9_CellVoltage4 "电池包9的单体电压4";
CM_ SG_ 2554396825 P9_BalSwCell1 "电池包9的电芯1均衡状态";
CM_ SG_ 2554396825 P9_BalSwCell2 "电池包9的电芯2均衡状态";
CM_ SG_ 2554396825 P9_BalSwCell3 "电池包9的电芯3均衡状态";
CM_ SG_ 2554396825 P9_BalSwCell4 "电池包9的电芯4均衡状态";
CM_ SG_ 2554462361 P9_CellVoltage5 "电池包9的单体电压5";
CM_ SG_ 2554462361 P9_CellVoltage6 "电池包9的单体电压6";
CM_ SG_ 2554462361 P9_CellVoltage7 "电池包9的单体电压7";
CM_ SG_ 2554462361 P9_CellVoltage8 "电池包9的单体电压8";
CM_ SG_ 2554462361 P9_BalSwCell5 "电池包9的电芯5均衡状态";
CM_ SG_ 2554462361 P9_BalSwCell6 "电池包9的电芯6均衡状态";
CM_ SG_ 2554462361 P9_BalSwCell7 "电池包9的电芯7均衡状态";
CM_ SG_ 2554462361 P9_BalSwCell8 "电池包9的电芯8均衡状态";
CM_ SG_ 2554527897 P9_CellVoltage9 "电池包9的单体电压9";
CM_ SG_ 2554527897 P9_CellVoltage10 "电池包9的单体电压10";
CM_ SG_ 2554527897 P9_CellVoltage11 "电池包9的单体电压11";
CM_ SG_ 2554527897 P9_CellVoltage12 "电池包9的单体电压12";
CM_ SG_ 2554527897 P9_BalSwCell9 "电池包9的电芯9均衡状态";
CM_ SG_ 2554527897 P9_BalSwCell10 "电池包9的电芯10均衡状态";
CM_ SG_ 2554527897 P9_BalSwCell11 "电池包9的电芯11均衡状态";
CM_ SG_ 2554527897 P9_BalSwCell12 "电池包9的电芯12均衡状态";
CM_ SG_ 2554593433 P9_CellVoltage13 "电池包9的单体电压13";
CM_ SG_ 2554593433 P9_CellVoltage14 "电池包9的单体电压14";
CM_ SG_ 2554593433 P9_CellVoltage15 "电池包9的单体电压15";
CM_ SG_ 2554593433 P9_CellVoltage16 "电池包9的单体电压16";
CM_ SG_ 2554593433 P9_BalSwCell13 "电池包9的电芯13均衡状态";
CM_ SG_ 2554593433 P9_BalSwCell14 "电池包9的电芯14均衡状态";
CM_ SG_ 2554593433 P9_BalSwCell15 "电池包9的电芯15均衡状态";
CM_ SG_ 2554593433 P9_BalSwCell16 "电池包9的电芯16均衡状态";
CM_ SG_ 2554658969 P9_CellVoltage17 "电池包9的单体电压17";
CM_ SG_ 2554658969 P9_CellVoltage18 "电池包9的单体电压18";
CM_ SG_ 2554658969 P9_CellVoltage19 "电池包9的单体电压19";
CM_ SG_ 2554658969 P9_CellVoltage20 "电池包9的单体电压20";
CM_ SG_ 2554658969 P9_BalSwCell17 "电池包9的电芯17均衡状态";
CM_ SG_ 2554658969 P9_BalSwCell18 "电池包9的电芯18均衡状态";
CM_ SG_ 2554658969 P9_BalSwCell19 "电池包9的电芯19均衡状态";
CM_ SG_ 2554658969 P9_BalSwCell20 "电池包9的电芯20均衡状态";
CM_ SG_ 2554724505 P9_CellVoltage21 "电池包9的单体电压21";
CM_ SG_ 2554724505 P9_CellVoltage22 "电池包9的单体电压22";
CM_ SG_ 2554724505 P9_CellVoltage23 "电池包9的单体电压23";
CM_ SG_ 2554724505 P9_CellVoltage24 "电池包9的单体电压24";
CM_ SG_ 2554724505 P9_BalSwCell21 "电池包9的电芯21均衡状态";
CM_ SG_ 2554724505 P9_BalSwCell22 "电池包9的电芯22均衡状态";
CM_ SG_ 2554724505 P9_BalSwCell23 "电池包9的电芯23均衡状态";
CM_ SG_ 2554724505 P9_BalSwCell24 "电池包9的电芯24均衡状态";
CM_ SG_ 2554790041 P9_CellVoltage25 "电池包9的单体电压25";
CM_ SG_ 2554790041 P9_CellVoltage26 "电池包9的单体电压26";
CM_ SG_ 2554790041 P9_CellVoltage27 "电池包9的单体电压27";
CM_ SG_ 2554790041 P9_CellVoltage28 "电池包9的单体电压28";
CM_ SG_ 2554790041 P9_BalSwCell25 "电池包9的电芯25均衡状态";
CM_ SG_ 2554790041 P9_BalSwCell26 "电池包9的电芯26均衡状态";
CM_ SG_ 2554790041 P9_BalSwCell27 "电池包9的电芯27均衡状态";
CM_ SG_ 2554790041 P9_BalSwCell28 "电池包9的电芯28均衡状态";
CM_ SG_ 2554855577 P9_CellVoltage29 "电池包9的单体电压29";
CM_ SG_ 2554855577 P9_CellVoltage30 "电池包9的单体电压30";
CM_ SG_ 2554855577 P9_CellVoltage31 "电池包9的单体电压31";
CM_ SG_ 2554855577 P9_CellVoltage32 "电池包9的单体电压32";
CM_ SG_ 2554855577 P9_BalSwCell29 "电池包9的电芯29均衡状态";
CM_ SG_ 2554855577 P9_BalSwCell30 "电池包9的电芯30均衡状态";
CM_ SG_ 2554855577 P9_BalSwCell31 "电池包9的电芯31均衡状态";
CM_ SG_ 2554855577 P9_BalSwCell32 "电池包9的电芯32均衡状态";
CM_ SG_ 2554921113 P9_CellVoltage33 "电池包9的单体电压33";
CM_ SG_ 2554921113 P9_CellVoltage34 "电池包9的单体电压34";
CM_ SG_ 2554921113 P9_CellVoltage35 "电池包9的单体电压35";
CM_ SG_ 2554921113 P9_CellVoltage36 "电池包9的单体电压36";
CM_ SG_ 2554921113 P9_BalSwCell33 "电池包9的电芯33均衡状态";
CM_ SG_ 2554921113 P9_BalSwCell34 "电池包9的电芯34均衡状态";
CM_ SG_ 2554921113 P9_BalSwCell35 "电池包9的电芯35均衡状态";
CM_ SG_ 2554921113 P9_BalSwCell36 "电池包9的电芯36均衡状态";
CM_ SG_ 2554986649 P9_CellVoltage37 "电池包9的单体电压37";
CM_ SG_ 2554986649 P9_CellVoltage38 "电池包9的单体电压38";
CM_ SG_ 2554986649 P9_CellVoltage39 "电池包9的单体电压39";
CM_ SG_ 2554986649 P9_CellVoltage40 "电池包9的单体电压40";
CM_ SG_ 2554986649 P9_BalSwCell37 "电池包9的电芯37均衡状态";
CM_ SG_ 2554986649 P9_BalSwCell38 "电池包9的电芯38均衡状态";
CM_ SG_ 2554986649 P9_BalSwCell39 "电池包9的电芯39均衡状态";
CM_ SG_ 2554986649 P9_BalSwCell40 "电池包9的电芯40均衡状态";
CM_ SG_ 2555052185 P9_CellVoltage41 "电池包9的单体电压41";
CM_ SG_ 2555052185 P9_CellVoltage42 "电池包9的单体电压42";
CM_ SG_ 2555052185 P9_CellVoltage43 "电池包9的单体电压43";
CM_ SG_ 2555052185 P9_CellVoltage44 "电池包9的单体电压44";
CM_ SG_ 2555052185 P9_BalSwCell41 "电池包9的电芯41均衡状态";
CM_ SG_ 2555052185 P9_BalSwCell42 "电池包9的电芯42均衡状态";
CM_ SG_ 2555052185 P9_BalSwCell43 "电池包9的电芯43均衡状态";
CM_ SG_ 2555052185 P9_BalSwCell44 "电池包9的电芯44均衡状态";
CM_ SG_ 2555117721 P9_CellVoltage45 "电池包9的单体电压45";
CM_ SG_ 2555117721 P9_CellVoltage46 "电池包9的单体电压46";
CM_ SG_ 2555117721 P9_CellVoltage47 "电池包9的单体电压47";
CM_ SG_ 2555117721 P9_CellVoltage48 "电池包9的单体电压48";
CM_ SG_ 2555117721 P9_BalSwCell45 "电池包9的电芯45均衡状态";
CM_ SG_ 2555117721 P9_BalSwCell46 "电池包9的电芯46均衡状态";
CM_ SG_ 2555117721 P9_BalSwCell47 "电池包9的电芯47均衡状态";
CM_ SG_ 2555117721 P9_BalSwCell48 "电池包9的电芯48均衡状态";
CM_ SG_ 2555183257 P9_CellVoltage49 "电池包9的单体电压49";
CM_ SG_ 2555183257 P9_CellVoltage50 "电池包9的单体电压50";
CM_ SG_ 2555183257 P9_CellVoltage51 "电池包9的单体电压51";
CM_ SG_ 2555183257 P9_CellVoltage52 "电池包9的单体电压52";
CM_ SG_ 2555183257 P9_BalSwCell49 "电池包9的电芯49均衡状态";
CM_ SG_ 2555183257 P9_BalSwCell50 "电池包9的电芯50均衡状态";
CM_ SG_ 2555183257 P9_BalSwCell51 "电池包9的电芯51均衡状态";
CM_ SG_ 2555183257 P9_BalSwCell52 "电池包9的电芯52均衡状态";
CM_ SG_ 2555248793 P9_CellVoltage53 "电池包9的单体电压53";
CM_ SG_ 2555248793 P9_CellVoltage54 "电池包9的单体电压54";
CM_ SG_ 2555248793 P9_CellVoltage55 "电池包9的单体电压55";
CM_ SG_ 2555248793 P9_CellVoltage56 "电池包9的单体电压56";
CM_ SG_ 2555248793 P9_BalSwCell53 "电池包9的电芯53均衡状态";
CM_ SG_ 2555248793 P9_BalSwCell54 "电池包9的电芯54均衡状态";
CM_ SG_ 2555248793 P9_BalSwCell55 "电池包9的电芯55均衡状态";
CM_ SG_ 2555248793 P9_BalSwCell56 "电池包9的电芯56均衡状态";
CM_ SG_ 2555314329 P9_CellVoltage57 "电池包9的单体电压57";
CM_ SG_ 2555314329 P9_CellVoltage58 "电池包9的单体电压58";
CM_ SG_ 2555314329 P9_CellVoltage59 "电池包9的单体电压59";
CM_ SG_ 2555314329 P9_CellVoltage60 "电池包9的单体电压60";
CM_ SG_ 2555314329 P9_BalSwCell57 "电池包9的电芯57均衡状态";
CM_ SG_ 2555314329 P9_BalSwCell58 "电池包9的电芯58均衡状态";
CM_ SG_ 2555314329 P9_BalSwCell59 "电池包9的电芯59均衡状态";
CM_ SG_ 2555314329 P9_BalSwCell60 "电池包9的电芯60均衡状态";
CM_ SG_ 2555379865 P9_CellVoltage61 "电池包9的单体电压61";
CM_ SG_ 2555379865 P9_CellVoltage62 "电池包9的单体电压62";
CM_ SG_ 2555379865 P9_CellVoltage63 "电池包9的单体电压63";
CM_ SG_ 2555379865 P9_CellVoltage64 "电池包9的单体电压64";
CM_ SG_ 2555379865 P9_BalSwCell61 "电池包9的电芯61均衡状态";
CM_ SG_ 2555379865 P9_BalSwCell62 "电池包9的电芯62均衡状态";
CM_ SG_ 2555379865 P9_BalSwCell63 "电池包9的电芯63均衡状态";
CM_ SG_ 2555379865 P9_BalSwCell64 "电池包9的电芯64均衡状态";
CM_ SG_ 2555445401 P9_CellVoltage65 "电池包9的单体电压65";
CM_ SG_ 2555445401 P9_CellVoltage66 "电池包9的单体电压66";
CM_ SG_ 2555445401 P9_CellVoltage67 "电池包9的单体电压67";
CM_ SG_ 2555445401 P9_CellVoltage68 "电池包9的单体电压68";
CM_ SG_ 2555445401 P9_BalSwCell65 "电池包9的电芯65均衡状态";
CM_ SG_ 2555445401 P9_BalSwCell66 "电池包9的电芯66均衡状态";
CM_ SG_ 2555445401 P9_BalSwCell67 "电池包9的电芯67均衡状态";
CM_ SG_ 2555445401 P9_BalSwCell68 "电池包9的电芯68均衡状态";
CM_ SG_ 2555510937 P9_CellVoltage69 "电池包9的单体电压69";
CM_ SG_ 2555510937 P9_CellVoltage70 "电池包9的单体电压70";
CM_ SG_ 2555510937 P9_CellVoltage71 "电池包9的单体电压71";
CM_ SG_ 2555510937 P9_CellVoltage72 "电池包9的单体电压72";
CM_ SG_ 2555510937 P9_BalSwCell69 "电池包9的电芯69均衡状态";
CM_ SG_ 2555510937 P9_BalSwCell70 "电池包9的电芯70均衡状态";
CM_ SG_ 2555510937 P9_BalSwCell71 "电池包9的电芯71均衡状态";
CM_ SG_ 2555510937 P9_BalSwCell72 "电池包9的电芯72均衡状态";
CM_ SG_ 2555576473 P9_CellVoltage73 "电池包9的单体电压73";
CM_ SG_ 2555576473 P9_CellVoltage74 "电池包9的单体电压74";
CM_ SG_ 2555576473 P9_CellVoltage75 "电池包9的单体电压75";
CM_ SG_ 2555576473 P9_CellVoltage76 "电池包9的单体电压76";
CM_ SG_ 2555576473 P9_BalSwCell73 "电池包9的电芯73均衡状态";
CM_ SG_ 2555576473 P9_BalSwCell74 "电池包9的电芯74均衡状态";
CM_ SG_ 2555576473 P9_BalSwCell75 "电池包9的电芯75均衡状态";
CM_ SG_ 2555576473 P9_BalSwCell76 "电池包9的电芯76均衡状态";
CM_ SG_ 2555642009 P9_CellVoltage77 "电池包9的单体电压77";
CM_ SG_ 2555642009 P9_CellVoltage78 "电池包9的单体电压78";
CM_ SG_ 2555642009 P9_CellVoltage79 "电池包9的单体电压79";
CM_ SG_ 2555642009 P9_CellVoltage80 "电池包9的单体电压80";
CM_ SG_ 2555642009 P9_BalSwCell77 "电池包9的电芯77均衡状态";
CM_ SG_ 2555642009 P9_BalSwCell78 "电池包9的电芯78均衡状态";
CM_ SG_ 2555642009 P9_BalSwCell79 "电池包9的电芯79均衡状态";
CM_ SG_ 2555642009 P9_BalSwCell80 "电池包9的电芯80均衡状态";
CM_ SG_ 2555707545 P9_CellVoltage81 "电池包9的单体电压81";
CM_ SG_ 2555707545 P9_CellVoltage82 "电池包9的单体电压82";
CM_ SG_ 2555707545 P9_CellVoltage83 "电池包9的单体电压83";
CM_ SG_ 2555707545 P9_CellVoltage84 "电池包9的单体电压84";
CM_ SG_ 2555707545 P9_BalSwCell81 "电池包9的电芯81均衡状态";
CM_ SG_ 2555707545 P9_BalSwCell82 "电池包9的电芯82均衡状态";
CM_ SG_ 2555707545 P9_BalSwCell83 "电池包9的电芯83均衡状态";
CM_ SG_ 2555707545 P9_BalSwCell84 "电池包9的电芯84均衡状态";
CM_ SG_ 2555773081 P9_CellVoltage85 "电池包9的单体电压85";
CM_ SG_ 2555773081 P9_CellVoltage86 "电池包9的单体电压86";
CM_ SG_ 2555773081 P9_CellVoltage87 "电池包9的单体电压87";
CM_ SG_ 2555773081 P9_CellVoltage88 "电池包9的单体电压88";
CM_ SG_ 2555773081 P9_BalSwCell85 "电池包9的电芯85均衡状态";
CM_ SG_ 2555773081 P9_BalSwCell86 "电池包9的电芯86均衡状态";
CM_ SG_ 2555773081 P9_BalSwCell87 "电池包9的电芯87均衡状态";
CM_ SG_ 2555773081 P9_BalSwCell88 "电池包9的电芯88均衡状态";
CM_ SG_ 2555838617 P9_CellVoltage89 "电池包9的单体电压89";
CM_ SG_ 2555838617 P9_CellVoltage90 "电池包9的单体电压90";
CM_ SG_ 2555838617 P9_CellVoltage91 "电池包9的单体电压91";
CM_ SG_ 2555838617 P9_CellVoltage92 "电池包9的单体电压92";
CM_ SG_ 2555838617 P9_BalSwCell89 "电池包9的电芯89均衡状态";
CM_ SG_ 2555838617 P9_BalSwCell90 "电池包9的电芯90均衡状态";
CM_ SG_ 2555838617 P9_BalSwCell91 "电池包9的电芯91均衡状态";
CM_ SG_ 2555838617 P9_BalSwCell92 "电池包9的电芯92均衡状态";
CM_ SG_ 2555904153 P9_CellVoltage93 "电池包9的单体电压93";
CM_ SG_ 2555904153 P9_CellVoltage94 "电池包9的单体电压94";
CM_ SG_ 2555904153 P9_CellVoltage95 "电池包9的单体电压95";
CM_ SG_ 2555904153 P9_CellVoltage96 "电池包9的单体电压96";
CM_ SG_ 2555904153 P9_BalSwCell93 "电池包9的电芯93均衡状态";
CM_ SG_ 2555904153 P9_BalSwCell94 "电池包9的电芯94均衡状态";
CM_ SG_ 2555904153 P9_BalSwCell95 "电池包9的电芯95均衡状态";
CM_ SG_ 2555904153 P9_BalSwCell96 "电池包9的电芯96均衡状态";
CM_ SG_ 2555969689 P9_CellVoltage97 "电池包9的单体电压97";
CM_ SG_ 2555969689 P9_CellVoltage98 "电池包9的单体电压98";
CM_ SG_ 2555969689 P9_CellVoltage99 "电池包9的单体电压99";
CM_ SG_ 2555969689 P9_CellVoltage100 "电池包9的单体电压100";
CM_ SG_ 2555969689 P9_BalSwCell97 "电池包9的电芯97均衡状态";
CM_ SG_ 2555969689 P9_BalSwCell98 "电池包9的电芯98均衡状态";
CM_ SG_ 2555969689 P9_BalSwCell99 "电池包9的电芯99均衡状态";
CM_ SG_ 2555969689 P9_BalSwCell100 "电池包9的电芯100均衡状态";
CM_ SG_ 2556035225 P9_CellVoltage101 "电池包9的单体电压101";
CM_ SG_ 2556035225 P9_CellVoltage102 "电池包9的单体电压102";
CM_ SG_ 2556035225 P9_CellVoltage103 "电池包9的单体电压103";
CM_ SG_ 2556035225 P9_CellVoltage104 "电池包9的单体电压104";
CM_ SG_ 2556035225 P9_BalSwCell101 "电池包9的电芯101均衡状态";
CM_ SG_ 2556035225 P9_BalSwCell102 "电池包9的电芯102均衡状态";
CM_ SG_ 2556035225 P9_BalSwCell103 "电池包9的电芯103均衡状态";
CM_ SG_ 2556035225 P9_BalSwCell104 "电池包9的电芯104均衡状态";
CM_ SG_ 2556100761 P9_CellVoltage105 "电池包9的单体电压105";
CM_ SG_ 2556100761 P9_CellVoltage106 "电池包9的单体电压106";
CM_ SG_ 2556100761 P9_CellVoltage107 "电池包9的单体电压107";
CM_ SG_ 2556100761 P9_CellVoltage108 "电池包9的单体电压108";
CM_ SG_ 2556100761 P9_BalSwCell105 "电池包9的电芯105均衡状态";
CM_ SG_ 2556100761 P9_BalSwCell106 "电池包9的电芯106均衡状态";
CM_ SG_ 2556100761 P9_BalSwCell107 "电池包9的电芯107均衡状态";
CM_ SG_ 2556100761 P9_BalSwCell108 "电池包9的电芯108均衡状态";
CM_ SG_ 2556166297 P9_CellVoltage109 "电池包9的单体电压109";
CM_ SG_ 2556166297 P9_CellVoltage110 "电池包9的单体电压110";
CM_ SG_ 2556166297 P9_CellVoltage111 "电池包9的单体电压111";
CM_ SG_ 2556166297 P9_CellVoltage112 "电池包9的单体电压112";
CM_ SG_ 2556166297 P9_BalSwCell109 "电池包9的电芯109均衡状态";
CM_ SG_ 2556166297 P9_BalSwCell110 "电池包9的电芯110均衡状态";
CM_ SG_ 2556166297 P9_BalSwCell111 "电池包9的电芯111均衡状态";
CM_ SG_ 2556166297 P9_BalSwCell112 "电池包9的电芯112均衡状态";
CM_ SG_ 2556231833 P9_CellVoltage113 "电池包9的单体电压113";
CM_ SG_ 2556231833 P9_CellVoltage114 "电池包9的单体电压114";
CM_ SG_ 2556231833 P9_CellVoltage115 "电池包9的单体电压115";
CM_ SG_ 2556231833 P9_CellVoltage116 "电池包9的单体电压116";
CM_ SG_ 2556231833 P9_BalSwCell113 "电池包9的电芯113均衡状态";
CM_ SG_ 2556231833 P9_BalSwCell114 "电池包9的电芯114均衡状态";
CM_ SG_ 2556231833 P9_BalSwCell115 "电池包9的电芯115均衡状态";
CM_ SG_ 2556231833 P9_BalSwCell116 "电池包9的电芯116均衡状态";
CM_ SG_ 2556297369 P9_CellVoltage117 "电池包9的单体电压117";
CM_ SG_ 2556297369 P9_CellVoltage118 "电池包9的单体电压118";
CM_ SG_ 2556297369 P9_CellVoltage119 "电池包9的单体电压119";
CM_ SG_ 2556297369 P9_CellVoltage120 "电池包9的单体电压120";
CM_ SG_ 2556297369 P9_BalSwCell117 "电池包9的电芯117均衡状态";
CM_ SG_ 2556297369 P9_BalSwCell118 "电池包9的电芯118均衡状态";
CM_ SG_ 2556297369 P9_BalSwCell119 "电池包9的电芯119均衡状态";
CM_ SG_ 2556297369 P9_BalSwCell120 "电池包9的电芯120均衡状态";
CM_ SG_ 2556362905 P9_CellVoltage121 "电池包9的单体电压121";
CM_ SG_ 2556362905 P9_CellVoltage122 "电池包9的单体电压122";
CM_ SG_ 2556362905 P9_CellVoltage123 "电池包9的单体电压123";
CM_ SG_ 2556362905 P9_CellVoltage124 "电池包9的单体电压124";
CM_ SG_ 2556362905 P9_BalSwCell121 "电池包9的电芯121均衡状态";
CM_ SG_ 2556362905 P9_BalSwCell122 "电池包9的电芯122均衡状态";
CM_ SG_ 2556362905 P9_BalSwCell123 "电池包9的电芯123均衡状态";
CM_ SG_ 2556362905 P9_BalSwCell124 "电池包9的电芯124均衡状态";
CM_ SG_ 2556428441 P9_CellVoltage125 "电池包9的单体电压125";
CM_ SG_ 2556428441 P9_CellVoltage126 "电池包9的单体电压126";
CM_ SG_ 2556428441 P9_CellVoltage127 "电池包9的单体电压127";
CM_ SG_ 2556428441 P9_CellVoltage128 "电池包9的单体电压128";
CM_ SG_ 2556428441 P9_BalSwCell125 "电池包9的电芯125均衡状态";
CM_ SG_ 2556428441 P9_BalSwCell126 "电池包9的电芯126均衡状态";
CM_ SG_ 2556428441 P9_BalSwCell127 "电池包9的电芯127均衡状态";
CM_ SG_ 2556428441 P9_BalSwCell128 "电池包9的电芯128均衡状态";
CM_ SG_ 2556493977 P9_CellVoltage129 "电池包9的单体电压129";
CM_ SG_ 2556493977 P9_CellVoltage130 "电池包9的单体电压130";
CM_ SG_ 2556493977 P9_CellVoltage131 "电池包9的单体电压131";
CM_ SG_ 2556493977 P9_CellVoltage132 "电池包9的单体电压132";
CM_ SG_ 2556493977 P9_BalSwCell129 "电池包9的电芯129均衡状态";
CM_ SG_ 2556493977 P9_BalSwCell130 "电池包9的电芯130均衡状态";
CM_ SG_ 2556493977 P9_BalSwCell131 "电池包9的电芯131均衡状态";
CM_ SG_ 2556493977 P9_BalSwCell132 "电池包9的电芯132均衡状态";
CM_ SG_ 2556559513 P9_CellVoltage133 "电池包9的单体电压133";
CM_ SG_ 2556559513 P9_CellVoltage134 "电池包9的单体电压134";
CM_ SG_ 2556559513 P9_CellVoltage135 "电池包9的单体电压135";
CM_ SG_ 2556559513 P9_CellVoltage136 "电池包9的单体电压136";
CM_ SG_ 2556559513 P9_BalSwCell133 "电池包9的电芯133均衡状态";
CM_ SG_ 2556559513 P9_BalSwCell134 "电池包9的电芯134均衡状态";
CM_ SG_ 2556559513 P9_BalSwCell135 "电池包9的电芯135均衡状态";
CM_ SG_ 2556559513 P9_BalSwCell136 "电池包9的电芯136均衡状态";
CM_ SG_ 2556625049 P9_CellVoltage137 "电池包9的单体电压137";
CM_ SG_ 2556625049 P9_CellVoltage138 "电池包9的单体电压138";
CM_ SG_ 2556625049 P9_CellVoltage139 "电池包9的单体电压139";
CM_ SG_ 2556625049 P9_CellVoltage140 "电池包9的单体电压140";
CM_ SG_ 2556625049 P9_BalSwCell137 "电池包9的电芯137均衡状态";
CM_ SG_ 2556625049 P9_BalSwCell138 "电池包9的电芯138均衡状态";
CM_ SG_ 2556625049 P9_BalSwCell139 "电池包9的电芯139均衡状态";
CM_ SG_ 2556625049 P9_BalSwCell140 "电池包9的电芯140均衡状态";
CM_ SG_ 2556690585 P9_CellVoltage141 "电池包9的单体电压141";
CM_ SG_ 2556690585 P9_CellVoltage142 "电池包9的单体电压142";
CM_ SG_ 2556690585 P9_CellVoltage143 "电池包9的单体电压143";
CM_ SG_ 2556690585 P9_CellVoltage144 "电池包9的单体电压144";
CM_ SG_ 2556690585 P9_BalSwCell141 "电池包9的电芯141均衡状态";
CM_ SG_ 2556690585 P9_BalSwCell142 "电池包9的电芯142均衡状态";
CM_ SG_ 2556690585 P9_BalSwCell143 "电池包9的电芯143均衡状态";
CM_ SG_ 2556690585 P9_BalSwCell144 "电池包9的电芯144均衡状态";
CM_ SG_ 2556756121 P9_CellVoltage145 "电池包9的单体电压145";
CM_ SG_ 2556756121 P9_CellVoltage146 "电池包9的单体电压146";
CM_ SG_ 2556756121 P9_CellVoltage147 "电池包9的单体电压147";
CM_ SG_ 2556756121 P9_CellVoltage148 "电池包9的单体电压148";
CM_ SG_ 2556756121 P9_BalSwCell145 "电池包9的电芯145均衡状态";
CM_ SG_ 2556756121 P9_BalSwCell146 "电池包9的电芯146均衡状态";
CM_ SG_ 2556756121 P9_BalSwCell147 "电池包9的电芯147均衡状态";
CM_ SG_ 2556756121 P9_BalSwCell148 "电池包9的电芯148均衡状态";
CM_ SG_ 2556821657 P9_CellVoltage149 "电池包9的单体电压149";
CM_ SG_ 2556821657 P9_CellVoltage150 "电池包9的单体电压150";
CM_ SG_ 2556821657 P9_CellVoltage151 "电池包9的单体电压151";
CM_ SG_ 2556821657 P9_CellVoltage152 "电池包9的单体电压152";
CM_ SG_ 2556821657 P9_BalSwCell149 "电池包9的电芯149均衡状态";
CM_ SG_ 2556821657 P9_BalSwCell150 "电池包9的电芯150均衡状态";
CM_ SG_ 2556821657 P9_BalSwCell151 "电池包9的电芯151均衡状态";
CM_ SG_ 2556821657 P9_BalSwCell152 "电池包9的电芯152均衡状态";
CM_ SG_ 2556887193 P9_CellVoltage153 "电池包9的单体电压153";
CM_ SG_ 2556887193 P9_CellVoltage154 "电池包9的单体电压154";
CM_ SG_ 2556887193 P9_CellVoltage155 "电池包9的单体电压155";
CM_ SG_ 2556887193 P9_CellVoltage156 "电池包9的单体电压156";
CM_ SG_ 2556887193 P9_BalSwCell153 "电池包9的电芯153均衡状态";
CM_ SG_ 2556887193 P9_BalSwCell154 "电池包9的电芯154均衡状态";
CM_ SG_ 2556887193 P9_BalSwCell155 "电池包9的电芯155均衡状态";
CM_ SG_ 2556887193 P9_BalSwCell156 "电池包9的电芯156均衡状态";
CM_ SG_ 2556952729 P9_CellVoltage157 "电池包9的单体电压157";
CM_ SG_ 2556952729 P9_CellVoltage158 "电池包9的单体电压158";
CM_ SG_ 2556952729 P9_CellVoltage159 "电池包9的单体电压159";
CM_ SG_ 2556952729 P9_CellVoltage160 "电池包9的单体电压160";
CM_ SG_ 2556952729 P9_BalSwCell157 "电池包9的电芯157均衡状态";
CM_ SG_ 2556952729 P9_BalSwCell158 "电池包9的电芯158均衡状态";
CM_ SG_ 2556952729 P9_BalSwCell159 "电池包9的电芯159均衡状态";
CM_ SG_ 2556952729 P9_BalSwCell160 "电池包9的电芯160均衡状态";
CM_ SG_ 2557018265 P9_CellVoltage161 "电池包9的单体电压161";
CM_ SG_ 2557018265 P9_CellVoltage162 "电池包9的单体电压162";
CM_ SG_ 2557018265 P9_CellVoltage163 "电池包9的单体电压163";
CM_ SG_ 2557018265 P9_CellVoltage164 "电池包9的单体电压164";
CM_ SG_ 2557018265 P9_BalSwCell161 "电池包9的电芯161均衡状态";
CM_ SG_ 2557018265 P9_BalSwCell162 "电池包9的电芯162均衡状态";
CM_ SG_ 2557018265 P9_BalSwCell163 "电池包9的电芯163均衡状态";
CM_ SG_ 2557018265 P9_BalSwCell164 "电池包9的电芯164均衡状态";
CM_ SG_ 2557083801 P9_CellVoltage165 "电池包9的单体电压165";
CM_ SG_ 2557083801 P9_CellVoltage166 "电池包9的单体电压166";
CM_ SG_ 2557083801 P9_CellVoltage167 "电池包9的单体电压167";
CM_ SG_ 2557083801 P9_CellVoltage168 "电池包9的单体电压168";
CM_ SG_ 2557083801 P9_BalSwCell165 "电池包9的电芯165均衡状态";
CM_ SG_ 2557083801 P9_BalSwCell166 "电池包9的电芯166均衡状态";
CM_ SG_ 2557083801 P9_BalSwCell167 "电池包9的电芯167均衡状态";
CM_ SG_ 2557083801 P9_BalSwCell168 "电池包9的电芯168均衡状态";
CM_ SG_ 2557149337 P9_CellVoltage169 "电池包9的单体电压169";
CM_ SG_ 2557149337 P9_CellVoltage170 "电池包9的单体电压170";
CM_ SG_ 2557149337 P9_CellVoltage171 "电池包9的单体电压171";
CM_ SG_ 2557149337 P9_CellVoltage172 "电池包9的单体电压172";
CM_ SG_ 2557149337 P9_BalSwCell169 "电池包9的电芯169均衡状态";
CM_ SG_ 2557149337 P9_BalSwCell170 "电池包9的电芯170均衡状态";
CM_ SG_ 2557149337 P9_BalSwCell171 "电池包9的电芯171均衡状态";
CM_ SG_ 2557149337 P9_BalSwCell172 "电池包9的电芯172均衡状态";
CM_ SG_ 2557214873 P9_CellVoltage173 "电池包9的单体电压173";
CM_ SG_ 2557214873 P9_CellVoltage174 "电池包9的单体电压174";
CM_ SG_ 2557214873 P9_CellVoltage175 "电池包9的单体电压175";
CM_ SG_ 2557214873 P9_CellVoltage176 "电池包9的单体电压176";
CM_ SG_ 2557214873 P9_BalSwCell173 "电池包9的电芯173均衡状态";
CM_ SG_ 2557214873 P9_BalSwCell174 "电池包9的电芯174均衡状态";
CM_ SG_ 2557214873 P9_BalSwCell175 "电池包9的电芯175均衡状态";
CM_ SG_ 2557214873 P9_BalSwCell176 "电池包9的电芯176均衡状态";
CM_ SG_ 2557280409 P9_CellVoltage177 "电池包9的单体电压177";
CM_ SG_ 2557280409 P9_CellVoltage178 "电池包9的单体电压178";
CM_ SG_ 2557280409 P9_CellVoltage179 "电池包9的单体电压179";
CM_ SG_ 2557280409 P9_CellVoltage180 "电池包9的单体电压180";
CM_ SG_ 2557280409 P9_BalSwCell177 "电池包9的电芯177均衡状态";
CM_ SG_ 2557280409 P9_BalSwCell178 "电池包9的电芯178均衡状态";
CM_ SG_ 2557280409 P9_BalSwCell179 "电池包9的电芯179均衡状态";
CM_ SG_ 2557280409 P9_BalSwCell180 "电池包9的电芯180均衡状态";
CM_ SG_ 2557345945 P9_CellVoltage181 "电池包9的单体电压181";
CM_ SG_ 2557345945 P9_CellVoltage182 "电池包9的单体电压182";
CM_ SG_ 2557345945 P9_CellVoltage183 "电池包9的单体电压183";
CM_ SG_ 2557345945 P9_CellVoltage184 "电池包9的单体电压184";
CM_ SG_ 2557345945 P9_BalSwCell181 "电池包9的电芯181均衡状态";
CM_ SG_ 2557345945 P9_BalSwCell182 "电池包9的电芯182均衡状态";
CM_ SG_ 2557345945 P9_BalSwCell183 "电池包9的电芯183均衡状态";
CM_ SG_ 2557345945 P9_BalSwCell184 "电池包9的电芯184均衡状态";
CM_ SG_ 2557411481 P9_CellVoltage185 "电池包9的单体电压185";
CM_ SG_ 2557411481 P9_CellVoltage186 "电池包9的单体电压186";
CM_ SG_ 2557411481 P9_CellVoltage187 "电池包9的单体电压187";
CM_ SG_ 2557411481 P9_CellVoltage188 "电池包9的单体电压188";
CM_ SG_ 2557411481 P9_BalSwCell185 "电池包9的电芯185均衡状态";
CM_ SG_ 2557411481 P9_BalSwCell186 "电池包9的电芯186均衡状态";
CM_ SG_ 2557411481 P9_BalSwCell187 "电池包9的电芯187均衡状态";
CM_ SG_ 2557411481 P9_BalSwCell188 "电池包9的电芯188均衡状态";
CM_ SG_ 2557477017 P9_CellVoltage189 "电池包9的单体电压189";
CM_ SG_ 2557477017 P9_CellVoltage190 "电池包9的单体电压190";
CM_ SG_ 2557477017 P9_CellVoltage191 "电池包9的单体电压191";
CM_ SG_ 2557477017 P9_CellVoltage192 "电池包9的单体电压192";
CM_ SG_ 2557477017 P9_BalSwCell189 "电池包9的电芯189均衡状态";
CM_ SG_ 2557477017 P9_BalSwCell190 "电池包9的电芯190均衡状态";
CM_ SG_ 2557477017 P9_BalSwCell191 "电池包9的电芯191均衡状态";
CM_ SG_ 2557477017 P9_BalSwCell192 "电池包9的电芯192均衡状态";
CM_ SG_ 2558525593 P9_CellTemp1 "电池包9的单体温度1";
CM_ SG_ 2558525593 P9_CellTemp2 "电池包9的单体温度2";
CM_ SG_ 2558525593 P9_CellTemp3 "电池包9的单体温度3";
CM_ SG_ 2558525593 P9_CellTemp4 "电池包9的单体温度4";
CM_ SG_ 2558525593 P9_CellTemp5 "电池包9的单体温度5";
CM_ SG_ 2558591129 P9_CellTemp6 "电池包9的单体温度6";
CM_ SG_ 2558591129 P9_CellTemp7 "电池包9的单体温度7";
CM_ SG_ 2558591129 P9_CellTemp8 "电池包9的单体温度8";
CM_ SG_ 2558591129 P9_CellTemp9 "电池包9的单体温度9";
CM_ SG_ 2558591129 P9_CellTemp10 "电池包9的单体温度10";
CM_ SG_ 2558656665 P9_CellTemp11 "电池包9的单体温度11";
CM_ SG_ 2558656665 P9_CellTemp12 "电池包9的单体温度12";
CM_ SG_ 2558656665 P9_CellTemp13 "电池包9的单体温度13";
CM_ SG_ 2558656665 P9_CellTemp14 "电池包9的单体温度14";
CM_ SG_ 2558656665 P9_CellTemp15 "电池包9的单体温度15";
CM_ SG_ 2558722201 P9_CellTemp16 "电池包9的单体温度16";
CM_ SG_ 2558722201 P9_CellTemp17 "电池包9的单体温度17";
CM_ SG_ 2558722201 P9_CellTemp18 "电池包9的单体温度18";
CM_ SG_ 2558722201 P9_CellTemp19 "电池包9的单体温度19";
CM_ SG_ 2558722201 P9_CellTemp20 "电池包9的单体温度20";
CM_ SG_ 2558787737 P9_CellTemp21 "电池包9的单体温度21";
CM_ SG_ 2558787737 P9_CellTemp22 "电池包9的单体温度22";
CM_ SG_ 2558787737 P9_CellTemp23 "电池包9的单体温度23";
CM_ SG_ 2558787737 P9_CellTemp24 "电池包9的单体温度24";
CM_ SG_ 2558787737 P9_CellTemp25 "电池包9的单体温度25";
CM_ SG_ 2558853273 P9_CellTemp26 "电池包9的单体温度26";
CM_ SG_ 2558853273 P9_CellTemp27 "电池包9的单体温度27";
CM_ SG_ 2558853273 P9_CellTemp28 "电池包9的单体温度28";
CM_ SG_ 2558853273 P9_CellTemp29 "电池包9的单体温度29";
CM_ SG_ 2558853273 P9_CellTemp30 "电池包9的单体温度30";
CM_ SG_ 2558918809 P9_CellTemp31 "电池包9的单体温度31";
CM_ SG_ 2558918809 P9_CellTemp32 "电池包9的单体温度32";
CM_ SG_ 2558918809 P9_CellTemp33 "电池包9的单体温度33";
CM_ SG_ 2558918809 P9_CellTemp34 "电池包9的单体温度34";
CM_ SG_ 2558918809 P9_CellTemp35 "电池包9的单体温度35";
CM_ SG_ 2558984345 P9_CellTemp36 "电池包9的单体温度36";
CM_ SG_ 2558984345 P9_CellTemp37 "电池包9的单体温度37";
CM_ SG_ 2558984345 P9_CellTemp38 "电池包9的单体温度38";
CM_ SG_ 2558984345 P9_CellTemp39 "电池包9的单体温度39";
CM_ SG_ 2558984345 P9_CellTemp40 "电池包9的单体温度40";
CM_ SG_ 2559049881 P9_CellTemp41 "电池包9的单体温度41";
CM_ SG_ 2559049881 P9_CellTemp42 "电池包9的单体温度42";
CM_ SG_ 2559049881 P9_CellTemp43 "电池包9的单体温度43";
CM_ SG_ 2559049881 P9_CellTemp44 "电池包9的单体温度44";
CM_ SG_ 2559049881 P9_CellTemp45 "电池包9的单体温度45";
CM_ SG_ 2559115417 P9_CellTemp46 "电池包9的单体温度46";
CM_ SG_ 2559115417 P9_CellTemp47 "电池包9的单体温度47";
CM_ SG_ 2559115417 P9_CellTemp48 "电池包9的单体温度48";
CM_ SG_ 2559115417 P9_CellTemp49 "电池包9的单体温度49";
CM_ SG_ 2559115417 P9_CellTemp50 "电池包9的单体温度50";
CM_ SG_ 2559180953 P9_CellTemp51 "电池包9的单体温度51";
CM_ SG_ 2559180953 P9_CellTemp52 "电池包9的单体温度52";
CM_ SG_ 2559180953 P9_CellTemp53 "电池包9的单体温度53";
CM_ SG_ 2559180953 P9_CellTemp54 "电池包9的单体温度54";
CM_ SG_ 2559180953 P9_CellTemp55 "电池包9的单体温度55";
CM_ SG_ 2559246489 P9_CellTemp56 "电池包9的单体温度56";
CM_ SG_ 2559246489 P9_CellTemp57 "电池包9的单体温度57";
CM_ SG_ 2559246489 P9_CellTemp58 "电池包9的单体温度58";
CM_ SG_ 2559246489 P9_CellTemp59 "电池包9的单体温度59";
CM_ SG_ 2559246489 P9_CellTemp60 "电池包9的单体温度60";
CM_ SG_ 2559312025 P9_CellTemp61 "电池包9的单体温度61";
CM_ SG_ 2559312025 P9_CellTemp62 "电池包9的单体温度62";
CM_ SG_ 2559312025 P9_CellTemp63 "电池包9的单体温度63";
CM_ SG_ 2559312025 P9_CellTemp64 "电池包9的单体温度64";
CM_ SG_ 2559312025 P9_CellTemp65 "电池包9的单体温度65";
CM_ SG_ 2559377561 P9_CellTemp66 "电池包9的单体温度66";
CM_ SG_ 2559377561 P9_CellTemp67 "电池包9的单体温度67";
CM_ SG_ 2559377561 P9_CellTemp68 "电池包9的单体温度68";
CM_ SG_ 2559377561 P9_CellTemp69 "电池包9的单体温度69";
CM_ SG_ 2559377561 P9_CellTemp70 "电池包9的单体温度70";
CM_ SG_ 2559443097 P9_CellTemp71 "电池包9的单体温度71";
CM_ SG_ 2559443097 P9_CellTemp72 "电池包9的单体温度72";
CM_ SG_ 2559443097 P9_CellTemp73 "电池包9的单体温度73";
CM_ SG_ 2559443097 P9_CellTemp74 "电池包9的单体温度74";
CM_ SG_ 2559443097 P9_CellTemp75 "电池包9的单体温度75";
CM_ SG_ 2559508633 P9_CellTemp76 "电池包9的单体温度76";
CM_ SG_ 2559508633 P9_CellTemp77 "电池包9的单体温度77";
CM_ SG_ 2559508633 P9_CellTemp78 "电池包9的单体温度78";
CM_ SG_ 2559508633 P9_CellTemp79 "电池包9的单体温度79";
CM_ SG_ 2559508633 P9_CellTemp80 "电池包9的单体温度80";
CM_ SG_ 2559574169 P9_CellTemp81 "电池包9的单体温度81";
CM_ SG_ 2559574169 P9_CellTemp82 "电池包9的单体温度82";
CM_ SG_ 2559574169 P9_CellTemp83 "电池包9的单体温度83";
CM_ SG_ 2559574169 P9_CellTemp84 "电池包9的单体温度84";
CM_ SG_ 2559574169 P9_CellTemp85 "电池包9的单体温度85";
CM_ SG_ 2559639705 P9_CellTemp86 "电池包9的单体温度86";
CM_ SG_ 2559639705 P9_CellTemp87 "电池包9的单体温度87";
CM_ SG_ 2559639705 P9_CellTemp88 "电池包9的单体温度88";
CM_ SG_ 2559639705 P9_CellTemp89 "电池包9的单体温度89";
CM_ SG_ 2559639705 P9_CellTemp90 "电池包9的单体温度90";
CM_ SG_ 2559705241 P9_CellTemp91 "电池包9的单体温度91";
CM_ SG_ 2559705241 P9_CellTemp92 "电池包9的单体温度92";
CM_ SG_ 2559705241 P9_CellTemp93 "电池包9的单体温度93";
CM_ SG_ 2559705241 P9_CellTemp94 "电池包9的单体温度94";
CM_ SG_ 2559705241 P9_CellTemp95 "电池包9的单体温度95";
CM_ SG_ 2559770777 P9_CellTemp96 "电池包9的单体温度96";
CM_ SG_ 2559770777 P9_CellTemp97 "电池包9的单体温度97";
CM_ SG_ 2559770777 P9_CellTemp98 "电池包9的单体温度98";
CM_ SG_ 2559770777 P9_CellTemp99 "电池包9的单体温度99";
CM_ SG_ 2559770777 P9_CellTemp100 "电池包9的单体温度100";
CM_ SG_ 2559836313 P9_CellTemp101 "电池包9的单体温度101";
CM_ SG_ 2559836313 P9_CellTemp102 "电池包9的单体温度102";
CM_ SG_ 2559836313 P9_CellTemp103 "电池包9的单体温度103";
CM_ SG_ 2559836313 P9_CellTemp104 "电池包9的单体温度104";
CM_ SG_ 2559836313 P9_CellTemp105 "电池包9的单体温度105";
CM_ SG_ 2559901849 P9_CellTemp106 "电池包9的单体温度106";
CM_ SG_ 2559901849 P9_CellTemp107 "电池包9的单体温度107";
CM_ SG_ 2559901849 P9_CellTemp108 "电池包9的单体温度108";
CM_ SG_ 2559901849 P9_CellTemp109 "电池包9的单体温度109";
CM_ SG_ 2559901849 P9_CellTemp110 "电池包9的单体温度110";
CM_ SG_ 2559967385 P9_CellTemp111 "电池包9的单体温度111";
CM_ SG_ 2559967385 P9_CellTemp112 "电池包9的单体温度112";
CM_ SG_ 2559967385 P9_CellTemp113 "电池包9的单体温度113";
CM_ SG_ 2559967385 P9_CellTemp114 "电池包9的单体温度114";
CM_ SG_ 2559967385 P9_CellTemp115 "电池包9的单体温度115";
CM_ SG_ 2560032921 P9_CellTemp116 "电池包9的单体温度116";
CM_ SG_ 2560032921 P9_CellTemp117 "电池包9的单体温度117";
CM_ SG_ 2560032921 P9_CellTemp118 "电池包9的单体温度118";
CM_ SG_ 2560032921 P9_CellTemp119 "电池包9的单体温度119";
CM_ SG_ 2560032921 P9_CellTemp120 "电池包9的单体温度120";
CM_ SG_ 2560098457 P9_CellTemp121 "电池包9的单体温度121";
CM_ SG_ 2560098457 P9_CellTemp122 "电池包9的单体温度122";
CM_ SG_ 2560098457 P9_CellTemp123 "电池包9的单体温度123";
CM_ SG_ 2560098457 P9_CellTemp124 "电池包9的单体温度124";
CM_ SG_ 2560098457 P9_CellTemp125 "电池包9的单体温度125";
CM_ SG_ 2560163993 P9_CellTemp126 "电池包9的单体温度126";
CM_ SG_ 2560163993 P9_CellTemp127 "电池包9的单体温度127";
CM_ SG_ 2560163993 P9_CellTemp128 "电池包9的单体温度128";
CM_ SG_ 2560163993 P9_CellTemp129 "电池包9的单体温度129";
CM_ SG_ 2560163993 P9_CellTemp130 "电池包9的单体温度130";
CM_ SG_ 2560229529 P9_CellTemp131 "电池包9的单体温度131";
CM_ SG_ 2560229529 P9_CellTemp132 "电池包9的单体温度132";
CM_ SG_ 2560229529 P9_CellTemp133 "电池包9的单体温度133";
CM_ SG_ 2560229529 P9_CellTemp134 "电池包9的单体温度134";
CM_ SG_ 2560229529 P9_CellTemp135 "电池包9的单体温度135";
CM_ SG_ 2560295065 P9_CellTemp136 "电池包9的单体温度136";
CM_ SG_ 2560295065 P9_CellTemp137 "电池包9的单体温度137";
CM_ SG_ 2560295065 P9_CellTemp138 "电池包9的单体温度138";
CM_ SG_ 2560295065 P9_CellTemp139 "电池包9的单体温度139";
CM_ SG_ 2560295065 P9_CellTemp140 "电池包9的单体温度140";
CM_ SG_ 2560360601 P9_CellTemp141 "电池包9的单体温度141";
CM_ SG_ 2560360601 P9_CellTemp142 "电池包9的单体温度142";
CM_ SG_ 2560360601 P9_CellTemp143 "电池包9的单体温度143";
CM_ SG_ 2560360601 P9_CellTemp144 "电池包9的单体温度144";
CM_ SG_ 2560360601 P9_CellTemp145 "电池包9的单体温度145";
CM_ SG_ 2560426137 P9_CellTemp146 "电池包9的单体温度146";
CM_ SG_ 2560426137 P9_CellTemp147 "电池包9的单体温度147";
CM_ SG_ 2560426137 P9_CellTemp148 "电池包9的单体温度148";
CM_ SG_ 2560426137 P9_CellTemp149 "电池包9的单体温度149";
CM_ SG_ 2560426137 P9_CellTemp150 "电池包9的单体温度150";
CM_ SG_ 2560491673 P9_CellTemp151 "电池包9的单体温度151";
CM_ SG_ 2560491673 P9_CellTemp152 "电池包9的单体温度152";
CM_ SG_ 2560491673 P9_CellTemp153 "电池包9的单体温度153";
CM_ SG_ 2560491673 P9_CellTemp154 "电池包9的单体温度154";
CM_ SG_ 2560491673 P9_CellTemp155 "电池包9的单体温度155";
CM_ SG_ 2560557209 P9_CellTemp156 "电池包9的单体温度156";
CM_ SG_ 2560557209 P9_CellTemp157 "电池包9的单体温度157";
CM_ SG_ 2560557209 P9_CellTemp158 "电池包9的单体温度158";
CM_ SG_ 2560557209 P9_CellTemp159 "电池包9的单体温度159";
CM_ SG_ 2560557209 P9_CellTemp160 "电池包9的单体温度160";
CM_ SG_ 2560622745 P9_CellTemp161 "电池包9的单体温度161";
CM_ SG_ 2560622745 P9_CellTemp162 "电池包9的单体温度162";
CM_ SG_ 2560622745 P9_CellTemp163 "电池包9的单体温度163";
CM_ SG_ 2560622745 P9_CellTemp164 "电池包9的单体温度164";
CM_ SG_ 2560622745 P9_CellTemp165 "电池包9的单体温度165";
CM_ SG_ 2560688281 P9_CellTemp166 "电池包9的单体温度166";
CM_ SG_ 2560688281 P9_CellTemp167 "电池包9的单体温度167";
CM_ SG_ 2560688281 P9_CellTemp168 "电池包9的单体温度168";
CM_ SG_ 2560688281 P9_CellTemp169 "电池包9的单体温度169";
CM_ SG_ 2560688281 P9_CellTemp170 "电池包9的单体温度170";
CM_ SG_ 2560753817 P9_CellTemp171 "电池包9的单体温度171";
CM_ SG_ 2560753817 P9_CellTemp172 "电池包9的单体温度172";
CM_ SG_ 2560753817 P9_CellTemp173 "电池包9的单体温度173";
CM_ SG_ 2560753817 P9_CellTemp174 "电池包9的单体温度174";
CM_ SG_ 2560753817 P9_CellTemp175 "电池包9的单体温度175";
CM_ SG_ 2560819353 P9_CellTemp176 "电池包9的单体温度176";
CM_ SG_ 2560819353 P9_CellTemp177 "电池包9的单体温度177";
CM_ SG_ 2560819353 P9_CellTemp178 "电池包9的单体温度178";
CM_ SG_ 2560819353 P9_CellTemp179 "电池包9的单体温度179";
CM_ SG_ 2560819353 P9_CellTemp180 "电池包9的单体温度180";
CM_ SG_ 2560884889 P9_CellTemp181 "电池包9的单体温度181";
CM_ SG_ 2560884889 P9_CellTemp182 "电池包9的单体温度182";
CM_ SG_ 2560884889 P9_CellTemp183 "电池包9的单体温度183";
CM_ SG_ 2560884889 P9_CellTemp184 "电池包9的单体温度184";
CM_ SG_ 2560884889 P9_CellTemp185 "电池包9的单体温度185";
CM_ SG_ 2560950425 P9_CellTemp186 "电池包9的单体温度186";
CM_ SG_ 2560950425 P9_CellTemp187 "电池包9的单体温度187";
CM_ SG_ 2560950425 P9_CellTemp188 "电池包9的单体温度188";
CM_ SG_ 2560950425 P9_CellTemp189 "电池包9的单体温度189";
CM_ SG_ 2560950425 P9_CellTemp190 "电池包9的单体温度190";
CM_ SG_ 2561015961 P9_CellTemp191 "电池包9的单体温度191";
CM_ SG_ 2561015961 P9_CellTemp192 "电池包9的单体温度192";
CM_ SG_ 2561015961 P9_DatLen16DbgInfo1 "长度为16的调试信息1";
CM_ SG_ 2561015961 P9_DatLen16DbgInfo2 "长度为16的调试信息2";
CM_ SG_ 2561015961 P9_DatLen16DbgInfo3 "长度为16的调试信息3";
CM_ SG_ 2561015961 P9_DatLen16DbgInfo4 "长度为16的调试信息4";
CM_ SG_ 2550399146 P10_BMSPwrSuplVlt1 "电池包10的BMS供电电源电压1";
CM_ SG_ 2550399146 P10_BMSPwrSuplVlt2 "电池包10的BMS供电电源电压2";
CM_ SG_ 2550399146 P10_ChrgStationAuxPwrSuplVlt "电池包10的快充桩A+电压";
CM_ SG_ 2550399146 P10_BMSKL15ON "电池包10的BMS唤醒信号";
CM_ SG_ 2550399146 P10_DCStepState "电池包10的充电状态机";
CM_ SG_ 2550399146 P10_ExtLvWakeup_28VOnly "电池包10的外部唤醒";
CM_ SG_ 2550464682 P10_PackVltUprLmt "电池包10的电压使用上限";
CM_ SG_ 2550464682 P10_PackVltLoLmt "电池包10的电压使用下限";
CM_ SG_ 2550464682 P10_PackMaxDschrgCrnt "电池包10的最大允许放电电流";
CM_ SG_ 2550464682 P10_PackMaxChrgCrnt "电池包10的最大允许充电电流";
CM_ SG_ 2550530218 P10_PackDschrgPwrLmt "电池包10的放电功率限值";
CM_ SG_ 2550530218 P10_PackDschrgPwrStat "电池包10的放电功率状态";
CM_ SG_ 2550530218 P10_PackChrgPwrLmt "电池包10的充电功率限值";
CM_ SG_ 2550530218 P10_PackChrgPwrStat "电池包10的充电功率状态";
CM_ SG_ 2550595754 P10_ChrgrCplrStat "电池包10的充电枪连接状态";
CM_ SG_ 2550595754 P10_HVBattChrgSysStatus "电池包10的充电系统状态";
CM_ SG_ 2550595754 P10_DCChrgCrntCmd "电池包10的直流充电请求电流";
CM_ SG_ 2550595754 P10_CC2Vlt "电池包10的CC2电压值";
CM_ SG_ 2550595754 P10_DCRcptPosTemp "电池包10的快充充电插座正极温度";
CM_ SG_ 2550595754 P10_DCRcptNegTemp "电池包10的快充充电插座负极温度";
CM_ SG_ 2550595754 P10_Tm2FullChrg "电池包10满充剩余时间";
CM_ SG_ 2550661290 P10_Inlet1ClntTemp "进水口1冷却液温度";
CM_ SG_ 2550661290 P10_Inlet2ClntTemp "进水口2冷却液温度";
CM_ SG_ 2550661290 P10_Outlet1ClntTemp "出水口1冷却液温度";
CM_ SG_ 2550661290 P10_Outlet2ClntTemp "出水口2冷却液温度";
CM_ SG_ 2550661290 P10_TrgtClntTemp "冷却水目标温度";
CM_ SG_ 2550661290 P10_TrgtClntFlowRate "冷却水目标流量";
CM_ SG_ 2550726826 P10_MaxCellVlt "电池包10的最大单体电压";
CM_ SG_ 2550726826 P10_MaxCellVltNum "电池包10的最大单体电压编号";
CM_ SG_ 2550726826 P10_MinCellVlt "电池包10的最小单体电压";
CM_ SG_ 2550726826 P10_MinCellVltNum "电池包10的最小单体电压编号";
CM_ SG_ 2550726826 P10_AvgCellVlt "电池包10的平均单体电压";
CM_ SG_ 2550792362 P10_MaxCellTemp "电池包10的最高单体温度";
CM_ SG_ 2550792362 P10_MaxCellTempNum "电池包10的最高单体温度编号";
CM_ SG_ 2550792362 P10_MinCellTemp "电池包10的最低单体温度";
CM_ SG_ 2550792362 P10_MinCellTempNum "电池包10的最低单体温度编号";
CM_ SG_ 2550792362 P10_AvgCellTemp "电池包10的单体平均温度";
CM_ SG_ 2550857898 P10_PackTotFltNum "电池包10的电池故障总数";
CM_ SG_ 2550857898 P10_CellOverVoltage "电池包10的单体过压";
CM_ SG_ 2550857898 P10_CellUnderVoltage "电池包10的单体欠压";
CM_ SG_ 2550857898 P10_CellVoltageDiffHi "电池包10的单体压差过大";
CM_ SG_ 2550857898 P10_PackOverVoltage "电池包10的电压过高";
CM_ SG_ 2550857898 P10_PackUnderVoltage "电池包10的电压过低";
CM_ SG_ 2550857898 P10_CellOverTemp "电池包10的单体过温";
CM_ SG_ 2550857898 P10_CellTempLow "电池包10的单体温度过低";
CM_ SG_ 2550857898 P10_CellTempDiffHi "电池包10的单体温度差异过大";
CM_ SG_ 2550857898 P10_PackDschrgCrntHi "电池包10的放电电流过流";
CM_ SG_ 2550857898 P10_PackChrgCrntHi "电池包10的充电电流过流";
CM_ SG_ 2550857898 P10_PackCrnSnsr1OffsetHi "电池包10的电流传感器1零漂过大";
CM_ SG_ 2550857898 P10_HVIsolFlt "电池包10的高压绝缘故障";
CM_ SG_ 2550857898 P10_HVILFlt "电池包10的高压互锁故障";
CM_ SG_ 2550857898 P10_ThrmlRunaway "电池包10的热失控故障";
CM_ SG_ 2550857898 P10_CellVoltInvalid "电池包10的单体电压采样失效";
CM_ SG_ 2550857898 P10_CellTempInvalid "电池包10的电芯温度采样失效";
CM_ SG_ 2550857898 P10_DaisyChainComFlt "电池包10的菊花链通信故障";
CM_ SG_ 2550857898 P10_PackVoltRatFlt "电池包10的总电压与单体电压总和偏差过大";
CM_ SG_ 2550857898 P10_CrntSnsr1Invalid "电池包10的电流传感器1电流采样失效";
CM_ SG_ 2550857898 P10_CrntSnsr1OOR "电池包10的电流传感器1电流超出采样范围";
CM_ SG_ 2550857898 P10_CrntSnsr2Invalid "电池包10的电流传感器2电流采样失效";
CM_ SG_ 2550857898 P10_CrntSnsr2OOR "电池包10的电流传感器2电流超出采样范围";
CM_ SG_ 2550857898 P10_PackCrnSnsr2OffsetHi "电池包10的电流传感器2零漂过大";
CM_ SG_ 2550857898 P10_OutofEnergy "电池包10的电池剩余电量低";
CM_ SG_ 2550857898 P10_IsolDetCircErr "电池包10的绝缘检测电路失效";
CM_ SG_ 2550857898 P10_HVILCircShortToGND "电池包10的高压互锁对地短路";
CM_ SG_ 2550857898 P10_HVILCircShortToPwr "电池包10的高压互锁对电源短路";
CM_ SG_ 2550923434 P10_MainPosCntctrStkClsd "电池包10的主正继电器粘连故障";
CM_ SG_ 2550923434 P10_MainPosCntctrStkOpn "电池包10的主正继电器常开故障";
CM_ SG_ 2550923434 P10_MainNegCntctr1StkClsd "电池包10的主负继电器1粘连故障";
CM_ SG_ 2550923434 P10_MainNegCntctr1StkOpn "电池包10的主负继电器1常开故障";
CM_ SG_ 2550923434 P10_MainNegCntctr2StkClsd "电池包10的主负继电器2粘连故障";
CM_ SG_ 2550923434 P10_MainNegCntctr2StkOpn "电池包10的主负继电器2常开故障";
CM_ SG_ 2550923434 P10_PrechargTmOut "电池包10的预充超时故障";
CM_ SG_ 2550923434 P10_PrechrgCrntHi "电池包10的预充过流故障";
CM_ SG_ 2550923434 P10_ChrgCplrPosTempHi "电池包10的充电正极接口温度过高故障";
CM_ SG_ 2550923434 P10_ChrgCplrNegTempHi "电池包10的充电负极接口温度过高故障";
CM_ SG_ 2550923434 P10_BMSPwrSuplVlt1Hi "电池包10的BMS供电电压1过高";
CM_ SG_ 2550923434 P10_BMSPwrSuplVlt1Lo "电池包10的BMS供电电压1过低";
CM_ SG_ 2550923434 P10_BMSPwrSuplVlt2Hi "电池包10的BMS供电电压2过高";
CM_ SG_ 2550923434 P10_BMSPwrSuplVlt2Lo "电池包10的BMS供电电压2过低";
CM_ SG_ 2550923434 P10_CntctrCirPwrSuplVltLo "电池包10的继电器驱动供电电压过低";
CM_ SG_ 2550923434 P10_CntctrCirPwrSuplVltHi "电池包10的继电器驱动供电电压过高";
CM_ SG_ 2550923434 P10_CAN1BusOff "电池包10的CAN1通信Bus off";
CM_ SG_ 2550923434 P10_CAN1BusTmOut "电池包10的CAN1报文超时（Timeout）";
CM_ SG_ 2550923434 P10_CAN2BusOff "电池包10的CAN2通信Bus off";
CM_ SG_ 2550923434 P10_CAN2BusTmOut "电池包10的CAN2报文超时（Timeout）";
CM_ SG_ 2550923434 P10_CellBalCircTempHi "电池包10的均衡电路过温";
CM_ SG_ 2550923434 P10_ClntInTempHi "电池包10的入水口温度过高";
CM_ SG_ 2550923434 P10_ClntOutTempHi "电池包10的出水口温度过高";
CM_ SG_ 2550923434 P10_CellExtrmUdrVolt "电池包10的单体极限欠压";
CM_ SG_ 2550923434 P10_CellExtrmOvrVolt "电池包10的单体极限过压";
CM_ SG_ 2550923434 P10_Branch1DischrgCrntHi  "电池包10的支路1放电过流";
CM_ SG_ 2550923434 P10_Branch2DischrgCrntHi  "电池包10的支路2放电过流";
CM_ SG_ 2550923434 P10_Branch1ChrgCrntHi  "电池包10的支路1充电过流";
CM_ SG_ 2550923434 P10_Branch2ChrgCrntHi  "电池包10的支路2充电过流";
CM_ SG_ 2550923434 P10_InitFailed "电池包10的BMS初始化失败";
CM_ SG_ 2550923434 P10_PackErrCode "电池包10的故障代码";
CM_ SG_ 2550988970 P10_PackTotCellNum "电池包10的单体电池总数";
CM_ SG_ 2550988970 P10_PackTotCellTempSnsrNum "电池包10的单体温度传感器总数";
CM_ SG_ 2552299690 P10_BMSASWMajVerNum "电池包10的BMS应用层软件主版本号";
CM_ SG_ 2552299690 P10_BMSASWMinVerNum "电池包10的BMS应用层软件子版本号";
CM_ SG_ 2552299690 P10_BMSASWPatchVerNum "电池包10的BMS应用层软件修订版本号";
CM_ SG_ 2552299690 P10_BMSBSWMajVerNum "电池包10的BMS底层软件主版本号";
CM_ SG_ 2552299690 P10_BMSBSWMinVerNum "电池包10的BMS底层软件子版本号";
CM_ SG_ 2552299690 P10_BMSBSWPatchVerNum "电池包10的BMS底层软件修订版本号";
CM_ SG_ 2554396842 P10_CellVoltage1 "电池包10的单体电压1";
CM_ SG_ 2554396842 P10_CellVoltage2 "电池包10的单体电压2";
CM_ SG_ 2554396842 P10_CellVoltage3 "电池包10的单体电压3";
CM_ SG_ 2554396842 P10_CellVoltage4 "电池包10的单体电压4";
CM_ SG_ 2554396842 P10_BalSwCell1 "电池包10的电芯1均衡状态";
CM_ SG_ 2554396842 P10_BalSwCell2 "电池包10的电芯2均衡状态";
CM_ SG_ 2554396842 P10_BalSwCell3 "电池包10的电芯3均衡状态";
CM_ SG_ 2554396842 P10_BalSwCell4 "电池包10的电芯4均衡状态";
CM_ SG_ 2554462378 P10_CellVoltage5 "电池包10的单体电压5";
CM_ SG_ 2554462378 P10_CellVoltage6 "电池包10的单体电压6";
CM_ SG_ 2554462378 P10_CellVoltage7 "电池包10的单体电压7";
CM_ SG_ 2554462378 P10_CellVoltage8 "电池包10的单体电压8";
CM_ SG_ 2554462378 P10_BalSwCell5 "电池包10的电芯5均衡状态";
CM_ SG_ 2554462378 P10_BalSwCell6 "电池包10的电芯6均衡状态";
CM_ SG_ 2554462378 P10_BalSwCell7 "电池包10的电芯7均衡状态";
CM_ SG_ 2554462378 P10_BalSwCell8 "电池包10的电芯8均衡状态";
CM_ SG_ 2554527914 P10_CellVoltage9 "电池包10的单体电压9";
CM_ SG_ 2554527914 P10_CellVoltage10 "电池包10的单体电压10";
CM_ SG_ 2554527914 P10_CellVoltage11 "电池包10的单体电压11";
CM_ SG_ 2554527914 P10_CellVoltage12 "电池包10的单体电压12";
CM_ SG_ 2554527914 P10_BalSwCell9 "电池包10的电芯9均衡状态";
CM_ SG_ 2554527914 P10_BalSwCell10 "电池包10的电芯10均衡状态";
CM_ SG_ 2554527914 P10_BalSwCell11 "电池包10的电芯11均衡状态";
CM_ SG_ 2554527914 P10_BalSwCell12 "电池包10的电芯12均衡状态";
CM_ SG_ 2554593450 P10_CellVoltage13 "电池包10的单体电压13";
CM_ SG_ 2554593450 P10_CellVoltage14 "电池包10的单体电压14";
CM_ SG_ 2554593450 P10_CellVoltage15 "电池包10的单体电压15";
CM_ SG_ 2554593450 P10_CellVoltage16 "电池包10的单体电压16";
CM_ SG_ 2554593450 P10_BalSwCell13 "电池包10的电芯13均衡状态";
CM_ SG_ 2554593450 P10_BalSwCell14 "电池包10的电芯14均衡状态";
CM_ SG_ 2554593450 P10_BalSwCell15 "电池包10的电芯15均衡状态";
CM_ SG_ 2554593450 P10_BalSwCell16 "电池包10的电芯16均衡状态";
CM_ SG_ 2554658986 P10_CellVoltage17 "电池包10的单体电压17";
CM_ SG_ 2554658986 P10_CellVoltage18 "电池包10的单体电压18";
CM_ SG_ 2554658986 P10_CellVoltage19 "电池包10的单体电压19";
CM_ SG_ 2554658986 P10_CellVoltage20 "电池包10的单体电压20";
CM_ SG_ 2554658986 P10_BalSwCell17 "电池包10的电芯17均衡状态";
CM_ SG_ 2554658986 P10_BalSwCell18 "电池包10的电芯18均衡状态";
CM_ SG_ 2554658986 P10_BalSwCell19 "电池包10的电芯19均衡状态";
CM_ SG_ 2554658986 P10_BalSwCell20 "电池包10的电芯20均衡状态";
CM_ SG_ 2554724522 P10_CellVoltage21 "电池包10的单体电压21";
CM_ SG_ 2554724522 P10_CellVoltage22 "电池包10的单体电压22";
CM_ SG_ 2554724522 P10_CellVoltage23 "电池包10的单体电压23";
CM_ SG_ 2554724522 P10_CellVoltage24 "电池包10的单体电压24";
CM_ SG_ 2554724522 P10_BalSwCell21 "电池包10的电芯21均衡状态";
CM_ SG_ 2554724522 P10_BalSwCell22 "电池包10的电芯22均衡状态";
CM_ SG_ 2554724522 P10_BalSwCell23 "电池包10的电芯23均衡状态";
CM_ SG_ 2554724522 P10_BalSwCell24 "电池包10的电芯24均衡状态";
CM_ SG_ 2554790058 P10_CellVoltage25 "电池包10的单体电压25";
CM_ SG_ 2554790058 P10_CellVoltage26 "电池包10的单体电压26";
CM_ SG_ 2554790058 P10_CellVoltage27 "电池包10的单体电压27";
CM_ SG_ 2554790058 P10_CellVoltage28 "电池包10的单体电压28";
CM_ SG_ 2554790058 P10_BalSwCell25 "电池包10的电芯25均衡状态";
CM_ SG_ 2554790058 P10_BalSwCell26 "电池包10的电芯26均衡状态";
CM_ SG_ 2554790058 P10_BalSwCell27 "电池包10的电芯27均衡状态";
CM_ SG_ 2554790058 P10_BalSwCell28 "电池包10的电芯28均衡状态";
CM_ SG_ 2554855594 P10_CellVoltage29 "电池包10的单体电压29";
CM_ SG_ 2554855594 P10_CellVoltage30 "电池包10的单体电压30";
CM_ SG_ 2554855594 P10_CellVoltage31 "电池包10的单体电压31";
CM_ SG_ 2554855594 P10_CellVoltage32 "电池包10的单体电压32";
CM_ SG_ 2554855594 P10_BalSwCell29 "电池包10的电芯29均衡状态";
CM_ SG_ 2554855594 P10_BalSwCell30 "电池包10的电芯30均衡状态";
CM_ SG_ 2554855594 P10_BalSwCell31 "电池包10的电芯31均衡状态";
CM_ SG_ 2554855594 P10_BalSwCell32 "电池包10的电芯32均衡状态";
CM_ SG_ 2554921130 P10_CellVoltage33 "电池包10的单体电压33";
CM_ SG_ 2554921130 P10_CellVoltage34 "电池包10的单体电压34";
CM_ SG_ 2554921130 P10_CellVoltage35 "电池包10的单体电压35";
CM_ SG_ 2554921130 P10_CellVoltage36 "电池包10的单体电压36";
CM_ SG_ 2554921130 P10_BalSwCell33 "电池包10的电芯33均衡状态";
CM_ SG_ 2554921130 P10_BalSwCell34 "电池包10的电芯34均衡状态";
CM_ SG_ 2554921130 P10_BalSwCell35 "电池包10的电芯35均衡状态";
CM_ SG_ 2554921130 P10_BalSwCell36 "电池包10的电芯36均衡状态";
CM_ SG_ 2554986666 P10_CellVoltage37 "电池包10的单体电压37";
CM_ SG_ 2554986666 P10_CellVoltage38 "电池包10的单体电压38";
CM_ SG_ 2554986666 P10_CellVoltage39 "电池包10的单体电压39";
CM_ SG_ 2554986666 P10_CellVoltage40 "电池包10的单体电压40";
CM_ SG_ 2554986666 P10_BalSwCell37 "电池包10的电芯37均衡状态";
CM_ SG_ 2554986666 P10_BalSwCell38 "电池包10的电芯38均衡状态";
CM_ SG_ 2554986666 P10_BalSwCell39 "电池包10的电芯39均衡状态";
CM_ SG_ 2554986666 P10_BalSwCell40 "电池包10的电芯40均衡状态";
CM_ SG_ 2555052202 P10_CellVoltage41 "电池包10的单体电压41";
CM_ SG_ 2555052202 P10_CellVoltage42 "电池包10的单体电压42";
CM_ SG_ 2555052202 P10_CellVoltage43 "电池包10的单体电压43";
CM_ SG_ 2555052202 P10_CellVoltage44 "电池包10的单体电压44";
CM_ SG_ 2555052202 P10_BalSwCell41 "电池包10的电芯41均衡状态";
CM_ SG_ 2555052202 P10_BalSwCell42 "电池包10的电芯42均衡状态";
CM_ SG_ 2555052202 P10_BalSwCell43 "电池包10的电芯43均衡状态";
CM_ SG_ 2555052202 P10_BalSwCell44 "电池包10的电芯44均衡状态";
CM_ SG_ 2555117738 P10_CellVoltage45 "电池包10的单体电压45";
CM_ SG_ 2555117738 P10_CellVoltage46 "电池包10的单体电压46";
CM_ SG_ 2555117738 P10_CellVoltage47 "电池包10的单体电压47";
CM_ SG_ 2555117738 P10_CellVoltage48 "电池包10的单体电压48";
CM_ SG_ 2555117738 P10_BalSwCell45 "电池包10的电芯45均衡状态";
CM_ SG_ 2555117738 P10_BalSwCell46 "电池包10的电芯46均衡状态";
CM_ SG_ 2555117738 P10_BalSwCell47 "电池包10的电芯47均衡状态";
CM_ SG_ 2555117738 P10_BalSwCell48 "电池包10的电芯48均衡状态";
CM_ SG_ 2555183274 P10_CellVoltage49 "电池包10的单体电压49";
CM_ SG_ 2555183274 P10_CellVoltage50 "电池包10的单体电压50";
CM_ SG_ 2555183274 P10_CellVoltage51 "电池包10的单体电压51";
CM_ SG_ 2555183274 P10_CellVoltage52 "电池包10的单体电压52";
CM_ SG_ 2555183274 P10_BalSwCell49 "电池包10的电芯49均衡状态";
CM_ SG_ 2555183274 P10_BalSwCell50 "电池包10的电芯50均衡状态";
CM_ SG_ 2555183274 P10_BalSwCell51 "电池包10的电芯51均衡状态";
CM_ SG_ 2555183274 P10_BalSwCell52 "电池包10的电芯52均衡状态";
CM_ SG_ 2555248810 P10_CellVoltage53 "电池包10的单体电压53";
CM_ SG_ 2555248810 P10_CellVoltage54 "电池包10的单体电压54";
CM_ SG_ 2555248810 P10_CellVoltage55 "电池包10的单体电压55";
CM_ SG_ 2555248810 P10_CellVoltage56 "电池包10的单体电压56";
CM_ SG_ 2555248810 P10_BalSwCell53 "电池包10的电芯53均衡状态";
CM_ SG_ 2555248810 P10_BalSwCell54 "电池包10的电芯54均衡状态";
CM_ SG_ 2555248810 P10_BalSwCell55 "电池包10的电芯55均衡状态";
CM_ SG_ 2555248810 P10_BalSwCell56 "电池包10的电芯56均衡状态";
CM_ SG_ 2555314346 P10_CellVoltage57 "电池包10的单体电压57";
CM_ SG_ 2555314346 P10_CellVoltage58 "电池包10的单体电压58";
CM_ SG_ 2555314346 P10_CellVoltage59 "电池包10的单体电压59";
CM_ SG_ 2555314346 P10_CellVoltage60 "电池包10的单体电压60";
CM_ SG_ 2555314346 P10_BalSwCell57 "电池包10的电芯57均衡状态";
CM_ SG_ 2555314346 P10_BalSwCell58 "电池包10的电芯58均衡状态";
CM_ SG_ 2555314346 P10_BalSwCell59 "电池包10的电芯59均衡状态";
CM_ SG_ 2555314346 P10_BalSwCell60 "电池包10的电芯60均衡状态";
CM_ SG_ 2555379882 P10_CellVoltage61 "电池包10的单体电压61";
CM_ SG_ 2555379882 P10_CellVoltage62 "电池包10的单体电压62";
CM_ SG_ 2555379882 P10_CellVoltage63 "电池包10的单体电压63";
CM_ SG_ 2555379882 P10_CellVoltage64 "电池包10的单体电压64";
CM_ SG_ 2555379882 P10_BalSwCell61 "电池包10的电芯61均衡状态";
CM_ SG_ 2555379882 P10_BalSwCell62 "电池包10的电芯62均衡状态";
CM_ SG_ 2555379882 P10_BalSwCell63 "电池包10的电芯63均衡状态";
CM_ SG_ 2555379882 P10_BalSwCell64 "电池包10的电芯64均衡状态";
CM_ SG_ 2555445418 P10_CellVoltage65 "电池包10的单体电压65";
CM_ SG_ 2555445418 P10_CellVoltage66 "电池包10的单体电压66";
CM_ SG_ 2555445418 P10_CellVoltage67 "电池包10的单体电压67";
CM_ SG_ 2555445418 P10_CellVoltage68 "电池包10的单体电压68";
CM_ SG_ 2555445418 P10_BalSwCell65 "电池包10的电芯65均衡状态";
CM_ SG_ 2555445418 P10_BalSwCell66 "电池包10的电芯66均衡状态";
CM_ SG_ 2555445418 P10_BalSwCell67 "电池包10的电芯67均衡状态";
CM_ SG_ 2555445418 P10_BalSwCell68 "电池包10的电芯68均衡状态";
CM_ SG_ 2555510954 P10_CellVoltage69 "电池包10的单体电压69";
CM_ SG_ 2555510954 P10_CellVoltage70 "电池包10的单体电压70";
CM_ SG_ 2555510954 P10_CellVoltage71 "电池包10的单体电压71";
CM_ SG_ 2555510954 P10_CellVoltage72 "电池包10的单体电压72";
CM_ SG_ 2555510954 P10_BalSwCell69 "电池包10的电芯69均衡状态";
CM_ SG_ 2555510954 P10_BalSwCell70 "电池包10的电芯70均衡状态";
CM_ SG_ 2555510954 P10_BalSwCell71 "电池包10的电芯71均衡状态";
CM_ SG_ 2555510954 P10_BalSwCell72 "电池包10的电芯72均衡状态";
CM_ SG_ 2555576490 P10_CellVoltage73 "电池包10的单体电压73";
CM_ SG_ 2555576490 P10_CellVoltage74 "电池包10的单体电压74";
CM_ SG_ 2555576490 P10_CellVoltage75 "电池包10的单体电压75";
CM_ SG_ 2555576490 P10_CellVoltage76 "电池包10的单体电压76";
CM_ SG_ 2555576490 P10_BalSwCell73 "电池包10的电芯73均衡状态";
CM_ SG_ 2555576490 P10_BalSwCell74 "电池包10的电芯74均衡状态";
CM_ SG_ 2555576490 P10_BalSwCell75 "电池包10的电芯75均衡状态";
CM_ SG_ 2555576490 P10_BalSwCell76 "电池包10的电芯76均衡状态";
CM_ SG_ 2555642026 P10_CellVoltage77 "电池包10的单体电压77";
CM_ SG_ 2555642026 P10_CellVoltage78 "电池包10的单体电压78";
CM_ SG_ 2555642026 P10_CellVoltage79 "电池包10的单体电压79";
CM_ SG_ 2555642026 P10_CellVoltage80 "电池包10的单体电压80";
CM_ SG_ 2555642026 P10_BalSwCell77 "电池包10的电芯77均衡状态";
CM_ SG_ 2555642026 P10_BalSwCell78 "电池包10的电芯78均衡状态";
CM_ SG_ 2555642026 P10_BalSwCell79 "电池包10的电芯79均衡状态";
CM_ SG_ 2555642026 P10_BalSwCell80 "电池包10的电芯80均衡状态";
CM_ SG_ 2555707562 P10_CellVoltage81 "电池包10的单体电压81";
CM_ SG_ 2555707562 P10_CellVoltage82 "电池包10的单体电压82";
CM_ SG_ 2555707562 P10_CellVoltage83 "电池包10的单体电压83";
CM_ SG_ 2555707562 P10_CellVoltage84 "电池包10的单体电压84";
CM_ SG_ 2555707562 P10_BalSwCell81 "电池包10的电芯81均衡状态";
CM_ SG_ 2555707562 P10_BalSwCell82 "电池包10的电芯82均衡状态";
CM_ SG_ 2555707562 P10_BalSwCell83 "电池包10的电芯83均衡状态";
CM_ SG_ 2555707562 P10_BalSwCell84 "电池包10的电芯84均衡状态";
CM_ SG_ 2555773098 P10_CellVoltage85 "电池包10的单体电压85";
CM_ SG_ 2555773098 P10_CellVoltage86 "电池包10的单体电压86";
CM_ SG_ 2555773098 P10_CellVoltage87 "电池包10的单体电压87";
CM_ SG_ 2555773098 P10_CellVoltage88 "电池包10的单体电压88";
CM_ SG_ 2555773098 P10_BalSwCell85 "电池包10的电芯85均衡状态";
CM_ SG_ 2555773098 P10_BalSwCell86 "电池包10的电芯86均衡状态";
CM_ SG_ 2555773098 P10_BalSwCell87 "电池包10的电芯87均衡状态";
CM_ SG_ 2555773098 P10_BalSwCell88 "电池包10的电芯88均衡状态";
CM_ SG_ 2555838634 P10_CellVoltage89 "电池包10的单体电压89";
CM_ SG_ 2555838634 P10_CellVoltage90 "电池包10的单体电压90";
CM_ SG_ 2555838634 P10_CellVoltage91 "电池包10的单体电压91";
CM_ SG_ 2555838634 P10_CellVoltage92 "电池包10的单体电压92";
CM_ SG_ 2555838634 P10_BalSwCell89 "电池包10的电芯89均衡状态";
CM_ SG_ 2555838634 P10_BalSwCell90 "电池包10的电芯90均衡状态";
CM_ SG_ 2555838634 P10_BalSwCell91 "电池包10的电芯91均衡状态";
CM_ SG_ 2555838634 P10_BalSwCell92 "电池包10的电芯92均衡状态";
CM_ SG_ 2555904170 P10_CellVoltage93 "电池包10的单体电压93";
CM_ SG_ 2555904170 P10_CellVoltage94 "电池包10的单体电压94";
CM_ SG_ 2555904170 P10_CellVoltage95 "电池包10的单体电压95";
CM_ SG_ 2555904170 P10_CellVoltage96 "电池包10的单体电压96";
CM_ SG_ 2555904170 P10_BalSwCell93 "电池包10的电芯93均衡状态";
CM_ SG_ 2555904170 P10_BalSwCell94 "电池包10的电芯94均衡状态";
CM_ SG_ 2555904170 P10_BalSwCell95 "电池包10的电芯95均衡状态";
CM_ SG_ 2555904170 P10_BalSwCell96 "电池包10的电芯96均衡状态";
CM_ SG_ 2555969706 P10_CellVoltage97 "电池包10的单体电压97";
CM_ SG_ 2555969706 P10_CellVoltage98 "电池包10的单体电压98";
CM_ SG_ 2555969706 P10_CellVoltage99 "电池包10的单体电压99";
CM_ SG_ 2555969706 P10_CellVoltage100 "电池包10的单体电压100";
CM_ SG_ 2555969706 P10_BalSwCell97 "电池包10的电芯97均衡状态";
CM_ SG_ 2555969706 P10_BalSwCell98 "电池包10的电芯98均衡状态";
CM_ SG_ 2555969706 P10_BalSwCell99 "电池包10的电芯99均衡状态";
CM_ SG_ 2555969706 P10_BalSwCell100 "电池包10的电芯100均衡状态";
CM_ SG_ 2556035242 P10_CellVoltage101 "电池包10的单体电压101";
CM_ SG_ 2556035242 P10_CellVoltage102 "电池包10的单体电压102";
CM_ SG_ 2556035242 P10_CellVoltage103 "电池包10的单体电压103";
CM_ SG_ 2556035242 P10_CellVoltage104 "电池包10的单体电压104";
CM_ SG_ 2556035242 P10_BalSwCell101 "电池包10的电芯101均衡状态";
CM_ SG_ 2556035242 P10_BalSwCell102 "电池包10的电芯102均衡状态";
CM_ SG_ 2556035242 P10_BalSwCell103 "电池包10的电芯103均衡状态";
CM_ SG_ 2556035242 P10_BalSwCell104 "电池包10的电芯104均衡状态";
CM_ SG_ 2556100778 P10_CellVoltage105 "电池包10的单体电压105";
CM_ SG_ 2556100778 P10_CellVoltage106 "电池包10的单体电压106";
CM_ SG_ 2556100778 P10_CellVoltage107 "电池包10的单体电压107";
CM_ SG_ 2556100778 P10_CellVoltage108 "电池包10的单体电压108";
CM_ SG_ 2556100778 P10_BalSwCell105 "电池包10的电芯105均衡状态";
CM_ SG_ 2556100778 P10_BalSwCell106 "电池包10的电芯106均衡状态";
CM_ SG_ 2556100778 P10_BalSwCell107 "电池包10的电芯107均衡状态";
CM_ SG_ 2556100778 P10_BalSwCell108 "电池包10的电芯108均衡状态";
CM_ SG_ 2556166314 P10_CellVoltage109 "电池包10的单体电压109";
CM_ SG_ 2556166314 P10_CellVoltage110 "电池包10的单体电压110";
CM_ SG_ 2556166314 P10_CellVoltage111 "电池包10的单体电压111";
CM_ SG_ 2556166314 P10_CellVoltage112 "电池包10的单体电压112";
CM_ SG_ 2556166314 P10_BalSwCell109 "电池包10的电芯109均衡状态";
CM_ SG_ 2556166314 P10_BalSwCell110 "电池包10的电芯110均衡状态";
CM_ SG_ 2556166314 P10_BalSwCell111 "电池包10的电芯111均衡状态";
CM_ SG_ 2556166314 P10_BalSwCell112 "电池包10的电芯112均衡状态";
CM_ SG_ 2556231850 P10_CellVoltage113 "电池包10的单体电压113";
CM_ SG_ 2556231850 P10_CellVoltage114 "电池包10的单体电压114";
CM_ SG_ 2556231850 P10_CellVoltage115 "电池包10的单体电压115";
CM_ SG_ 2556231850 P10_CellVoltage116 "电池包10的单体电压116";
CM_ SG_ 2556231850 P10_BalSwCell113 "电池包10的电芯113均衡状态";
CM_ SG_ 2556231850 P10_BalSwCell114 "电池包10的电芯114均衡状态";
CM_ SG_ 2556231850 P10_BalSwCell115 "电池包10的电芯115均衡状态";
CM_ SG_ 2556231850 P10_BalSwCell116 "电池包10的电芯116均衡状态";
CM_ SG_ 2556297386 P10_CellVoltage117 "电池包10的单体电压117";
CM_ SG_ 2556297386 P10_CellVoltage118 "电池包10的单体电压118";
CM_ SG_ 2556297386 P10_CellVoltage119 "电池包10的单体电压119";
CM_ SG_ 2556297386 P10_CellVoltage120 "电池包10的单体电压120";
CM_ SG_ 2556297386 P10_BalSwCell117 "电池包10的电芯117均衡状态";
CM_ SG_ 2556297386 P10_BalSwCell118 "电池包10的电芯118均衡状态";
CM_ SG_ 2556297386 P10_BalSwCell119 "电池包10的电芯119均衡状态";
CM_ SG_ 2556297386 P10_BalSwCell120 "电池包10的电芯120均衡状态";
CM_ SG_ 2556362922 P10_CellVoltage121 "电池包10的单体电压121";
CM_ SG_ 2556362922 P10_CellVoltage122 "电池包10的单体电压122";
CM_ SG_ 2556362922 P10_CellVoltage123 "电池包10的单体电压123";
CM_ SG_ 2556362922 P10_CellVoltage124 "电池包10的单体电压124";
CM_ SG_ 2556362922 P10_BalSwCell121 "电池包10的电芯121均衡状态";
CM_ SG_ 2556362922 P10_BalSwCell122 "电池包10的电芯122均衡状态";
CM_ SG_ 2556362922 P10_BalSwCell123 "电池包10的电芯123均衡状态";
CM_ SG_ 2556362922 P10_BalSwCell124 "电池包10的电芯124均衡状态";
CM_ SG_ 2556428458 P10_CellVoltage125 "电池包10的单体电压125";
CM_ SG_ 2556428458 P10_CellVoltage126 "电池包10的单体电压126";
CM_ SG_ 2556428458 P10_CellVoltage127 "电池包10的单体电压127";
CM_ SG_ 2556428458 P10_CellVoltage128 "电池包10的单体电压128";
CM_ SG_ 2556428458 P10_BalSwCell125 "电池包10的电芯125均衡状态";
CM_ SG_ 2556428458 P10_BalSwCell126 "电池包10的电芯126均衡状态";
CM_ SG_ 2556428458 P10_BalSwCell127 "电池包10的电芯127均衡状态";
CM_ SG_ 2556428458 P10_BalSwCell128 "电池包10的电芯128均衡状态";
CM_ SG_ 2556493994 P10_CellVoltage129 "电池包10的单体电压129";
CM_ SG_ 2556493994 P10_CellVoltage130 "电池包10的单体电压130";
CM_ SG_ 2556493994 P10_CellVoltage131 "电池包10的单体电压131";
CM_ SG_ 2556493994 P10_CellVoltage132 "电池包10的单体电压132";
CM_ SG_ 2556493994 P10_BalSwCell129 "电池包10的电芯129均衡状态";
CM_ SG_ 2556493994 P10_BalSwCell130 "电池包10的电芯130均衡状态";
CM_ SG_ 2556493994 P10_BalSwCell131 "电池包10的电芯131均衡状态";
CM_ SG_ 2556493994 P10_BalSwCell132 "电池包10的电芯132均衡状态";
CM_ SG_ 2556559530 P10_CellVoltage133 "电池包10的单体电压133";
CM_ SG_ 2556559530 P10_CellVoltage134 "电池包10的单体电压134";
CM_ SG_ 2556559530 P10_CellVoltage135 "电池包10的单体电压135";
CM_ SG_ 2556559530 P10_CellVoltage136 "电池包10的单体电压136";
CM_ SG_ 2556559530 P10_BalSwCell133 "电池包10的电芯133均衡状态";
CM_ SG_ 2556559530 P10_BalSwCell134 "电池包10的电芯134均衡状态";
CM_ SG_ 2556559530 P10_BalSwCell135 "电池包10的电芯135均衡状态";
CM_ SG_ 2556559530 P10_BalSwCell136 "电池包10的电芯136均衡状态";
CM_ SG_ 2556625066 P10_CellVoltage137 "电池包10的单体电压137";
CM_ SG_ 2556625066 P10_CellVoltage138 "电池包10的单体电压138";
CM_ SG_ 2556625066 P10_CellVoltage139 "电池包10的单体电压139";
CM_ SG_ 2556625066 P10_CellVoltage140 "电池包10的单体电压140";
CM_ SG_ 2556625066 P10_BalSwCell137 "电池包10的电芯137均衡状态";
CM_ SG_ 2556625066 P10_BalSwCell138 "电池包10的电芯138均衡状态";
CM_ SG_ 2556625066 P10_BalSwCell139 "电池包10的电芯139均衡状态";
CM_ SG_ 2556625066 P10_BalSwCell140 "电池包10的电芯140均衡状态";
CM_ SG_ 2556690602 P10_CellVoltage141 "电池包10的单体电压141";
CM_ SG_ 2556690602 P10_CellVoltage142 "电池包10的单体电压142";
CM_ SG_ 2556690602 P10_CellVoltage143 "电池包10的单体电压143";
CM_ SG_ 2556690602 P10_CellVoltage144 "电池包10的单体电压144";
CM_ SG_ 2556690602 P10_BalSwCell141 "电池包10的电芯141均衡状态";
CM_ SG_ 2556690602 P10_BalSwCell142 "电池包10的电芯142均衡状态";
CM_ SG_ 2556690602 P10_BalSwCell143 "电池包10的电芯143均衡状态";
CM_ SG_ 2556690602 P10_BalSwCell144 "电池包10的电芯144均衡状态";
CM_ SG_ 2556756138 P10_CellVoltage145 "电池包10的单体电压145";
CM_ SG_ 2556756138 P10_CellVoltage146 "电池包10的单体电压146";
CM_ SG_ 2556756138 P10_CellVoltage147 "电池包10的单体电压147";
CM_ SG_ 2556756138 P10_CellVoltage148 "电池包10的单体电压148";
CM_ SG_ 2556756138 P10_BalSwCell145 "电池包10的电芯145均衡状态";
CM_ SG_ 2556756138 P10_BalSwCell146 "电池包10的电芯146均衡状态";
CM_ SG_ 2556756138 P10_BalSwCell147 "电池包10的电芯147均衡状态";
CM_ SG_ 2556756138 P10_BalSwCell148 "电池包10的电芯148均衡状态";
CM_ SG_ 2556821674 P10_CellVoltage149 "电池包10的单体电压149";
CM_ SG_ 2556821674 P10_CellVoltage150 "电池包10的单体电压150";
CM_ SG_ 2556821674 P10_CellVoltage151 "电池包10的单体电压151";
CM_ SG_ 2556821674 P10_CellVoltage152 "电池包10的单体电压152";
CM_ SG_ 2556821674 P10_BalSwCell149 "电池包10的电芯149均衡状态";
CM_ SG_ 2556821674 P10_BalSwCell150 "电池包10的电芯150均衡状态";
CM_ SG_ 2556821674 P10_BalSwCell151 "电池包10的电芯151均衡状态";
CM_ SG_ 2556821674 P10_BalSwCell152 "电池包10的电芯152均衡状态";
CM_ SG_ 2556887210 P10_CellVoltage153 "电池包10的单体电压153";
CM_ SG_ 2556887210 P10_CellVoltage154 "电池包10的单体电压154";
CM_ SG_ 2556887210 P10_CellVoltage155 "电池包10的单体电压155";
CM_ SG_ 2556887210 P10_CellVoltage156 "电池包10的单体电压156";
CM_ SG_ 2556887210 P10_BalSwCell153 "电池包10的电芯153均衡状态";
CM_ SG_ 2556887210 P10_BalSwCell154 "电池包10的电芯154均衡状态";
CM_ SG_ 2556887210 P10_BalSwCell155 "电池包10的电芯155均衡状态";
CM_ SG_ 2556887210 P10_BalSwCell156 "电池包10的电芯156均衡状态";
CM_ SG_ 2556952746 P10_CellVoltage157 "电池包10的单体电压157";
CM_ SG_ 2556952746 P10_CellVoltage158 "电池包10的单体电压158";
CM_ SG_ 2556952746 P10_CellVoltage159 "电池包10的单体电压159";
CM_ SG_ 2556952746 P10_CellVoltage160 "电池包10的单体电压160";
CM_ SG_ 2556952746 P10_BalSwCell157 "电池包10的电芯157均衡状态";
CM_ SG_ 2556952746 P10_BalSwCell158 "电池包10的电芯158均衡状态";
CM_ SG_ 2556952746 P10_BalSwCell159 "电池包10的电芯159均衡状态";
CM_ SG_ 2556952746 P10_BalSwCell160 "电池包10的电芯160均衡状态";
CM_ SG_ 2557018282 P10_CellVoltage161 "电池包10的单体电压161";
CM_ SG_ 2557018282 P10_CellVoltage162 "电池包10的单体电压162";
CM_ SG_ 2557018282 P10_CellVoltage163 "电池包10的单体电压163";
CM_ SG_ 2557018282 P10_CellVoltage164 "电池包10的单体电压164";
CM_ SG_ 2557018282 P10_BalSwCell161 "电池包10的电芯161均衡状态";
CM_ SG_ 2557018282 P10_BalSwCell162 "电池包10的电芯162均衡状态";
CM_ SG_ 2557018282 P10_BalSwCell163 "电池包10的电芯163均衡状态";
CM_ SG_ 2557018282 P10_BalSwCell164 "电池包10的电芯164均衡状态";
CM_ SG_ 2557083818 P10_CellVoltage165 "电池包10的单体电压165";
CM_ SG_ 2557083818 P10_CellVoltage166 "电池包10的单体电压166";
CM_ SG_ 2557083818 P10_CellVoltage167 "电池包10的单体电压167";
CM_ SG_ 2557083818 P10_CellVoltage168 "电池包10的单体电压168";
CM_ SG_ 2557083818 P10_BalSwCell165 "电池包10的电芯165均衡状态";
CM_ SG_ 2557083818 P10_BalSwCell166 "电池包10的电芯166均衡状态";
CM_ SG_ 2557083818 P10_BalSwCell167 "电池包10的电芯167均衡状态";
CM_ SG_ 2557083818 P10_BalSwCell168 "电池包10的电芯168均衡状态";
CM_ SG_ 2557149354 P10_CellVoltage169 "电池包10的单体电压169";
CM_ SG_ 2557149354 P10_CellVoltage170 "电池包10的单体电压170";
CM_ SG_ 2557149354 P10_CellVoltage171 "电池包10的单体电压171";
CM_ SG_ 2557149354 P10_CellVoltage172 "电池包10的单体电压172";
CM_ SG_ 2557149354 P10_BalSwCell169 "电池包10的电芯169均衡状态";
CM_ SG_ 2557149354 P10_BalSwCell170 "电池包10的电芯170均衡状态";
CM_ SG_ 2557149354 P10_BalSwCell171 "电池包10的电芯171均衡状态";
CM_ SG_ 2557149354 P10_BalSwCell172 "电池包10的电芯172均衡状态";
CM_ SG_ 2557214890 P10_CellVoltage173 "电池包10的单体电压173";
CM_ SG_ 2557214890 P10_CellVoltage174 "电池包10的单体电压174";
CM_ SG_ 2557214890 P10_CellVoltage175 "电池包10的单体电压175";
CM_ SG_ 2557214890 P10_CellVoltage176 "电池包10的单体电压176";
CM_ SG_ 2557214890 P10_BalSwCell173 "电池包10的电芯173均衡状态";
CM_ SG_ 2557214890 P10_BalSwCell174 "电池包10的电芯174均衡状态";
CM_ SG_ 2557214890 P10_BalSwCell175 "电池包10的电芯175均衡状态";
CM_ SG_ 2557214890 P10_BalSwCell176 "电池包10的电芯176均衡状态";
CM_ SG_ 2557280426 P10_CellVoltage177 "电池包10的单体电压177";
CM_ SG_ 2557280426 P10_CellVoltage178 "电池包10的单体电压178";
CM_ SG_ 2557280426 P10_CellVoltage179 "电池包10的单体电压179";
CM_ SG_ 2557280426 P10_CellVoltage180 "电池包10的单体电压180";
CM_ SG_ 2557280426 P10_BalSwCell177 "电池包10的电芯177均衡状态";
CM_ SG_ 2557280426 P10_BalSwCell178 "电池包10的电芯178均衡状态";
CM_ SG_ 2557280426 P10_BalSwCell179 "电池包10的电芯179均衡状态";
CM_ SG_ 2557280426 P10_BalSwCell180 "电池包10的电芯180均衡状态";
CM_ SG_ 2557345962 P10_CellVoltage181 "电池包10的单体电压181";
CM_ SG_ 2557345962 P10_CellVoltage182 "电池包10的单体电压182";
CM_ SG_ 2557345962 P10_CellVoltage183 "电池包10的单体电压183";
CM_ SG_ 2557345962 P10_CellVoltage184 "电池包10的单体电压184";
CM_ SG_ 2557345962 P10_BalSwCell181 "电池包10的电芯181均衡状态";
CM_ SG_ 2557345962 P10_BalSwCell182 "电池包10的电芯182均衡状态";
CM_ SG_ 2557345962 P10_BalSwCell183 "电池包10的电芯183均衡状态";
CM_ SG_ 2557345962 P10_BalSwCell184 "电池包10的电芯184均衡状态";
CM_ SG_ 2557411498 P10_CellVoltage185 "电池包10的单体电压185";
CM_ SG_ 2557411498 P10_CellVoltage186 "电池包10的单体电压186";
CM_ SG_ 2557411498 P10_CellVoltage187 "电池包10的单体电压187";
CM_ SG_ 2557411498 P10_CellVoltage188 "电池包10的单体电压188";
CM_ SG_ 2557411498 P10_BalSwCell185 "电池包10的电芯185均衡状态";
CM_ SG_ 2557411498 P10_BalSwCell186 "电池包10的电芯186均衡状态";
CM_ SG_ 2557411498 P10_BalSwCell187 "电池包10的电芯187均衡状态";
CM_ SG_ 2557411498 P10_BalSwCell188 "电池包10的电芯188均衡状态";
CM_ SG_ 2557477034 P10_CellVoltage189 "电池包10的单体电压189";
CM_ SG_ 2557477034 P10_CellVoltage190 "电池包10的单体电压190";
CM_ SG_ 2557477034 P10_CellVoltage191 "电池包10的单体电压191";
CM_ SG_ 2557477034 P10_CellVoltage192 "电池包10的单体电压192";
CM_ SG_ 2557477034 P10_BalSwCell189 "电池包10的电芯189均衡状态";
CM_ SG_ 2557477034 P10_BalSwCell190 "电池包10的电芯190均衡状态";
CM_ SG_ 2557477034 P10_BalSwCell191 "电池包10的电芯191均衡状态";
CM_ SG_ 2557477034 P10_BalSwCell192 "电池包10的电芯192均衡状态";
CM_ SG_ 2558525610 P10_CellTemp1 "电池包10的单体温度1";
CM_ SG_ 2558525610 P10_CellTemp2 "电池包10的单体温度2";
CM_ SG_ 2558525610 P10_CellTemp3 "电池包10的单体温度3";
CM_ SG_ 2558525610 P10_CellTemp4 "电池包10的单体温度4";
CM_ SG_ 2558525610 P10_CellTemp5 "电池包10的单体温度5";
CM_ SG_ 2558591146 P10_CellTemp6 "电池包10的单体温度6";
CM_ SG_ 2558591146 P10_CellTemp7 "电池包10的单体温度7";
CM_ SG_ 2558591146 P10_CellTemp8 "电池包10的单体温度8";
CM_ SG_ 2558591146 P10_CellTemp9 "电池包10的单体温度9";
CM_ SG_ 2558591146 P10_CellTemp10 "电池包10的单体温度10";
CM_ SG_ 2558656682 P10_CellTemp11 "电池包10的单体温度11";
CM_ SG_ 2558656682 P10_CellTemp12 "电池包10的单体温度12";
CM_ SG_ 2558656682 P10_CellTemp13 "电池包10的单体温度13";
CM_ SG_ 2558656682 P10_CellTemp14 "电池包10的单体温度14";
CM_ SG_ 2558656682 P10_CellTemp15 "电池包10的单体温度15";
CM_ SG_ 2558722218 P10_CellTemp16 "电池包10的单体温度16";
CM_ SG_ 2558722218 P10_CellTemp17 "电池包10的单体温度17";
CM_ SG_ 2558722218 P10_CellTemp18 "电池包10的单体温度18";
CM_ SG_ 2558722218 P10_CellTemp19 "电池包10的单体温度19";
CM_ SG_ 2558722218 P10_CellTemp20 "电池包10的单体温度20";
CM_ SG_ 2558787754 P10_CellTemp21 "电池包10的单体温度21";
CM_ SG_ 2558787754 P10_CellTemp22 "电池包10的单体温度22";
CM_ SG_ 2558787754 P10_CellTemp23 "电池包10的单体温度23";
CM_ SG_ 2558787754 P10_CellTemp24 "电池包10的单体温度24";
CM_ SG_ 2558787754 P10_CellTemp25 "电池包10的单体温度25";
CM_ SG_ 2558853290 P10_CellTemp26 "电池包10的单体温度26";
CM_ SG_ 2558853290 P10_CellTemp27 "电池包10的单体温度27";
CM_ SG_ 2558853290 P10_CellTemp28 "电池包10的单体温度28";
CM_ SG_ 2558853290 P10_CellTemp29 "电池包10的单体温度29";
CM_ SG_ 2558853290 P10_CellTemp30 "电池包10的单体温度30";
CM_ SG_ 2558918826 P10_CellTemp31 "电池包10的单体温度31";
CM_ SG_ 2558918826 P10_CellTemp32 "电池包10的单体温度32";
CM_ SG_ 2558918826 P10_CellTemp33 "电池包10的单体温度33";
CM_ SG_ 2558918826 P10_CellTemp34 "电池包10的单体温度34";
CM_ SG_ 2558918826 P10_CellTemp35 "电池包10的单体温度35";
CM_ SG_ 2558984362 P10_CellTemp36 "电池包10的单体温度36";
CM_ SG_ 2558984362 P10_CellTemp37 "电池包10的单体温度37";
CM_ SG_ 2558984362 P10_CellTemp38 "电池包10的单体温度38";
CM_ SG_ 2558984362 P10_CellTemp39 "电池包10的单体温度39";
CM_ SG_ 2558984362 P10_CellTemp40 "电池包10的单体温度40";
CM_ SG_ 2559049898 P10_CellTemp41 "电池包10的单体温度41";
CM_ SG_ 2559049898 P10_CellTemp42 "电池包10的单体温度42";
CM_ SG_ 2559049898 P10_CellTemp43 "电池包10的单体温度43";
CM_ SG_ 2559049898 P10_CellTemp44 "电池包10的单体温度44";
CM_ SG_ 2559049898 P10_CellTemp45 "电池包10的单体温度45";
CM_ SG_ 2559115434 P10_CellTemp46 "电池包10的单体温度46";
CM_ SG_ 2559115434 P10_CellTemp47 "电池包10的单体温度47";
CM_ SG_ 2559115434 P10_CellTemp48 "电池包10的单体温度48";
CM_ SG_ 2559115434 P10_CellTemp49 "电池包10的单体温度49";
CM_ SG_ 2559115434 P10_CellTemp50 "电池包10的单体温度50";
CM_ SG_ 2559180970 P10_CellTemp51 "电池包10的单体温度51";
CM_ SG_ 2559180970 P10_CellTemp52 "电池包10的单体温度52";
CM_ SG_ 2559180970 P10_CellTemp53 "电池包10的单体温度53";
CM_ SG_ 2559180970 P10_CellTemp54 "电池包10的单体温度54";
CM_ SG_ 2559180970 P10_CellTemp55 "电池包10的单体温度55";
CM_ SG_ 2559246506 P10_CellTemp56 "电池包10的单体温度56";
CM_ SG_ 2559246506 P10_CellTemp57 "电池包10的单体温度57";
CM_ SG_ 2559246506 P10_CellTemp58 "电池包10的单体温度58";
CM_ SG_ 2559246506 P10_CellTemp59 "电池包10的单体温度59";
CM_ SG_ 2559246506 P10_CellTemp60 "电池包10的单体温度60";
CM_ SG_ 2559312042 P10_CellTemp61 "电池包10的单体温度61";
CM_ SG_ 2559312042 P10_CellTemp62 "电池包10的单体温度62";
CM_ SG_ 2559312042 P10_CellTemp63 "电池包10的单体温度63";
CM_ SG_ 2559312042 P10_CellTemp64 "电池包10的单体温度64";
CM_ SG_ 2559312042 P10_CellTemp65 "电池包10的单体温度65";
CM_ SG_ 2559377578 P10_CellTemp66 "电池包10的单体温度66";
CM_ SG_ 2559377578 P10_CellTemp67 "电池包10的单体温度67";
CM_ SG_ 2559377578 P10_CellTemp68 "电池包10的单体温度68";
CM_ SG_ 2559377578 P10_CellTemp69 "电池包10的单体温度69";
CM_ SG_ 2559377578 P10_CellTemp70 "电池包10的单体温度70";
CM_ SG_ 2559443114 P10_CellTemp71 "电池包10的单体温度71";
CM_ SG_ 2559443114 P10_CellTemp72 "电池包10的单体温度72";
CM_ SG_ 2559443114 P10_CellTemp73 "电池包10的单体温度73";
CM_ SG_ 2559443114 P10_CellTemp74 "电池包10的单体温度74";
CM_ SG_ 2559443114 P10_CellTemp75 "电池包10的单体温度75";
CM_ SG_ 2559508650 P10_CellTemp76 "电池包10的单体温度76";
CM_ SG_ 2559508650 P10_CellTemp77 "电池包10的单体温度77";
CM_ SG_ 2559508650 P10_CellTemp78 "电池包10的单体温度78";
CM_ SG_ 2559508650 P10_CellTemp79 "电池包10的单体温度79";
CM_ SG_ 2559508650 P10_CellTemp80 "电池包10的单体温度80";
CM_ SG_ 2559574186 P10_CellTemp81 "电池包10的单体温度81";
CM_ SG_ 2559574186 P10_CellTemp82 "电池包10的单体温度82";
CM_ SG_ 2559574186 P10_CellTemp83 "电池包10的单体温度83";
CM_ SG_ 2559574186 P10_CellTemp84 "电池包10的单体温度84";
CM_ SG_ 2559574186 P10_CellTemp85 "电池包10的单体温度85";
CM_ SG_ 2559639722 P10_CellTemp86 "电池包10的单体温度86";
CM_ SG_ 2559639722 P10_CellTemp87 "电池包10的单体温度87";
CM_ SG_ 2559639722 P10_CellTemp88 "电池包10的单体温度88";
CM_ SG_ 2559639722 P10_CellTemp89 "电池包10的单体温度89";
CM_ SG_ 2559639722 P10_CellTemp90 "电池包10的单体温度90";
CM_ SG_ 2559705258 P10_CellTemp91 "电池包10的单体温度91";
CM_ SG_ 2559705258 P10_CellTemp92 "电池包10的单体温度92";
CM_ SG_ 2559705258 P10_CellTemp93 "电池包10的单体温度93";
CM_ SG_ 2559705258 P10_CellTemp94 "电池包10的单体温度94";
CM_ SG_ 2559705258 P10_CellTemp95 "电池包10的单体温度95";
CM_ SG_ 2559770794 P10_CellTemp96 "电池包10的单体温度96";
CM_ SG_ 2559770794 P10_CellTemp97 "电池包10的单体温度97";
CM_ SG_ 2559770794 P10_CellTemp98 "电池包10的单体温度98";
CM_ SG_ 2559770794 P10_CellTemp99 "电池包10的单体温度99";
CM_ SG_ 2559770794 P10_CellTemp100 "电池包10的单体温度100";
CM_ SG_ 2559836330 P10_CellTemp101 "电池包10的单体温度101";
CM_ SG_ 2559836330 P10_CellTemp102 "电池包10的单体温度102";
CM_ SG_ 2559836330 P10_CellTemp103 "电池包10的单体温度103";
CM_ SG_ 2559836330 P10_CellTemp104 "电池包10的单体温度104";
CM_ SG_ 2559836330 P10_CellTemp105 "电池包10的单体温度105";
CM_ SG_ 2559901866 P10_CellTemp106 "电池包10的单体温度106";
CM_ SG_ 2559901866 P10_CellTemp107 "电池包10的单体温度107";
CM_ SG_ 2559901866 P10_CellTemp108 "电池包10的单体温度108";
CM_ SG_ 2559901866 P10_CellTemp109 "电池包10的单体温度109";
CM_ SG_ 2559901866 P10_CellTemp110 "电池包10的单体温度110";
CM_ SG_ 2559967402 P10_CellTemp111 "电池包10的单体温度111";
CM_ SG_ 2559967402 P10_CellTemp112 "电池包10的单体温度112";
CM_ SG_ 2559967402 P10_CellTemp113 "电池包10的单体温度113";
CM_ SG_ 2559967402 P10_CellTemp114 "电池包10的单体温度114";
CM_ SG_ 2559967402 P10_CellTemp115 "电池包10的单体温度115";
CM_ SG_ 2560032938 P10_CellTemp116 "电池包10的单体温度116";
CM_ SG_ 2560032938 P10_CellTemp117 "电池包10的单体温度117";
CM_ SG_ 2560032938 P10_CellTemp118 "电池包10的单体温度118";
CM_ SG_ 2560032938 P10_CellTemp119 "电池包10的单体温度119";
CM_ SG_ 2560032938 P10_CellTemp120 "电池包10的单体温度120";
CM_ SG_ 2560098474 P10_CellTemp121 "电池包10的单体温度121";
CM_ SG_ 2560098474 P10_CellTemp122 "电池包10的单体温度122";
CM_ SG_ 2560098474 P10_CellTemp123 "电池包10的单体温度123";
CM_ SG_ 2560098474 P10_CellTemp124 "电池包10的单体温度124";
CM_ SG_ 2560098474 P10_CellTemp125 "电池包10的单体温度125";
CM_ SG_ 2560164010 P10_CellTemp126 "电池包10的单体温度126";
CM_ SG_ 2560164010 P10_CellTemp127 "电池包10的单体温度127";
CM_ SG_ 2560164010 P10_CellTemp128 "电池包10的单体温度128";
CM_ SG_ 2560164010 P10_CellTemp129 "电池包10的单体温度129";
CM_ SG_ 2560164010 P10_CellTemp130 "电池包10的单体温度130";
CM_ SG_ 2560229546 P10_CellTemp131 "电池包10的单体温度131";
CM_ SG_ 2560229546 P10_CellTemp132 "电池包10的单体温度132";
CM_ SG_ 2560229546 P10_CellTemp133 "电池包10的单体温度133";
CM_ SG_ 2560229546 P10_CellTemp134 "电池包10的单体温度134";
CM_ SG_ 2560229546 P10_CellTemp135 "电池包10的单体温度135";
CM_ SG_ 2560295082 P10_CellTemp136 "电池包10的单体温度136";
CM_ SG_ 2560295082 P10_CellTemp137 "电池包10的单体温度137";
CM_ SG_ 2560295082 P10_CellTemp138 "电池包10的单体温度138";
CM_ SG_ 2560295082 P10_CellTemp139 "电池包10的单体温度139";
CM_ SG_ 2560295082 P10_CellTemp140 "电池包10的单体温度140";
CM_ SG_ 2560360618 P10_CellTemp141 "电池包10的单体温度141";
CM_ SG_ 2560360618 P10_CellTemp142 "电池包10的单体温度142";
CM_ SG_ 2560360618 P10_CellTemp143 "电池包10的单体温度143";
CM_ SG_ 2560360618 P10_CellTemp144 "电池包10的单体温度144";
CM_ SG_ 2560360618 P10_CellTemp145 "电池包10的单体温度145";
CM_ SG_ 2560426154 P10_CellTemp146 "电池包10的单体温度146";
CM_ SG_ 2560426154 P10_CellTemp147 "电池包10的单体温度147";
CM_ SG_ 2560426154 P10_CellTemp148 "电池包10的单体温度148";
CM_ SG_ 2560426154 P10_CellTemp149 "电池包10的单体温度149";
CM_ SG_ 2560426154 P10_CellTemp150 "电池包10的单体温度150";
CM_ SG_ 2560491690 P10_CellTemp151 "电池包10的单体温度151";
CM_ SG_ 2560491690 P10_CellTemp152 "电池包10的单体温度152";
CM_ SG_ 2560491690 P10_CellTemp153 "电池包10的单体温度153";
CM_ SG_ 2560491690 P10_CellTemp154 "电池包10的单体温度154";
CM_ SG_ 2560491690 P10_CellTemp155 "电池包10的单体温度155";
CM_ SG_ 2560557226 P10_CellTemp156 "电池包10的单体温度156";
CM_ SG_ 2560557226 P10_CellTemp157 "电池包10的单体温度157";
CM_ SG_ 2560557226 P10_CellTemp158 "电池包10的单体温度158";
CM_ SG_ 2560557226 P10_CellTemp159 "电池包10的单体温度159";
CM_ SG_ 2560557226 P10_CellTemp160 "电池包10的单体温度160";
CM_ SG_ 2560622762 P10_CellTemp161 "电池包10的单体温度161";
CM_ SG_ 2560622762 P10_CellTemp162 "电池包10的单体温度162";
CM_ SG_ 2560622762 P10_CellTemp163 "电池包10的单体温度163";
CM_ SG_ 2560622762 P10_CellTemp164 "电池包10的单体温度164";
CM_ SG_ 2560622762 P10_CellTemp165 "电池包10的单体温度165";
CM_ SG_ 2560688298 P10_CellTemp166 "电池包10的单体温度166";
CM_ SG_ 2560688298 P10_CellTemp167 "电池包10的单体温度167";
CM_ SG_ 2560688298 P10_CellTemp168 "电池包10的单体温度168";
CM_ SG_ 2560688298 P10_CellTemp169 "电池包10的单体温度169";
CM_ SG_ 2560688298 P10_CellTemp170 "电池包10的单体温度170";
CM_ SG_ 2560753834 P10_CellTemp171 "电池包10的单体温度171";
CM_ SG_ 2560753834 P10_CellTemp172 "电池包10的单体温度172";
CM_ SG_ 2560753834 P10_CellTemp173 "电池包10的单体温度173";
CM_ SG_ 2560753834 P10_CellTemp174 "电池包10的单体温度174";
CM_ SG_ 2560753834 P10_CellTemp175 "电池包10的单体温度175";
CM_ SG_ 2560819370 P10_CellTemp176 "电池包10的单体温度176";
CM_ SG_ 2560819370 P10_CellTemp177 "电池包10的单体温度177";
CM_ SG_ 2560819370 P10_CellTemp178 "电池包10的单体温度178";
CM_ SG_ 2560819370 P10_CellTemp179 "电池包10的单体温度179";
CM_ SG_ 2560819370 P10_CellTemp180 "电池包10的单体温度180";
CM_ SG_ 2560884906 P10_CellTemp181 "电池包10的单体温度181";
CM_ SG_ 2560884906 P10_CellTemp182 "电池包10的单体温度182";
CM_ SG_ 2560884906 P10_CellTemp183 "电池包10的单体温度183";
CM_ SG_ 2560884906 P10_CellTemp184 "电池包10的单体温度184";
CM_ SG_ 2560884906 P10_CellTemp185 "电池包10的单体温度185";
CM_ SG_ 2560950442 P10_CellTemp186 "电池包10的单体温度186";
CM_ SG_ 2560950442 P10_CellTemp187 "电池包10的单体温度187";
CM_ SG_ 2560950442 P10_CellTemp188 "电池包10的单体温度188";
CM_ SG_ 2560950442 P10_CellTemp189 "电池包10的单体温度189";
CM_ SG_ 2560950442 P10_CellTemp190 "电池包10的单体温度190";
CM_ SG_ 2561015978 P10_CellTemp191 "电池包10的单体温度191";
CM_ SG_ 2561015978 P10_CellTemp192 "电池包10的单体温度192";
CM_ SG_ 2561015978 P10_DatLen16DbgInfo1 "长度为16的调试信息1";
CM_ SG_ 2561015978 P10_DatLen16DbgInfo2 "长度为16的调试信息2";
CM_ SG_ 2561015978 P10_DatLen16DbgInfo3 "长度为16的调试信息3";
CM_ SG_ 2561015978 P10_DatLen16DbgInfo4 "长度为16的调试信息4";
BA_DEF_ BO_  "GenMsgSendType" ENUM  "Cyclic","IfActive","Event";
BA_DEF_ BO_  "GenMsgCycleTime" INT 0 5000;
BA_DEF_ BO_  "VFrameFormat" ENUM  "StandardCAN","ExtendedCAN","reserved","reserved","reserved","reserved","reserved","reserved","reserved","reserved","reserved","reserved","reserved","reserved","StandardCAN_FD","ExtendedCAN_FD";
BA_DEF_ SG_  "GenSigSendType" ENUM  "Cyclic","OnWrite","OnChange","NoSigSendType";
BA_DEF_DEF_  "GenMsgSendType" "Cyclic";
BA_DEF_DEF_  "GenMsgCycleTime" 0;
BA_DEF_DEF_  "GenSigSendType" "Cyclic";
BA_DEF_DEF_  "VFrameFormat" "ExtendedCAN";
BA_ "GenMsgCycleTime" BO_ 2550595737 500;
BA_ "GenMsgCycleTime" BO_ 2550661273 500;
BA_ "GenMsgCycleTime" BO_ 2550726809 500;
BA_ "GenMsgCycleTime" BO_ 2550792345 500;
BA_ "GenMsgCycleTime" BO_ 2550857881 500;
BA_ "GenMsgCycleTime" BO_ 2550923417 500;
BA_ "GenMsgCycleTime" BO_ 2550988953 1000;
BA_ "GenMsgCycleTime" BO_ 2552299673 1000;
BA_ "GenMsgCycleTime" BO_ 2554396825 1000;
BA_ "GenMsgCycleTime" BO_ 2554462361 1000;
BA_ "GenMsgCycleTime" BO_ 2554527897 1000;
BA_ "GenMsgCycleTime" BO_ 2554593433 1000;
BA_ "GenMsgCycleTime" BO_ 2554658969 1000;
BA_ "GenMsgCycleTime" BO_ 2554724505 1000;
BA_ "GenMsgCycleTime" BO_ 2554790041 1000;
BA_ "GenMsgCycleTime" BO_ 2554855577 1000;
BA_ "GenMsgCycleTime" BO_ 2554921113 1000;
BA_ "GenMsgCycleTime" BO_ 2554986649 1000;
BA_ "GenMsgCycleTime" BO_ 2555052185 1000;
BA_ "GenMsgCycleTime" BO_ 2555117721 1000;
BA_ "GenMsgCycleTime" BO_ 2555183257 1000;
BA_ "GenMsgCycleTime" BO_ 2555248793 1000;
BA_ "GenMsgCycleTime" BO_ 2555314329 1000;
BA_ "GenMsgCycleTime" BO_ 2555379865 1000;
BA_ "GenMsgCycleTime" BO_ 2555445401 1000;
BA_ "GenMsgCycleTime" BO_ 2555510937 1000;
BA_ "GenMsgCycleTime" BO_ 2555576473 1000;
BA_ "GenMsgCycleTime" BO_ 2555642009 1000;
BA_ "GenMsgCycleTime" BO_ 2555707545 1000;
BA_ "GenMsgCycleTime" BO_ 2555773081 1000;
BA_ "GenMsgCycleTime" BO_ 2555838617 1000;
BA_ "GenMsgCycleTime" BO_ 2555904153 1000;
BA_ "GenMsgCycleTime" BO_ 2555969689 1000;
BA_ "GenMsgCycleTime" BO_ 2556035225 1000;
BA_ "GenMsgCycleTime" BO_ 2556100761 1000;
BA_ "GenMsgCycleTime" BO_ 2556166297 1000;
BA_ "GenMsgCycleTime" BO_ 2556231833 1000;
BA_ "GenMsgCycleTime" BO_ 2556297369 1000;
BA_ "GenMsgCycleTime" BO_ 2556362905 1000;
BA_ "GenMsgCycleTime" BO_ 2556428441 1000;
BA_ "GenMsgCycleTime" BO_ 2556493977 1000;
BA_ "GenMsgCycleTime" BO_ 2556559513 1000;
BA_ "GenMsgCycleTime" BO_ 2556625049 1000;
BA_ "GenMsgCycleTime" BO_ 2556690585 1000;
BA_ "GenMsgCycleTime" BO_ 2556756121 1000;
BA_ "GenMsgCycleTime" BO_ 2556821657 1000;
BA_ "GenMsgCycleTime" BO_ 2556887193 1000;
BA_ "GenMsgCycleTime" BO_ 2556952729 1000;
BA_ "GenMsgCycleTime" BO_ 2557018265 1000;
BA_ "GenMsgCycleTime" BO_ 2557083801 1000;
BA_ "GenMsgCycleTime" BO_ 2557149337 1000;
BA_ "GenMsgCycleTime" BO_ 2557214873 1000;
BA_ "GenMsgCycleTime" BO_ 2557280409 1000;
BA_ "GenMsgCycleTime" BO_ 2557345945 1000;
BA_ "GenMsgCycleTime" BO_ 2557411481 1000;
BA_ "GenMsgCycleTime" BO_ 2557477017 1000;
BA_ "GenMsgCycleTime" BO_ 2558525593 1000;
BA_ "GenMsgCycleTime" BO_ 2558591129 1000;
BA_ "GenMsgCycleTime" BO_ 2558656665 1000;
BA_ "GenMsgCycleTime" BO_ 2558722201 1000;
BA_ "GenMsgCycleTime" BO_ 2558787737 1000;
BA_ "GenMsgCycleTime" BO_ 2558853273 1000;
BA_ "GenMsgCycleTime" BO_ 2558918809 1000;
BA_ "GenMsgCycleTime" BO_ 2558984345 1000;
BA_ "GenMsgCycleTime" BO_ 2559049881 1000;
BA_ "GenMsgCycleTime" BO_ 2559115417 1000;
BA_ "GenMsgCycleTime" BO_ 2559180953 1000;
BA_ "GenMsgCycleTime" BO_ 2559246489 1000;
BA_ "GenMsgCycleTime" BO_ 2559312025 1000;
BA_ "GenMsgCycleTime" BO_ 2559377561 1000;
BA_ "GenMsgCycleTime" BO_ 2559443097 1000;
BA_ "GenMsgCycleTime" BO_ 2559508633 1000;
BA_ "GenMsgCycleTime" BO_ 2559574169 1000;
BA_ "GenMsgCycleTime" BO_ 2559639705 1000;
BA_ "GenMsgCycleTime" BO_ 2559705241 1000;
BA_ "GenMsgCycleTime" BO_ 2559770777 1000;
BA_ "GenMsgCycleTime" BO_ 2559836313 1000;
BA_ "GenMsgCycleTime" BO_ 2559901849 1000;
BA_ "GenMsgCycleTime" BO_ 2559967385 1000;
BA_ "GenMsgCycleTime" BO_ 2560032921 1000;
BA_ "GenMsgCycleTime" BO_ 2560098457 1000;
BA_ "GenMsgCycleTime" BO_ 2560163993 1000;
BA_ "GenMsgCycleTime" BO_ 2560229529 1000;
BA_ "GenMsgCycleTime" BO_ 2560295065 1000;
BA_ "GenMsgCycleTime" BO_ 2560360601 1000;
BA_ "GenMsgCycleTime" BO_ 2560426137 1000;
BA_ "GenMsgCycleTime" BO_ 2560491673 1000;
BA_ "GenMsgCycleTime" BO_ 2560557209 1000;
BA_ "GenMsgCycleTime" BO_ 2560622745 1000;
BA_ "GenMsgCycleTime" BO_ 2560688281 1000;
BA_ "GenMsgCycleTime" BO_ 2560753817 1000;
BA_ "GenMsgCycleTime" BO_ 2560819353 1000;
BA_ "GenMsgCycleTime" BO_ 2560884889 1000;
BA_ "GenMsgCycleTime" BO_ 2560950425 1000;
BA_ "GenMsgCycleTime" BO_ 2561015961 1000;
BA_ "GenMsgCycleTime" BO_ 2550399146 500;
BA_ "GenMsgCycleTime" BO_ 2550464682 500;
BA_ "GenMsgCycleTime" BO_ 2550530218 500;
BA_ "GenMsgCycleTime" BO_ 2550595754 500;
BA_ "GenMsgCycleTime" BO_ 2550661290 500;
BA_ "GenMsgCycleTime" BO_ 2550726826 500;
BA_ "GenMsgCycleTime" BO_ 2550792362 500;
BA_ "GenMsgCycleTime" BO_ 2550857898 500;
BA_ "GenMsgCycleTime" BO_ 2550923434 500;
BA_ "GenMsgCycleTime" BO_ 2550988970 1000;
BA_ "GenMsgCycleTime" BO_ 2552299690 1000;
BA_ "GenMsgCycleTime" BO_ 2554396842 1000;
BA_ "GenMsgCycleTime" BO_ 2554462378 1000;
BA_ "GenMsgCycleTime" BO_ 2554527914 1000;
BA_ "GenMsgCycleTime" BO_ 2554593450 1000;
BA_ "GenMsgCycleTime" BO_ 2554658986 1000;
BA_ "GenMsgCycleTime" BO_ 2554724522 1000;
BA_ "GenMsgCycleTime" BO_ 2554790058 1000;
BA_ "GenMsgCycleTime" BO_ 2554855594 1000;
BA_ "GenMsgCycleTime" BO_ 2554921130 1000;
BA_ "GenMsgCycleTime" BO_ 2554986666 1000;
BA_ "GenMsgCycleTime" BO_ 2555052202 1000;
BA_ "GenMsgCycleTime" BO_ 2555117738 1000;
BA_ "GenMsgCycleTime" BO_ 2555183274 1000;
BA_ "GenMsgCycleTime" BO_ 2555248810 1000;
BA_ "GenMsgCycleTime" BO_ 2555314346 1000;
BA_ "GenMsgCycleTime" BO_ 2555379882 1000;
BA_ "GenMsgCycleTime" BO_ 2555445418 1000;
BA_ "GenMsgCycleTime" BO_ 2555510954 1000;
BA_ "GenMsgCycleTime" BO_ 2555576490 1000;
BA_ "GenMsgCycleTime" BO_ 2555642026 1000;
BA_ "GenMsgCycleTime" BO_ 2555707562 1000;
BA_ "GenMsgCycleTime" BO_ 2555773098 1000;
BA_ "GenMsgCycleTime" BO_ 2555838634 1000;
BA_ "GenMsgCycleTime" BO_ 2555904170 1000;
BA_ "GenMsgCycleTime" BO_ 2555969706 1000;
BA_ "GenMsgCycleTime" BO_ 2556035242 1000;
BA_ "GenMsgCycleTime" BO_ 2556100778 1000;
BA_ "GenMsgCycleTime" BO_ 2556166314 1000;
BA_ "GenMsgCycleTime" BO_ 2556231850 1000;
BA_ "GenMsgCycleTime" BO_ 2556297386 1000;
BA_ "GenMsgCycleTime" BO_ 2556362922 1000;
BA_ "GenMsgCycleTime" BO_ 2556428458 1000;
BA_ "GenMsgCycleTime" BO_ 2556493994 1000;
BA_ "GenMsgCycleTime" BO_ 2556559530 1000;
BA_ "GenMsgCycleTime" BO_ 2556625066 1000;
BA_ "GenMsgCycleTime" BO_ 2556690602 1000;
BA_ "GenMsgCycleTime" BO_ 2556756138 1000;
BA_ "GenMsgCycleTime" BO_ 2556821674 1000;
BA_ "GenMsgCycleTime" BO_ 2556887210 1000;
BA_ "GenMsgCycleTime" BO_ 2556952746 1000;
BA_ "GenMsgCycleTime" BO_ 2557018282 1000;
BA_ "GenMsgCycleTime" BO_ 2557083818 1000;
BA_ "GenMsgCycleTime" BO_ 2557149354 1000;
BA_ "GenMsgCycleTime" BO_ 2557214890 1000;
BA_ "GenMsgCycleTime" BO_ 2557280426 1000;
BA_ "GenMsgCycleTime" BO_ 2557345962 1000;
BA_ "GenMsgCycleTime" BO_ 2557411498 1000;
BA_ "GenMsgCycleTime" BO_ 2557477034 1000;
BA_ "GenMsgCycleTime" BO_ 2558525610 1000;
BA_ "GenMsgCycleTime" BO_ 2558591146 1000;
BA_ "GenMsgCycleTime" BO_ 2558656682 1000;
BA_ "GenMsgCycleTime" BO_ 2558722218 1000;
BA_ "GenMsgCycleTime" BO_ 2558787754 1000;
BA_ "GenMsgCycleTime" BO_ 2558853290 1000;
BA_ "GenMsgCycleTime" BO_ 2558918826 1000;
BA_ "GenMsgCycleTime" BO_ 2558984362 1000;
BA_ "GenMsgCycleTime" BO_ 2559049898 1000;
BA_ "GenMsgCycleTime" BO_ 2559115434 1000;
BA_ "GenMsgCycleTime" BO_ 2559180970 1000;
BA_ "GenMsgCycleTime" BO_ 2559246506 1000;
BA_ "GenMsgCycleTime" BO_ 2559312042 1000;
BA_ "GenMsgCycleTime" BO_ 2559377578 1000;
BA_ "GenMsgCycleTime" BO_ 2559443114 1000;
BA_ "GenMsgCycleTime" BO_ 2559508650 1000;
BA_ "GenMsgCycleTime" BO_ 2559574186 1000;
BA_ "GenMsgCycleTime" BO_ 2559639722 1000;
BA_ "GenMsgCycleTime" BO_ 2559705258 1000;
BA_ "GenMsgCycleTime" BO_ 2559770794 1000;
BA_ "GenMsgCycleTime" BO_ 2559836330 1000;
BA_ "GenMsgCycleTime" BO_ 2559901866 1000;
BA_ "GenMsgCycleTime" BO_ 2559967402 1000;
BA_ "GenMsgCycleTime" BO_ 2560032938 1000;
BA_ "GenMsgCycleTime" BO_ 2560098474 1000;
BA_ "GenMsgCycleTime" BO_ 2560164010 1000;
BA_ "GenMsgCycleTime" BO_ 2560229546 1000;
BA_ "GenMsgCycleTime" BO_ 2560295082 1000;
BA_ "GenMsgCycleTime" BO_ 2560360618 1000;
BA_ "GenMsgCycleTime" BO_ 2560426154 1000;
BA_ "GenMsgCycleTime" BO_ 2560491690 1000;
BA_ "GenMsgCycleTime" BO_ 2560557226 1000;
BA_ "GenMsgCycleTime" BO_ 2560622762 1000;
BA_ "GenMsgCycleTime" BO_ 2560688298 1000;
BA_ "GenMsgCycleTime" BO_ 2560753834 1000;
BA_ "GenMsgCycleTime" BO_ 2560819370 1000;
BA_ "GenMsgCycleTime" BO_ 2560884906 1000;
BA_ "GenMsgCycleTime" BO_ 2560950442 1000;
BA_ "GenMsgCycleTime" BO_ 2561015978 1000;
VAL_ 2550595737 P9_ChrgrCplrStat 01 "Connected" 00 "Disconnected" ;
VAL_ 2550595737 P9_HVBattChrgSysStatus 04 "Aborted" 03 "Complete" 02 "Active" 01 "Initialization" 00 "Default" ;
VAL_ 2550857881 P9_CellOverVoltage 03 "Level 3" 02 "Level 2" 01 "Level 1" 00 "No Fault" ;
VAL_ 2550857881 P9_CellUnderVoltage 03 "Level 3" 02 "Level 2" 01 "Level 1" 00 "No Fault" ;
VAL_ 2550857881 P9_CellVoltageDiffHi 01 "Fault" 00 "No Fault" ;
VAL_ 2550857881 P9_PackOverVoltage 03 "Level 3" 02 "Level 2" 01 "Level 1" 00 "No Fault" ;
VAL_ 2550857881 P9_PackUnderVoltage 03 "Level 3" 02 "Level 2" 01 "Level 1" 00 "No Fault" ;
VAL_ 2550857881 P9_CellOverTemp 03 "Level 3" 02 "Level 2" 01 "Level 1" 00 "No Fault" ;
VAL_ 2550857881 P9_CellTempLow 01 "Fault" 00 "No Fault" ;
VAL_ 2550857881 P9_CellTempDiffHi 01 "Fault" 00 "No Fault" ;
VAL_ 2550857881 P9_PackDschrgCrntHi 03 "Level 3" 02 "Level 2" 01 "Level 1" 00 "No Fault" ;
VAL_ 2550857881 P9_PackChrgCrntHi 03 "Level 3" 02 "Level 2" 01 "Level 1" 00 "No Fault" ;
VAL_ 2550857881 P9_PackCrnSnsr1OffsetHi 01 "Fault" 00 "No Fault" ;
VAL_ 2550857881 P9_HVIsolFlt 03 "Level 3" 02 "Level 2" 01 "Level 1" 00 "No Fault" ;
VAL_ 2550857881 P9_HVILFlt 01 "Fault" 00 "No Fault" ;
VAL_ 2550857881 P9_ThrmlRunaway 01 "Fault" 00 "No Fault" ;
VAL_ 2550857881 P9_CellVoltInvalid 01 "Fault" 00 "No Fault" ;
VAL_ 2550857881 P9_CellTempInvalid 01 "Fault" 00 "No Fault" ;
VAL_ 2550857881 P9_DaisyChainComFlt 01 "Fault" 00 "No Fault" ;
VAL_ 2550857881 P9_PackVoltRatFlt 01 "Fault" 00 "No Fault" ;
VAL_ 2550857881 P9_CrntSnsr1Invalid 01 "Fault" 00 "No Fault" ;
VAL_ 2550857881 P9_CrntSnsr1OOR 01 "Fault" 00 "No Fault" ;
VAL_ 2550857881 P9_CrntSnsr2Invalid 01 "Fault" 00 "No Fault" ;
VAL_ 2550857881 P9_CrntSnsr2OOR 01 "Fault" 00 "No Fault" ;
VAL_ 2550857881 P9_PackCrnSnsr2OffsetHi 01 "Fault" 00 "No Fault" ;
VAL_ 2550857881 P9_OutofEnergy 01 "Fault" 00 "No Fault" ;
VAL_ 2550857881 P9_IsolDetCircErr 01 "Fault" 00 "No Fault" ;
VAL_ 2550857881 P9_HVILCircShortToGND 01 "Fault" 00 "No Fault" ;
VAL_ 2550857881 P9_HVILCircShortToPwr 01 "Fault" 00 "No Fault" ;
VAL_ 2550923417 P9_MainPosCntctrStkClsd 01 "Fault" 00 "No Fault" ;
VAL_ 2550923417 P9_MainPosCntctrStkOpn 01 "Fault" 00 "No Fault" ;
VAL_ 2550923417 P9_MainNegCntctr1StkClsd 01 "Fault" 00 "No Fault" ;
VAL_ 2550923417 P9_MainNegCntctr1StkOpn 01 "Fault" 00 "No Fault" ;
VAL_ 2550923417 P9_MainNegCntctr2StkClsd 01 "Fault" 00 "No Fault" ;
VAL_ 2550923417 P9_MainNegCntctr2StkOpn 01 "Fault" 00 "No Fault" ;
VAL_ 2550923417 P9_PrechargTmOut 01 "Fault" 00 "No Fault" ;
VAL_ 2550923417 P9_PrechrgCrntHi 01 "Fault" 00 "No Fault" ;
VAL_ 2550923417 P9_ChrgCplrPosTempHi 01 "Fault" 00 "No Fault" ;
VAL_ 2550923417 P9_ChrgCplrNegTempHi 01 "Fault" 00 "No Fault" ;
VAL_ 2550923417 P9_BMSPwrSuplVlt1Hi 01 "Fault" 00 "No Fault" ;
VAL_ 2550923417 P9_BMSPwrSuplVlt1Lo 01 "Fault" 00 "No Fault" ;
VAL_ 2550923417 P9_BMSPwrSuplVlt2Hi 01 "Fault" 00 "No Fault" ;
VAL_ 2550923417 P9_BMSPwrSuplVlt2Lo 01 "Fault" 00 "No Fault" ;
VAL_ 2550923417 P9_CntctrCirPwrSuplVltLo 01 "Fault" 00 "No Fault" ;
VAL_ 2550923417 P9_CntctrCirPwrSuplVltHi 01 "Fault" 00 "No Fault" ;
VAL_ 2550923417 P9_CAN1BusOff 01 "Fault" 00 "No Fault" ;
VAL_ 2550923417 P9_CAN1BusTmOut 01 "Fault" 00 "No Fault" ;
VAL_ 2550923417 P9_CAN2BusOff 01 "Fault" 00 "No Fault" ;
VAL_ 2550923417 P9_CAN2BusTmOut 01 "Fault" 00 "No Fault" ;
VAL_ 2550923417 P9_CellBalCircTempHi 01 "Fault" 00 "No Fault" ;
VAL_ 2550923417 P9_ClntInTempHi 01 "Fault" 00 "No Fault" ;
VAL_ 2550923417 P9_ClntOutTempHi 01 "Fault" 00 "No Fault" ;
VAL_ 2550923417 P9_CellExtrmUdrVolt 01 "Fault" 00 "No Fault" ;
VAL_ 2550923417 P9_CellExtrmOvrVolt 01 "Fault" 00 "No Fault" ;
VAL_ 2550923417 P9_Branch1DischrgCrntHi  01 "Fault" 00 "No Fault" ;
VAL_ 2550923417 P9_Branch2DischrgCrntHi  01 "Fault" 00 "No Fault" ;
VAL_ 2550923417 P9_Branch1ChrgCrntHi  01 "Fault" 00 "No Fault" ;
VAL_ 2550923417 P9_Branch2ChrgCrntHi  01 "Fault" 00 "No Fault" ;
VAL_ 2550923417 P9_InitFailed 01 "Fault" 00 "No Fault" ;
VAL_ 2554396825 P9_BalSwCell1 01 "Active" 00 "Inactive" ;
VAL_ 2554396825 P9_BalSwCell2 01 "Active" 00 "Inactive" ;
VAL_ 2554396825 P9_BalSwCell3 01 "Active" 00 "Inactive" ;
VAL_ 2554396825 P9_BalSwCell4 01 "Active" 00 "Inactive" ;
VAL_ 2554462361 P9_BalSwCell5 01 "Active" 00 "Inactive" ;
VAL_ 2554462361 P9_BalSwCell6 01 "Active" 00 "Inactive" ;
VAL_ 2554462361 P9_BalSwCell7 01 "Active" 00 "Inactive" ;
VAL_ 2554462361 P9_BalSwCell8 01 "Active" 00 "Inactive" ;
VAL_ 2554527897 P9_BalSwCell9 01 "Active" 00 "Inactive" ;
VAL_ 2554527897 P9_BalSwCell10 01 "Active" 00 "Inactive" ;
VAL_ 2554527897 P9_BalSwCell11 01 "Active" 00 "Inactive" ;
VAL_ 2554527897 P9_BalSwCell12 01 "Active" 00 "Inactive" ;
VAL_ 2554593433 P9_BalSwCell13 01 "Active" 00 "Inactive" ;
VAL_ 2554593433 P9_BalSwCell14 01 "Active" 00 "Inactive" ;
VAL_ 2554593433 P9_BalSwCell15 01 "Active" 00 "Inactive" ;
VAL_ 2554593433 P9_BalSwCell16 01 "Active" 00 "Inactive" ;
VAL_ 2554658969 P9_BalSwCell17 01 "Active" 00 "Inactive" ;
VAL_ 2554658969 P9_BalSwCell18 01 "Active" 00 "Inactive" ;
VAL_ 2554658969 P9_BalSwCell19 01 "Active" 00 "Inactive" ;
VAL_ 2554658969 P9_BalSwCell20 01 "Active" 00 "Inactive" ;
VAL_ 2554724505 P9_BalSwCell21 01 "Active" 00 "Inactive" ;
VAL_ 2554724505 P9_BalSwCell22 01 "Active" 00 "Inactive" ;
VAL_ 2554724505 P9_BalSwCell23 01 "Active" 00 "Inactive" ;
VAL_ 2554724505 P9_BalSwCell24 01 "Active" 00 "Inactive" ;
VAL_ 2554790041 P9_BalSwCell25 01 "Active" 00 "Inactive" ;
VAL_ 2554790041 P9_BalSwCell26 01 "Active" 00 "Inactive" ;
VAL_ 2554790041 P9_BalSwCell27 01 "Active" 00 "Inactive" ;
VAL_ 2554790041 P9_BalSwCell28 01 "Active" 00 "Inactive" ;
VAL_ 2554855577 P9_BalSwCell29 01 "Active" 00 "Inactive" ;
VAL_ 2554855577 P9_BalSwCell30 01 "Active" 00 "Inactive" ;
VAL_ 2554855577 P9_BalSwCell31 01 "Active" 00 "Inactive" ;
VAL_ 2554855577 P9_BalSwCell32 01 "Active" 00 "Inactive" ;
VAL_ 2554921113 P9_BalSwCell33 01 "Active" 00 "Inactive" ;
VAL_ 2554921113 P9_BalSwCell34 01 "Active" 00 "Inactive" ;
VAL_ 2554921113 P9_BalSwCell35 01 "Active" 00 "Inactive" ;
VAL_ 2554921113 P9_BalSwCell36 01 "Active" 00 "Inactive" ;
VAL_ 2554986649 P9_BalSwCell37 01 "Active" 00 "Inactive" ;
VAL_ 2554986649 P9_BalSwCell38 01 "Active" 00 "Inactive" ;
VAL_ 2554986649 P9_BalSwCell39 01 "Active" 00 "Inactive" ;
VAL_ 2554986649 P9_BalSwCell40 01 "Active" 00 "Inactive" ;
VAL_ 2555052185 P9_BalSwCell41 01 "Active" 00 "Inactive" ;
VAL_ 2555052185 P9_BalSwCell42 01 "Active" 00 "Inactive" ;
VAL_ 2555052185 P9_BalSwCell43 01 "Active" 00 "Inactive" ;
VAL_ 2555052185 P9_BalSwCell44 01 "Active" 00 "Inactive" ;
VAL_ 2555117721 P9_BalSwCell45 01 "Active" 00 "Inactive" ;
VAL_ 2555117721 P9_BalSwCell46 01 "Active" 00 "Inactive" ;
VAL_ 2555117721 P9_BalSwCell47 01 "Active" 00 "Inactive" ;
VAL_ 2555117721 P9_BalSwCell48 01 "Active" 00 "Inactive" ;
VAL_ 2555183257 P9_BalSwCell49 01 "Active" 00 "Inactive" ;
VAL_ 2555183257 P9_BalSwCell50 01 "Active" 00 "Inactive" ;
VAL_ 2555183257 P9_BalSwCell51 01 "Active" 00 "Inactive" ;
VAL_ 2555183257 P9_BalSwCell52 01 "Active" 00 "Inactive" ;
VAL_ 2555248793 P9_BalSwCell53 01 "Active" 00 "Inactive" ;
VAL_ 2555248793 P9_BalSwCell54 01 "Active" 00 "Inactive" ;
VAL_ 2555248793 P9_BalSwCell55 01 "Active" 00 "Inactive" ;
VAL_ 2555248793 P9_BalSwCell56 01 "Active" 00 "Inactive" ;
VAL_ 2555314329 P9_BalSwCell57 01 "Active" 00 "Inactive" ;
VAL_ 2555314329 P9_BalSwCell58 01 "Active" 00 "Inactive" ;
VAL_ 2555314329 P9_BalSwCell59 01 "Active" 00 "Inactive" ;
VAL_ 2555314329 P9_BalSwCell60 01 "Active" 00 "Inactive" ;
VAL_ 2555379865 P9_BalSwCell61 01 "Active" 00 "Inactive" ;
VAL_ 2555379865 P9_BalSwCell62 01 "Active" 00 "Inactive" ;
VAL_ 2555379865 P9_BalSwCell63 01 "Active" 00 "Inactive" ;
VAL_ 2555379865 P9_BalSwCell64 01 "Active" 00 "Inactive" ;
VAL_ 2555445401 P9_BalSwCell65 01 "Active" 00 "Inactive" ;
VAL_ 2555445401 P9_BalSwCell66 01 "Active" 00 "Inactive" ;
VAL_ 2555445401 P9_BalSwCell67 01 "Active" 00 "Inactive" ;
VAL_ 2555445401 P9_BalSwCell68 01 "Active" 00 "Inactive" ;
VAL_ 2555510937 P9_BalSwCell69 01 "Active" 00 "Inactive" ;
VAL_ 2555510937 P9_BalSwCell70 01 "Active" 00 "Inactive" ;
VAL_ 2555510937 P9_BalSwCell71 01 "Active" 00 "Inactive" ;
VAL_ 2555510937 P9_BalSwCell72 01 "Active" 00 "Inactive" ;
VAL_ 2555576473 P9_BalSwCell73 01 "Active" 00 "Inactive" ;
VAL_ 2555576473 P9_BalSwCell74 01 "Active" 00 "Inactive" ;
VAL_ 2555576473 P9_BalSwCell75 01 "Active" 00 "Inactive" ;
VAL_ 2555576473 P9_BalSwCell76 01 "Active" 00 "Inactive" ;
VAL_ 2555642009 P9_BalSwCell77 01 "Active" 00 "Inactive" ;
VAL_ 2555642009 P9_BalSwCell78 01 "Active" 00 "Inactive" ;
VAL_ 2555642009 P9_BalSwCell79 01 "Active" 00 "Inactive" ;
VAL_ 2555642009 P9_BalSwCell80 01 "Active" 00 "Inactive" ;
VAL_ 2555707545 P9_BalSwCell81 01 "Active" 00 "Inactive" ;
VAL_ 2555707545 P9_BalSwCell82 01 "Active" 00 "Inactive" ;
VAL_ 2555707545 P9_BalSwCell83 01 "Active" 00 "Inactive" ;
VAL_ 2555707545 P9_BalSwCell84 01 "Active" 00 "Inactive" ;
VAL_ 2555773081 P9_BalSwCell85 01 "Active" 00 "Inactive" ;
VAL_ 2555773081 P9_BalSwCell86 01 "Active" 00 "Inactive" ;
VAL_ 2555773081 P9_BalSwCell87 01 "Active" 00 "Inactive" ;
VAL_ 2555773081 P9_BalSwCell88 01 "Active" 00 "Inactive" ;
VAL_ 2555838617 P9_BalSwCell89 01 "Active" 00 "Inactive" ;
VAL_ 2555838617 P9_BalSwCell90 01 "Active" 00 "Inactive" ;
VAL_ 2555838617 P9_BalSwCell91 01 "Active" 00 "Inactive" ;
VAL_ 2555838617 P9_BalSwCell92 01 "Active" 00 "Inactive" ;
VAL_ 2555904153 P9_BalSwCell93 01 "Active" 00 "Inactive" ;
VAL_ 2555904153 P9_BalSwCell94 01 "Active" 00 "Inactive" ;
VAL_ 2555904153 P9_BalSwCell95 01 "Active" 00 "Inactive" ;
VAL_ 2555904153 P9_BalSwCell96 01 "Active" 00 "Inactive" ;
VAL_ 2555969689 P9_BalSwCell97 01 "Active" 00 "Inactive" ;
VAL_ 2555969689 P9_BalSwCell98 01 "Active" 00 "Inactive" ;
VAL_ 2555969689 P9_BalSwCell99 01 "Active" 00 "Inactive" ;
VAL_ 2555969689 P9_BalSwCell100 01 "Active" 00 "Inactive" ;
VAL_ 2556035225 P9_BalSwCell101 01 "Active" 00 "Inactive" ;
VAL_ 2556035225 P9_BalSwCell102 01 "Active" 00 "Inactive" ;
VAL_ 2556035225 P9_BalSwCell103 01 "Active" 00 "Inactive" ;
VAL_ 2556035225 P9_BalSwCell104 01 "Active" 00 "Inactive" ;
VAL_ 2556100761 P9_BalSwCell105 01 "Active" 00 "Inactive" ;
VAL_ 2556100761 P9_BalSwCell106 01 "Active" 00 "Inactive" ;
VAL_ 2556100761 P9_BalSwCell107 01 "Active" 00 "Inactive" ;
VAL_ 2556100761 P9_BalSwCell108 01 "Active" 00 "Inactive" ;
VAL_ 2556166297 P9_BalSwCell109 01 "Active" 00 "Inactive" ;
VAL_ 2556166297 P9_BalSwCell110 01 "Active" 00 "Inactive" ;
VAL_ 2556166297 P9_BalSwCell111 01 "Active" 00 "Inactive" ;
VAL_ 2556166297 P9_BalSwCell112 01 "Active" 00 "Inactive" ;
VAL_ 2556231833 P9_BalSwCell113 01 "Active" 00 "Inactive" ;
VAL_ 2556231833 P9_BalSwCell114 01 "Active" 00 "Inactive" ;
VAL_ 2556231833 P9_BalSwCell115 01 "Active" 00 "Inactive" ;
VAL_ 2556231833 P9_BalSwCell116 01 "Active" 00 "Inactive" ;
VAL_ 2556297369 P9_BalSwCell117 01 "Active" 00 "Inactive" ;
VAL_ 2556297369 P9_BalSwCell118 01 "Active" 00 "Inactive" ;
VAL_ 2556297369 P9_BalSwCell119 01 "Active" 00 "Inactive" ;
VAL_ 2556297369 P9_BalSwCell120 01 "Active" 00 "Inactive" ;
VAL_ 2556362905 P9_BalSwCell121 01 "Active" 00 "Inactive" ;
VAL_ 2556362905 P9_BalSwCell122 01 "Active" 00 "Inactive" ;
VAL_ 2556362905 P9_BalSwCell123 01 "Active" 00 "Inactive" ;
VAL_ 2556362905 P9_BalSwCell124 01 "Active" 00 "Inactive" ;
VAL_ 2556428441 P9_BalSwCell125 01 "Active" 00 "Inactive" ;
VAL_ 2556428441 P9_BalSwCell126 01 "Active" 00 "Inactive" ;
VAL_ 2556428441 P9_BalSwCell127 01 "Active" 00 "Inactive" ;
VAL_ 2556428441 P9_BalSwCell128 01 "Active" 00 "Inactive" ;
VAL_ 2556493977 P9_BalSwCell129 01 "Active" 00 "Inactive" ;
VAL_ 2556493977 P9_BalSwCell130 01 "Active" 00 "Inactive" ;
VAL_ 2556493977 P9_BalSwCell131 01 "Active" 00 "Inactive" ;
VAL_ 2556493977 P9_BalSwCell132 01 "Active" 00 "Inactive" ;
VAL_ 2556559513 P9_BalSwCell133 01 "Active" 00 "Inactive" ;
VAL_ 2556559513 P9_BalSwCell134 01 "Active" 00 "Inactive" ;
VAL_ 2556559513 P9_BalSwCell135 01 "Active" 00 "Inactive" ;
VAL_ 2556559513 P9_BalSwCell136 01 "Active" 00 "Inactive" ;
VAL_ 2556625049 P9_BalSwCell137 01 "Active" 00 "Inactive" ;
VAL_ 2556625049 P9_BalSwCell138 01 "Active" 00 "Inactive" ;
VAL_ 2556625049 P9_BalSwCell139 01 "Active" 00 "Inactive" ;
VAL_ 2556625049 P9_BalSwCell140 01 "Active" 00 "Inactive" ;
VAL_ 2556690585 P9_BalSwCell141 01 "Active" 00 "Inactive" ;
VAL_ 2556690585 P9_BalSwCell142 01 "Active" 00 "Inactive" ;
VAL_ 2556690585 P9_BalSwCell143 01 "Active" 00 "Inactive" ;
VAL_ 2556690585 P9_BalSwCell144 01 "Active" 00 "Inactive" ;
VAL_ 2556756121 P9_BalSwCell145 01 "Active" 00 "Inactive" ;
VAL_ 2556756121 P9_BalSwCell146 01 "Active" 00 "Inactive" ;
VAL_ 2556756121 P9_BalSwCell147 01 "Active" 00 "Inactive" ;
VAL_ 2556756121 P9_BalSwCell148 01 "Active" 00 "Inactive" ;
VAL_ 2556821657 P9_BalSwCell149 01 "Active" 00 "Inactive" ;
VAL_ 2556821657 P9_BalSwCell150 01 "Active" 00 "Inactive" ;
VAL_ 2556821657 P9_BalSwCell151 01 "Active" 00 "Inactive" ;
VAL_ 2556821657 P9_BalSwCell152 01 "Active" 00 "Inactive" ;
VAL_ 2556887193 P9_BalSwCell153 01 "Active" 00 "Inactive" ;
VAL_ 2556887193 P9_BalSwCell154 01 "Active" 00 "Inactive" ;
VAL_ 2556887193 P9_BalSwCell155 01 "Active" 00 "Inactive" ;
VAL_ 2556887193 P9_BalSwCell156 01 "Active" 00 "Inactive" ;
VAL_ 2556952729 P9_BalSwCell157 01 "Active" 00 "Inactive" ;
VAL_ 2556952729 P9_BalSwCell158 01 "Active" 00 "Inactive" ;
VAL_ 2556952729 P9_BalSwCell159 01 "Active" 00 "Inactive" ;
VAL_ 2556952729 P9_BalSwCell160 01 "Active" 00 "Inactive" ;
VAL_ 2557018265 P9_BalSwCell161 01 "Active" 00 "Inactive" ;
VAL_ 2557018265 P9_BalSwCell162 01 "Active" 00 "Inactive" ;
VAL_ 2557018265 P9_BalSwCell163 01 "Active" 00 "Inactive" ;
VAL_ 2557018265 P9_BalSwCell164 01 "Active" 00 "Inactive" ;
VAL_ 2557083801 P9_BalSwCell165 01 "Active" 00 "Inactive" ;
VAL_ 2557083801 P9_BalSwCell166 01 "Active" 00 "Inactive" ;
VAL_ 2557083801 P9_BalSwCell167 01 "Active" 00 "Inactive" ;
VAL_ 2557083801 P9_BalSwCell168 01 "Active" 00 "Inactive" ;
VAL_ 2557149337 P9_BalSwCell169 01 "Active" 00 "Inactive" ;
VAL_ 2557149337 P9_BalSwCell170 01 "Active" 00 "Inactive" ;
VAL_ 2557149337 P9_BalSwCell171 01 "Active" 00 "Inactive" ;
VAL_ 2557149337 P9_BalSwCell172 01 "Active" 00 "Inactive" ;
VAL_ 2557214873 P9_BalSwCell173 01 "Active" 00 "Inactive" ;
VAL_ 2557214873 P9_BalSwCell174 01 "Active" 00 "Inactive" ;
VAL_ 2557214873 P9_BalSwCell175 01 "Active" 00 "Inactive" ;
VAL_ 2557214873 P9_BalSwCell176 01 "Active" 00 "Inactive" ;
VAL_ 2557280409 P9_BalSwCell177 01 "Active" 00 "Inactive" ;
VAL_ 2557280409 P9_BalSwCell178 01 "Active" 00 "Inactive" ;
VAL_ 2557280409 P9_BalSwCell179 01 "Active" 00 "Inactive" ;
VAL_ 2557280409 P9_BalSwCell180 01 "Active" 00 "Inactive" ;
VAL_ 2557345945 P9_BalSwCell181 01 "Active" 00 "Inactive" ;
VAL_ 2557345945 P9_BalSwCell182 01 "Active" 00 "Inactive" ;
VAL_ 2557345945 P9_BalSwCell183 01 "Active" 00 "Inactive" ;
VAL_ 2557345945 P9_BalSwCell184 01 "Active" 00 "Inactive" ;
VAL_ 2557411481 P9_BalSwCell185 01 "Active" 00 "Inactive" ;
VAL_ 2557411481 P9_BalSwCell186 01 "Active" 00 "Inactive" ;
VAL_ 2557411481 P9_BalSwCell187 01 "Active" 00 "Inactive" ;
VAL_ 2557411481 P9_BalSwCell188 01 "Active" 00 "Inactive" ;
VAL_ 2557477017 P9_BalSwCell189 01 "Active" 00 "Inactive" ;
VAL_ 2557477017 P9_BalSwCell190 01 "Active" 00 "Inactive" ;
VAL_ 2557477017 P9_BalSwCell191 01 "Active" 00 "Inactive" ;
VAL_ 2557477017 P9_BalSwCell192 01 "Active" 00 "Inactive" ;
VAL_ 2550399146 P10_BMSKL15ON 01 "On" 00 "Off" ;
VAL_ 2550530218 P10_PackDschrgPwrStat 02 "鎸佺画鏀剧數鍔熺巼" 01 "30s鏀剧數鍔熺巼" 00 "10s鏀剧數鍔熺巼" ;
VAL_ 2550530218 P10_PackChrgPwrStat 02 "鎸佺画鍏呯數鍔熺巼" 01 "30s鍏呯數鍔熺巼" 00 "10s鍏呯數鍔熺巼" ;
VAL_ 2550595754 P10_ChrgrCplrStat 01 "Connected" 00 "Disconnected" ;
VAL_ 2550595754 P10_HVBattChrgSysStatus 04 "Aborted" 03 "Complete" 02 "Active" 01 "Initialization" 00 "Default" ;
VAL_ 2550857898 P10_CellOverVoltage 03 "Level 3" 02 "Level 2" 01 "Level 1" 00 "No Fault" ;
VAL_ 2550857898 P10_CellUnderVoltage 03 "Level 3" 02 "Level 2" 01 "Level 1" 00 "No Fault" ;
VAL_ 2550857898 P10_CellVoltageDiffHi 01 "Fault" 00 "No Fault" ;
VAL_ 2550857898 P10_PackOverVoltage 03 "Level 3" 02 "Level 2" 01 "Level 1" 00 "No Fault" ;
VAL_ 2550857898 P10_PackUnderVoltage 03 "Level 3" 02 "Level 2" 01 "Level 1" 00 "No Fault" ;
VAL_ 2550857898 P10_CellOverTemp 03 "Level 3" 02 "Level 2" 01 "Level 1" 00 "No Fault" ;
VAL_ 2550857898 P10_CellTempLow 01 "Fault" 00 "No Fault" ;
VAL_ 2550857898 P10_CellTempDiffHi 01 "Fault" 00 "No Fault" ;
VAL_ 2550857898 P10_PackDschrgCrntHi 03 "Level 3" 02 "Level 2" 01 "Level 1" 00 "No Fault" ;
VAL_ 2550857898 P10_PackChrgCrntHi 03 "Level 3" 02 "Level 2" 01 "Level 1" 00 "No Fault" ;
VAL_ 2550857898 P10_PackCrnSnsr1OffsetHi 01 "Fault" 00 "No Fault" ;
VAL_ 2550857898 P10_HVIsolFlt 03 "Level 3" 02 "Level 2" 01 "Level 1" 00 "No Fault" ;
VAL_ 2550857898 P10_HVILFlt 01 "Fault" 00 "No Fault" ;
VAL_ 2550857898 P10_ThrmlRunaway 01 "Fault" 00 "No Fault" ;
VAL_ 2550857898 P10_CellVoltInvalid 01 "Fault" 00 "No Fault" ;
VAL_ 2550857898 P10_CellTempInvalid 01 "Fault" 00 "No Fault" ;
VAL_ 2550857898 P10_DaisyChainComFlt 01 "Fault" 00 "No Fault" ;
VAL_ 2550857898 P10_PackVoltRatFlt 01 "Fault" 00 "No Fault" ;
VAL_ 2550857898 P10_CrntSnsr1Invalid 01 "Fault" 00 "No Fault" ;
VAL_ 2550857898 P10_CrntSnsr1OOR 01 "Fault" 00 "No Fault" ;
VAL_ 2550857898 P10_CrntSnsr2Invalid 01 "Fault" 00 "No Fault" ;
VAL_ 2550857898 P10_CrntSnsr2OOR 01 "Fault" 00 "No Fault" ;
VAL_ 2550857898 P10_PackCrnSnsr2OffsetHi 01 "Fault" 00 "No Fault" ;
VAL_ 2550857898 P10_OutofEnergy 01 "Fault" 00 "No Fault" ;
VAL_ 2550857898 P10_IsolDetCircErr 01 "Fault" 00 "No Fault" ;
VAL_ 2550857898 P10_HVILCircShortToGND 01 "Fault" 00 "No Fault" ;
VAL_ 2550857898 P10_HVILCircShortToPwr 01 "Fault" 00 "No Fault" ;
VAL_ 2550923434 P10_MainPosCntctrStkClsd 01 "Fault" 00 "No Fault" ;
VAL_ 2550923434 P10_MainPosCntctrStkOpn 01 "Fault" 00 "No Fault" ;
VAL_ 2550923434 P10_MainNegCntctr1StkClsd 01 "Fault" 00 "No Fault" ;
VAL_ 2550923434 P10_MainNegCntctr1StkOpn 01 "Fault" 00 "No Fault" ;
VAL_ 2550923434 P10_MainNegCntctr2StkClsd 01 "Fault" 00 "No Fault" ;
VAL_ 2550923434 P10_MainNegCntctr2StkOpn 01 "Fault" 00 "No Fault" ;
VAL_ 2550923434 P10_PrechargTmOut 01 "Fault" 00 "No Fault" ;
VAL_ 2550923434 P10_PrechrgCrntHi 01 "Fault" 00 "No Fault" ;
VAL_ 2550923434 P10_ChrgCplrPosTempHi 01 "Fault" 00 "No Fault" ;
VAL_ 2550923434 P10_ChrgCplrNegTempHi 01 "Fault" 00 "No Fault" ;
VAL_ 2550923434 P10_BMSPwrSuplVlt1Hi 01 "Fault" 00 "No Fault" ;
VAL_ 2550923434 P10_BMSPwrSuplVlt1Lo 01 "Fault" 00 "No Fault" ;
VAL_ 2550923434 P10_BMSPwrSuplVlt2Hi 01 "Fault" 00 "No Fault" ;
VAL_ 2550923434 P10_BMSPwrSuplVlt2Lo 01 "Fault" 00 "No Fault" ;
VAL_ 2550923434 P10_CntctrCirPwrSuplVltLo 01 "Fault" 00 "No Fault" ;
VAL_ 2550923434 P10_CntctrCirPwrSuplVltHi 01 "Fault" 00 "No Fault" ;
VAL_ 2550923434 P10_CAN1BusOff 01 "Fault" 00 "No Fault" ;
VAL_ 2550923434 P10_CAN1BusTmOut 01 "Fault" 00 "No Fault" ;
VAL_ 2550923434 P10_CAN2BusOff 01 "Fault" 00 "No Fault" ;
VAL_ 2550923434 P10_CAN2BusTmOut 01 "Fault" 00 "No Fault" ;
VAL_ 2550923434 P10_CellBalCircTempHi 01 "Fault" 00 "No Fault" ;
VAL_ 2550923434 P10_ClntInTempHi 01 "Fault" 00 "No Fault" ;
VAL_ 2550923434 P10_ClntOutTempHi 01 "Fault" 00 "No Fault" ;
VAL_ 2550923434 P10_CellExtrmUdrVolt 01 "Fault" 00 "No Fault" ;
VAL_ 2550923434 P10_CellExtrmOvrVolt 01 "Fault" 00 "No Fault" ;
VAL_ 2550923434 P10_Branch1DischrgCrntHi  01 "Fault" 00 "No Fault" ;
VAL_ 2550923434 P10_Branch2DischrgCrntHi  01 "Fault" 00 "No Fault" ;
VAL_ 2550923434 P10_Branch1ChrgCrntHi  01 "Fault" 00 "No Fault" ;
VAL_ 2550923434 P10_Branch2ChrgCrntHi  01 "Fault" 00 "No Fault" ;
VAL_ 2550923434 P10_InitFailed 01 "Fault" 00 "No Fault" ;
VAL_ 2554396842 P10_BalSwCell1 01 "Active" 00 "Inactive" ;
VAL_ 2554396842 P10_BalSwCell2 01 "Active" 00 "Inactive" ;
VAL_ 2554396842 P10_BalSwCell3 01 "Active" 00 "Inactive" ;
VAL_ 2554396842 P10_BalSwCell4 01 "Active" 00 "Inactive" ;
VAL_ 2554462378 P10_BalSwCell5 01 "Active" 00 "Inactive" ;
VAL_ 2554462378 P10_BalSwCell6 01 "Active" 00 "Inactive" ;
VAL_ 2554462378 P10_BalSwCell7 01 "Active" 00 "Inactive" ;
VAL_ 2554462378 P10_BalSwCell8 01 "Active" 00 "Inactive" ;
VAL_ 2554527914 P10_BalSwCell9 01 "Active" 00 "Inactive" ;
VAL_ 2554527914 P10_BalSwCell10 01 "Active" 00 "Inactive" ;
VAL_ 2554527914 P10_BalSwCell11 01 "Active" 00 "Inactive" ;
VAL_ 2554527914 P10_BalSwCell12 01 "Active" 00 "Inactive" ;
VAL_ 2554593450 P10_BalSwCell13 01 "Active" 00 "Inactive" ;
VAL_ 2554593450 P10_BalSwCell14 01 "Active" 00 "Inactive" ;
VAL_ 2554593450 P10_BalSwCell15 01 "Active" 00 "Inactive" ;
VAL_ 2554593450 P10_BalSwCell16 01 "Active" 00 "Inactive" ;
VAL_ 2554658986 P10_BalSwCell17 01 "Active" 00 "Inactive" ;
VAL_ 2554658986 P10_BalSwCell18 01 "Active" 00 "Inactive" ;
VAL_ 2554658986 P10_BalSwCell19 01 "Active" 00 "Inactive" ;
VAL_ 2554658986 P10_BalSwCell20 01 "Active" 00 "Inactive" ;
VAL_ 2554724522 P10_BalSwCell21 01 "Active" 00 "Inactive" ;
VAL_ 2554724522 P10_BalSwCell22 01 "Active" 00 "Inactive" ;
VAL_ 2554724522 P10_BalSwCell23 01 "Active" 00 "Inactive" ;
VAL_ 2554724522 P10_BalSwCell24 01 "Active" 00 "Inactive" ;
VAL_ 2554790058 P10_BalSwCell25 01 "Active" 00 "Inactive" ;
VAL_ 2554790058 P10_BalSwCell26 01 "Active" 00 "Inactive" ;
VAL_ 2554790058 P10_BalSwCell27 01 "Active" 00 "Inactive" ;
VAL_ 2554790058 P10_BalSwCell28 01 "Active" 00 "Inactive" ;
VAL_ 2554855594 P10_BalSwCell29 01 "Active" 00 "Inactive" ;
VAL_ 2554855594 P10_BalSwCell30 01 "Active" 00 "Inactive" ;
VAL_ 2554855594 P10_BalSwCell31 01 "Active" 00 "Inactive" ;
VAL_ 2554855594 P10_BalSwCell32 01 "Active" 00 "Inactive" ;
VAL_ 2554921130 P10_BalSwCell33 01 "Active" 00 "Inactive" ;
VAL_ 2554921130 P10_BalSwCell34 01 "Active" 00 "Inactive" ;
VAL_ 2554921130 P10_BalSwCell35 01 "Active" 00 "Inactive" ;
VAL_ 2554921130 P10_BalSwCell36 01 "Active" 00 "Inactive" ;
VAL_ 2554986666 P10_BalSwCell37 01 "Active" 00 "Inactive" ;
VAL_ 2554986666 P10_BalSwCell38 01 "Active" 00 "Inactive" ;
VAL_ 2554986666 P10_BalSwCell39 01 "Active" 00 "Inactive" ;
VAL_ 2554986666 P10_BalSwCell40 01 "Active" 00 "Inactive" ;
VAL_ 2555052202 P10_BalSwCell41 01 "Active" 00 "Inactive" ;
VAL_ 2555052202 P10_BalSwCell42 01 "Active" 00 "Inactive" ;
VAL_ 2555052202 P10_BalSwCell43 01 "Active" 00 "Inactive" ;
VAL_ 2555052202 P10_BalSwCell44 01 "Active" 00 "Inactive" ;
VAL_ 2555117738 P10_BalSwCell45 01 "Active" 00 "Inactive" ;
VAL_ 2555117738 P10_BalSwCell46 01 "Active" 00 "Inactive" ;
VAL_ 2555117738 P10_BalSwCell47 01 "Active" 00 "Inactive" ;
VAL_ 2555117738 P10_BalSwCell48 01 "Active" 00 "Inactive" ;
VAL_ 2555183274 P10_BalSwCell49 01 "Active" 00 "Inactive" ;
VAL_ 2555183274 P10_BalSwCell50 01 "Active" 00 "Inactive" ;
VAL_ 2555183274 P10_BalSwCell51 01 "Active" 00 "Inactive" ;
VAL_ 2555183274 P10_BalSwCell52 01 "Active" 00 "Inactive" ;
VAL_ 2555248810 P10_BalSwCell53 01 "Active" 00 "Inactive" ;
VAL_ 2555248810 P10_BalSwCell54 01 "Active" 00 "Inactive" ;
VAL_ 2555248810 P10_BalSwCell55 01 "Active" 00 "Inactive" ;
VAL_ 2555248810 P10_BalSwCell56 01 "Active" 00 "Inactive" ;
VAL_ 2555314346 P10_BalSwCell57 01 "Active" 00 "Inactive" ;
VAL_ 2555314346 P10_BalSwCell58 01 "Active" 00 "Inactive" ;
VAL_ 2555314346 P10_BalSwCell59 01 "Active" 00 "Inactive" ;
VAL_ 2555314346 P10_BalSwCell60 01 "Active" 00 "Inactive" ;
VAL_ 2555379882 P10_BalSwCell61 01 "Active" 00 "Inactive" ;
VAL_ 2555379882 P10_BalSwCell62 01 "Active" 00 "Inactive" ;
VAL_ 2555379882 P10_BalSwCell63 01 "Active" 00 "Inactive" ;
VAL_ 2555379882 P10_BalSwCell64 01 "Active" 00 "Inactive" ;
VAL_ 2555445418 P10_BalSwCell65 01 "Active" 00 "Inactive" ;
VAL_ 2555445418 P10_BalSwCell66 01 "Active" 00 "Inactive" ;
VAL_ 2555445418 P10_BalSwCell67 01 "Active" 00 "Inactive" ;
VAL_ 2555445418 P10_BalSwCell68 01 "Active" 00 "Inactive" ;
VAL_ 2555510954 P10_BalSwCell69 01 "Active" 00 "Inactive" ;
VAL_ 2555510954 P10_BalSwCell70 01 "Active" 00 "Inactive" ;
VAL_ 2555510954 P10_BalSwCell71 01 "Active" 00 "Inactive" ;
VAL_ 2555510954 P10_BalSwCell72 01 "Active" 00 "Inactive" ;
VAL_ 2555576490 P10_BalSwCell73 01 "Active" 00 "Inactive" ;
VAL_ 2555576490 P10_BalSwCell74 01 "Active" 00 "Inactive" ;
VAL_ 2555576490 P10_BalSwCell75 01 "Active" 00 "Inactive" ;
VAL_ 2555576490 P10_BalSwCell76 01 "Active" 00 "Inactive" ;
VAL_ 2555642026 P10_BalSwCell77 01 "Active" 00 "Inactive" ;
VAL_ 2555642026 P10_BalSwCell78 01 "Active" 00 "Inactive" ;
VAL_ 2555642026 P10_BalSwCell79 01 "Active" 00 "Inactive" ;
VAL_ 2555642026 P10_BalSwCell80 01 "Active" 00 "Inactive" ;
VAL_ 2555707562 P10_BalSwCell81 01 "Active" 00 "Inactive" ;
VAL_ 2555707562 P10_BalSwCell82 01 "Active" 00 "Inactive" ;
VAL_ 2555707562 P10_BalSwCell83 01 "Active" 00 "Inactive" ;
VAL_ 2555707562 P10_BalSwCell84 01 "Active" 00 "Inactive" ;
VAL_ 2555773098 P10_BalSwCell85 01 "Active" 00 "Inactive" ;
VAL_ 2555773098 P10_BalSwCell86 01 "Active" 00 "Inactive" ;
VAL_ 2555773098 P10_BalSwCell87 01 "Active" 00 "Inactive" ;
VAL_ 2555773098 P10_BalSwCell88 01 "Active" 00 "Inactive" ;
VAL_ 2555838634 P10_BalSwCell89 01 "Active" 00 "Inactive" ;
VAL_ 2555838634 P10_BalSwCell90 01 "Active" 00 "Inactive" ;
VAL_ 2555838634 P10_BalSwCell91 01 "Active" 00 "Inactive" ;
VAL_ 2555838634 P10_BalSwCell92 01 "Active" 00 "Inactive" ;
VAL_ 2555904170 P10_BalSwCell93 01 "Active" 00 "Inactive" ;
VAL_ 2555904170 P10_BalSwCell94 01 "Active" 00 "Inactive" ;
VAL_ 2555904170 P10_BalSwCell95 01 "Active" 00 "Inactive" ;
VAL_ 2555904170 P10_BalSwCell96 01 "Active" 00 "Inactive" ;
VAL_ 2555969706 P10_BalSwCell97 01 "Active" 00 "Inactive" ;
VAL_ 2555969706 P10_BalSwCell98 01 "Active" 00 "Inactive" ;
VAL_ 2555969706 P10_BalSwCell99 01 "Active" 00 "Inactive" ;
VAL_ 2555969706 P10_BalSwCell100 01 "Active" 00 "Inactive" ;
VAL_ 2556035242 P10_BalSwCell101 01 "Active" 00 "Inactive" ;
VAL_ 2556035242 P10_BalSwCell102 01 "Active" 00 "Inactive" ;
VAL_ 2556035242 P10_BalSwCell103 01 "Active" 00 "Inactive" ;
VAL_ 2556035242 P10_BalSwCell104 01 "Active" 00 "Inactive" ;
VAL_ 2556100778 P10_BalSwCell105 01 "Active" 00 "Inactive" ;
VAL_ 2556100778 P10_BalSwCell106 01 "Active" 00 "Inactive" ;
VAL_ 2556100778 P10_BalSwCell107 01 "Active" 00 "Inactive" ;
VAL_ 2556100778 P10_BalSwCell108 01 "Active" 00 "Inactive" ;
VAL_ 2556166314 P10_BalSwCell109 01 "Active" 00 "Inactive" ;
VAL_ 2556166314 P10_BalSwCell110 01 "Active" 00 "Inactive" ;
VAL_ 2556166314 P10_BalSwCell111 01 "Active" 00 "Inactive" ;
VAL_ 2556166314 P10_BalSwCell112 01 "Active" 00 "Inactive" ;
VAL_ 2556231850 P10_BalSwCell113 01 "Active" 00 "Inactive" ;
VAL_ 2556231850 P10_BalSwCell114 01 "Active" 00 "Inactive" ;
VAL_ 2556231850 P10_BalSwCell115 01 "Active" 00 "Inactive" ;
VAL_ 2556231850 P10_BalSwCell116 01 "Active" 00 "Inactive" ;
VAL_ 2556297386 P10_BalSwCell117 01 "Active" 00 "Inactive" ;
VAL_ 2556297386 P10_BalSwCell118 01 "Active" 00 "Inactive" ;
VAL_ 2556297386 P10_BalSwCell119 01 "Active" 00 "Inactive" ;
VAL_ 2556297386 P10_BalSwCell120 01 "Active" 00 "Inactive" ;
VAL_ 2556362922 P10_BalSwCell121 01 "Active" 00 "Inactive" ;
VAL_ 2556362922 P10_BalSwCell122 01 "Active" 00 "Inactive" ;
VAL_ 2556362922 P10_BalSwCell123 01 "Active" 00 "Inactive" ;
VAL_ 2556362922 P10_BalSwCell124 01 "Active" 00 "Inactive" ;
VAL_ 2556428458 P10_BalSwCell125 01 "Active" 00 "Inactive" ;
VAL_ 2556428458 P10_BalSwCell126 01 "Active" 00 "Inactive" ;
VAL_ 2556428458 P10_BalSwCell127 01 "Active" 00 "Inactive" ;
VAL_ 2556428458 P10_BalSwCell128 01 "Active" 00 "Inactive" ;
VAL_ 2556493994 P10_BalSwCell129 01 "Active" 00 "Inactive" ;
VAL_ 2556493994 P10_BalSwCell130 01 "Active" 00 "Inactive" ;
VAL_ 2556493994 P10_BalSwCell131 01 "Active" 00 "Inactive" ;
VAL_ 2556493994 P10_BalSwCell132 01 "Active" 00 "Inactive" ;
VAL_ 2556559530 P10_BalSwCell133 01 "Active" 00 "Inactive" ;
VAL_ 2556559530 P10_BalSwCell134 01 "Active" 00 "Inactive" ;
VAL_ 2556559530 P10_BalSwCell135 01 "Active" 00 "Inactive" ;
VAL_ 2556559530 P10_BalSwCell136 01 "Active" 00 "Inactive" ;
VAL_ 2556625066 P10_BalSwCell137 01 "Active" 00 "Inactive" ;
VAL_ 2556625066 P10_BalSwCell138 01 "Active" 00 "Inactive" ;
VAL_ 2556625066 P10_BalSwCell139 01 "Active" 00 "Inactive" ;
VAL_ 2556625066 P10_BalSwCell140 01 "Active" 00 "Inactive" ;
VAL_ 2556690602 P10_BalSwCell141 01 "Active" 00 "Inactive" ;
VAL_ 2556690602 P10_BalSwCell142 01 "Active" 00 "Inactive" ;
VAL_ 2556690602 P10_BalSwCell143 01 "Active" 00 "Inactive" ;
VAL_ 2556690602 P10_BalSwCell144 01 "Active" 00 "Inactive" ;
VAL_ 2556756138 P10_BalSwCell145 01 "Active" 00 "Inactive" ;
VAL_ 2556756138 P10_BalSwCell146 01 "Active" 00 "Inactive" ;
VAL_ 2556756138 P10_BalSwCell147 01 "Active" 00 "Inactive" ;
VAL_ 2556756138 P10_BalSwCell148 01 "Active" 00 "Inactive" ;
VAL_ 2556821674 P10_BalSwCell149 01 "Active" 00 "Inactive" ;
VAL_ 2556821674 P10_BalSwCell150 01 "Active" 00 "Inactive" ;
VAL_ 2556821674 P10_BalSwCell151 01 "Active" 00 "Inactive" ;
VAL_ 2556821674 P10_BalSwCell152 01 "Active" 00 "Inactive" ;
VAL_ 2556887210 P10_BalSwCell153 01 "Active" 00 "Inactive" ;
VAL_ 2556887210 P10_BalSwCell154 01 "Active" 00 "Inactive" ;
VAL_ 2556887210 P10_BalSwCell155 01 "Active" 00 "Inactive" ;
VAL_ 2556887210 P10_BalSwCell156 01 "Active" 00 "Inactive" ;
VAL_ 2556952746 P10_BalSwCell157 01 "Active" 00 "Inactive" ;
VAL_ 2556952746 P10_BalSwCell158 01 "Active" 00 "Inactive" ;
VAL_ 2556952746 P10_BalSwCell159 01 "Active" 00 "Inactive" ;
VAL_ 2556952746 P10_BalSwCell160 01 "Active" 00 "Inactive" ;
VAL_ 2557018282 P10_BalSwCell161 01 "Active" 00 "Inactive" ;
VAL_ 2557018282 P10_BalSwCell162 01 "Active" 00 "Inactive" ;
VAL_ 2557018282 P10_BalSwCell163 01 "Active" 00 "Inactive" ;
VAL_ 2557018282 P10_BalSwCell164 01 "Active" 00 "Inactive" ;
VAL_ 2557083818 P10_BalSwCell165 01 "Active" 00 "Inactive" ;
VAL_ 2557083818 P10_BalSwCell166 01 "Active" 00 "Inactive" ;
VAL_ 2557083818 P10_BalSwCell167 01 "Active" 00 "Inactive" ;
VAL_ 2557083818 P10_BalSwCell168 01 "Active" 00 "Inactive" ;
VAL_ 2557149354 P10_BalSwCell169 01 "Active" 00 "Inactive" ;
VAL_ 2557149354 P10_BalSwCell170 01 "Active" 00 "Inactive" ;
VAL_ 2557149354 P10_BalSwCell171 01 "Active" 00 "Inactive" ;
VAL_ 2557149354 P10_BalSwCell172 01 "Active" 00 "Inactive" ;
VAL_ 2557214890 P10_BalSwCell173 01 "Active" 00 "Inactive" ;
VAL_ 2557214890 P10_BalSwCell174 01 "Active" 00 "Inactive" ;
VAL_ 2557214890 P10_BalSwCell175 01 "Active" 00 "Inactive" ;
VAL_ 2557214890 P10_BalSwCell176 01 "Active" 00 "Inactive" ;
VAL_ 2557280426 P10_BalSwCell177 01 "Active" 00 "Inactive" ;
VAL_ 2557280426 P10_BalSwCell178 01 "Active" 00 "Inactive" ;
VAL_ 2557280426 P10_BalSwCell179 01 "Active" 00 "Inactive" ;
VAL_ 2557280426 P10_BalSwCell180 01 "Active" 00 "Inactive" ;
VAL_ 2557345962 P10_BalSwCell181 01 "Active" 00 "Inactive" ;
VAL_ 2557345962 P10_BalSwCell182 01 "Active" 00 "Inactive" ;
VAL_ 2557345962 P10_BalSwCell183 01 "Active" 00 "Inactive" ;
VAL_ 2557345962 P10_BalSwCell184 01 "Active" 00 "Inactive" ;
VAL_ 2557411498 P10_BalSwCell185 01 "Active" 00 "Inactive" ;
VAL_ 2557411498 P10_BalSwCell186 01 "Active" 00 "Inactive" ;
VAL_ 2557411498 P10_BalSwCell187 01 "Active" 00 "Inactive" ;
VAL_ 2557411498 P10_BalSwCell188 01 "Active" 00 "Inactive" ;
VAL_ 2557477034 P10_BalSwCell189 01 "Active" 00 "Inactive" ;
VAL_ 2557477034 P10_BalSwCell190 01 "Active" 00 "Inactive" ;
VAL_ 2557477034 P10_BalSwCell191 01 "Active" 00 "Inactive" ;
VAL_ 2557477034 P10_BalSwCell192 01 "Active" 00 "Inactive" ;
